VERSION "dbc-export 1 2026.26.6.5"

NS_ :

BS_:

BU_: APP APS BMS CC CMP CMPD CP DAS DI DIF DIR EPBL EPBR EVSE FC GTW HCML HCMR HVP ICR PCS PCS2 PLG PM PMF PMR PTC SCCM SCM SCS SDCR TAS UMC V2G VC VCBATT VCBATT0 VCBATT1 VCBATT2 VCFRONT VCFRONT1 VCFRONT2 VCLEFT VCRIGHT VCSEC

BO_ 537 VCSEC_TPMSData: 7 VCSEC
 SG_ VCSEC_TPMSDataIndex M : 0|3@1+ (1,0) [0|7] "" Vector__XXX
 SG_ VCSEC_TPMSCapabilityPressureInAd m0 : 3|1@1+ (1,0) [0|1] "" Vector__XXX
 SG_ VCSEC_TPMSCapabilityConfigurable m0 : 4|1@1+ (1,0) [0|1] "" Vector__XXX
 SG_ VCSEC_TPMSPressureRateOfChange0 m0 : 5|10@1- (0.02,0) [-10.24|10.22] "kPa/S" Vector__XXX
 SG_ VCSEC_TPMSPressure0 m0 : 15|9@1+ (0.025,0) [0|12.75] "bar" Vector__XXX
 SG_ VCSEC_TPMSTemperature0 m0 : 24|8@1+ (1,-40) [-40|214] "degC" Vector__XXX
 SG_ VCSEC_TPMSBatVoltage0 m0 : 32|8@1+ (0.01,1.5) [1.5|4.04] "V" Vector__XXX
 SG_ VCSEC_TPMSLocation0 m0 : 40|3@1+ (1,0) [0|7] "" Vector__XXX
 SG_ VCSEC_TPMSTemperatureCompensated m0 : 43|9@1+ (0.025,0) [0|12.75] "bar" Vector__XXX
 SG_ VCSEC_TPMSCapabilityPressur_0001 m1 : 3|1@1+ (1,0) [0|1] "" Vector__XXX
 SG_ VCSEC_TPMSCapabilityConfigu_0001 m1 : 4|1@1+ (1,0) [0|1] "" Vector__XXX
 SG_ VCSEC_TPMSPressureRateOfChange1 m1 : 5|10@1- (0.02,0) [-10.24|10.22] "kPa/S" Vector__XXX
 SG_ VCSEC_TPMSPressure1 m1 : 15|9@1+ (0.025,0) [0|12.75] "bar" Vector__XXX
 SG_ VCSEC_TPMSTemperature1 m1 : 24|8@1+ (1,-40) [-40|214] "degC" Vector__XXX
 SG_ VCSEC_TPMSBatVoltage1 m1 : 32|8@1+ (0.01,1.5) [1.5|4.04] "V" Vector__XXX
 SG_ VCSEC_TPMSLocation1 m1 : 40|3@1+ (1,0) [0|7] "" Vector__XXX
 SG_ VCSEC_TPMSTemperatureCompen_0001 m1 : 43|9@1+ (0.025,0) [0|12.75] "bar" Vector__XXX
 SG_ VCSEC_TPMSCapabilityPressur_0002 m2 : 3|1@1+ (1,0) [0|1] "" Vector__XXX
 SG_ VCSEC_TPMSCapabilityConfigu_0002 m2 : 4|1@1+ (1,0) [0|1] "" Vector__XXX
 SG_ VCSEC_TPMSPressureRateOfChange2 m2 : 5|10@1- (0.02,0) [-10.24|10.22] "kPa/S" Vector__XXX
 SG_ VCSEC_TPMSPressure2 m2 : 15|9@1+ (0.025,0) [0|12.75] "bar" Vector__XXX
 SG_ VCSEC_TPMSTemperature2 m2 : 24|8@1+ (1,-40) [-40|214] "degC" Vector__XXX
 SG_ VCSEC_TPMSBatVoltage2 m2 : 32|8@1+ (0.01,1.5) [1.5|4.04] "V" Vector__XXX
 SG_ VCSEC_TPMSLocation2 m2 : 40|3@1+ (1,0) [0|7] "" Vector__XXX
 SG_ VCSEC_TPMSTemperatureCompen_0002 m2 : 43|9@1+ (0.025,0) [0|12.75] "bar" Vector__XXX
 SG_ VCSEC_TPMSCapabilityPressur_0003 m3 : 3|1@1+ (1,0) [0|1] "" Vector__XXX
 SG_ VCSEC_TPMSCapabilityConfigu_0003 m3 : 4|1@1+ (1,0) [0|1] "" Vector__XXX
 SG_ VCSEC_TPMSPressureRateOfChange3 m3 : 5|10@1- (0.02,0) [-10.24|10.22] "kPa/S" Vector__XXX
 SG_ VCSEC_TPMSPressure3 m3 : 15|9@1+ (0.025,0) [0|12.75] "bar" Vector__XXX
 SG_ VCSEC_TPMSTemperature3 m3 : 24|8@1+ (1,-40) [-40|214] "degC" Vector__XXX
 SG_ VCSEC_TPMSBatVoltage3 m3 : 32|8@1+ (0.01,1.5) [1.5|4.04] "V" Vector__XXX
 SG_ VCSEC_TPMSLocation3 m3 : 40|3@1+ (1,0) [0|7] "" Vector__XXX
 SG_ VCSEC_TPMSTemperatureCompen_0003 m3 : 43|9@1+ (0.025,0) [0|12.75] "bar" Vector__XXX
 SG_ VCSEC_TPMSRecommendedColdPressur m4 : 8|8@1+ (0.025,0) [0|6.35] "bar" Vector__XXX
 SG_ VCSEC_TPMSRecommendedColdPr_0001 m4 : 16|8@1+ (0.025,0) [0|6.35] "bar" Vector__XXX
 SG_ VCSEC_TPMSFeature0 m4 : 24|3@1+ (1,0) [0|7] "" Vector__XXX
 SG_ VCSEC_TPMSFeature1 m4 : 27|3@1+ (1,0) [0|7] "" Vector__XXX
 SG_ VCSEC_TPMSFeature0Count m4 : 32|4@1+ (1,0) [0|15] "" Vector__XXX
 SG_ VCSEC_TPMSFeature0TimeS m4 : 36|11@1+ (1,0) [0|2047] "" Vector__XXX
 SG_ VCSEC_TPMSAutonomyStatus m5 : 3|2@1+ (1,0) [0|3] "" Vector__XXX
 SG_ VCSEC_TPMSAutonomyStatusMIATimeS m5 : 5|9@1+ (1,0) [0|511] "" Vector__XXX
 SG_ VCSEC_TPMSLastKnownPressureFL m5 : 16|8@1+ (0.025,0) [0|6.35] "bar" Vector__XXX
 SG_ VCSEC_TPMSLastKnownPressureFR m5 : 24|8@1+ (0.025,0) [0|6.35] "bar" Vector__XXX
 SG_ VCSEC_TPMSLastKnownPressureRL m5 : 32|8@1+ (0.025,0) [0|6.35] "bar" Vector__XXX
 SG_ VCSEC_TPMSLastKnownPressureRR m5 : 40|8@1+ (0.025,0) [0|6.35] "bar" Vector__XXX

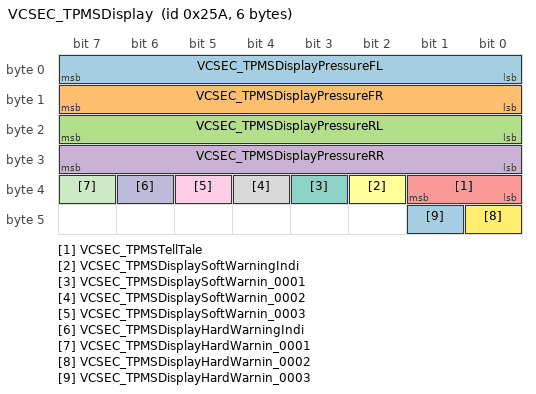
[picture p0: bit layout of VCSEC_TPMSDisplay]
BO_ 602 VCSEC_TPMSDisplay: 6 VCSEC
 SG_ VCSEC_TPMSDisplayPressureFL : 0|8@1+ (0.025,0) [0|6.35] "bar" Vector__XXX
 SG_ VCSEC_TPMSDisplayPressureFR : 8|8@1+ (0.025,0) [0|6.35] "bar" Vector__XXX
 SG_ VCSEC_TPMSDisplayPressureRL : 16|8@1+ (0.025,0) [0|6.35] "bar" Vector__XXX
 SG_ VCSEC_TPMSDisplayPressureRR : 24|8@1+ (0.025,0) [0|6.35] "bar" Vector__XXX
 SG_ VCSEC_TPMSTellTale : 32|2@1+ (1,0) [0|3] "" Vector__XXX
 SG_ VCSEC_TPMSDisplaySoftWarningIndi : 34|1@1+ (1,0) [0|1] "" Vector__XXX
 SG_ VCSEC_TPMSDisplaySoftWarnin_0001 : 35|1@1+ (1,0) [0|1] "" Vector__XXX
 SG_ VCSEC_TPMSDisplaySoftWarnin_0002 : 36|1@1+ (1,0) [0|1] "" Vector__XXX
 SG_ VCSEC_TPMSDisplaySoftWarnin_0003 : 37|1@1+ (1,0) [0|1] "" Vector__XXX
 SG_ VCSEC_TPMSDisplayHardWarningIndi : 38|1@1+ (1,0) [0|1] "" Vector__XXX
 SG_ VCSEC_TPMSDisplayHardWarnin_0001 : 39|1@1+ (1,0) [0|1] "" Vector__XXX
 SG_ VCSEC_TPMSDisplayHardWarnin_0002 : 40|1@1+ (1,0) [0|1] "" Vector__XXX
 SG_ VCSEC_TPMSDisplayHardWarnin_0003 : 41|1@1+ (1,0) [0|1] "" Vector__XXX

BO_ 570 VCSEC_TPMSStatus: 8 VCSEC
 SG_ VCSEC_TPMSStatusIndex M : 0|6@1+ (1,0) [0|63] "" Vector__XXX
 SG_ VCSEC_TPMSSystemState : 6|1@1+ (1,0) [0|1] "" Vector__XXX
 SG_ VCSEC_TPMSSensorMACAddress0 m0 : 8|48@1+ (1,0) [0|281474976710655] "" Vector__XXX
 SG_ VCSEC_TPMSSensorMACAddress1 m1 : 8|48@1+ (1,0) [0|281474976710655] "" Vector__XXX
 SG_ VCSEC_TPMSSensorMACAddress2 m2 : 8|48@1+ (1,0) [0|281474976710655] "" Vector__XXX
 SG_ VCSEC_TPMSSensorMACAddress3 m3 : 8|48@1+ (1,0) [0|281474976710655] "" Vector__XXX
 SG_ VCSEC_BLEUnsuccessfulConnEventRa m5 : 8|10@1+ (0.08,0) [0|81.76] "%" Vector__XXX
 SG_ VCSEC_BLEUnsuccessfulConnEv_0001 m7 : 8|10@1+ (0.08,0) [0|81.76] "%" Vector__XXX
 SG_ VCSEC_BLEUnsuccessfulConnEv_0002 m9 : 8|10@1+ (0.08,0) [0|81.76] "%" Vector__XXX
 SG_ VCSEC_BLEUnsuccessfulConnEv_0003 m11 : 8|10@1+ (0.08,0) [0|81.76] "%" Vector__XXX
 SG_ VCSEC_TPMSSensorTIAppCRC0 m12 : 8|32@1+ (1,0) [1|4294967295] "" Vector__XXX
 SG_ VCSEC_TPMSSensorMLXAppCRC0 m12 : 40|24@1+ (1,0) [1|16777215] "" Vector__XXX
 SG_ VCSEC_TPMSSensorTIAppCRC1 m13 : 8|32@1+ (1,0) [1|4294967295] "" Vector__XXX
 SG_ VCSEC_TPMSSensorMLXAppCRC1 m13 : 40|24@1+ (1,0) [1|16777215] "" Vector__XXX
 SG_ VCSEC_TPMSSensorTIAppCRC2 m14 : 8|32@1+ (1,0) [1|4294967295] "" Vector__XXX
 SG_ VCSEC_TPMSSensorMLXAppCRC2 m14 : 40|24@1+ (1,0) [1|16777215] "" Vector__XXX
 SG_ VCSEC_TPMSSensorTIAppCRC3 m15 : 8|32@1+ (1,0) [1|4294967295] "" Vector__XXX
 SG_ VCSEC_TPMSSensorMLXAppCRC3 m15 : 40|24@1+ (1,0) [1|16777215] "" Vector__XXX
 SG_ VCSEC_TPMStotalAwakeTime0 m20 : 8|32@1+ (1,0) [0|4294967295] "" Vector__XXX
 SG_ VCSEC_TPMSTrimAdjusted0 m20 : 40|1@1+ (1,0) [0|1] "" Vector__XXX
 SG_ VCSEC_TPMSGenealogySensorState0 m20 : 41|3@1+ (1,0) [0|7] "" Vector__XXX
 SG_ VCSEC_TPMSSensorType0 m20 : 44|3@1+ (1,0) [0|7] "" Vector__XXX
 SG_ VCSEC_TPMStotalAwakeTime1 m21 : 8|32@1+ (1,0) [0|4294967295] "" Vector__XXX
 SG_ VCSEC_TPMSTrimAdjusted1 m21 : 40|1@1+ (1,0) [0|1] "" Vector__XXX
 SG_ VCSEC_TPMSGenealogySensorState1 m21 : 41|3@1+ (1,0) [0|7] "" Vector__XXX
 SG_ VCSEC_TPMSSensorType1 m21 : 44|3@1+ (1,0) [0|7] "" Vector__XXX
 SG_ VCSEC_TPMStotalAwakeTime2 m22 : 8|32@1+ (1,0) [0|4294967295] "" Vector__XXX
 SG_ VCSEC_TPMSTrimAdjusted2 m22 : 40|1@1+ (1,0) [0|1] "" Vector__XXX
 SG_ VCSEC_TPMSGenealogySensorState2 m22 : 41|3@1+ (1,0) [0|7] "" Vector__XXX
 SG_ VCSEC_TPMSSensorType2 m22 : 44|3@1+ (1,0) [0|7] "" Vector__XXX
 SG_ VCSEC_TPMStotalAwakeTime3 m23 : 8|32@1+ (1,0) [0|4294967295] "" Vector__XXX
 SG_ VCSEC_TPMSTrimAdjusted3 m23 : 40|1@1+ (1,0) [0|1] "" Vector__XXX
 SG_ VCSEC_TPMSGenealogySensorState3 m23 : 41|3@1+ (1,0) [0|7] "" Vector__XXX
 SG_ VCSEC_TPMSSensorType3 m23 : 44|3@1+ (1,0) [0|7] "" Vector__XXX
 SG_ VCSEC_TPMSSensor0Hash m33 : 8|28@1+ (1,0) [0|268435455] "" Vector__XXX
 SG_ VCSEC_TPMSSensor1Hash m33 : 36|28@1+ (1,0) [0|268435455] "" Vector__XXX
 SG_ VCSEC_TPMSSensor2Hash m34 : 8|28@1+ (1,0) [0|268435455] "" Vector__XXX
 SG_ VCSEC_TPMSSensor3Hash m34 : 36|28@1+ (1,0) [0|268435455] "" Vector__XXX
 SG_ VCSEC_TPMSLastLocationSensor0 m35 : 8|3@1+ (1,0) [0|7] "" Vector__XXX
 SG_ VCSEC_TPMSLastLocationSensor1 m35 : 11|3@1+ (1,0) [0|7] "" Vector__XXX
 SG_ VCSEC_TPMSLastLocationSensor2 m35 : 16|3@1+ (1,0) [0|7] "" Vector__XXX
 SG_ VCSEC_TPMSLastLocationSensor3 m35 : 19|3@1+ (1,0) [0|7] "" Vector__XXX
 SG_ VCSEC_TPMSTemperatureCompensated m36 : 8|8@1+ (0.01,1.5) [1.5|4.04] "V" Vector__XXX
 SG_ VCSEC_TPMSTemperatureCompen_0001 m36 : 16|8@1+ (0.01,1.5) [1.5|4.04] "V" Vector__XXX
 SG_ VCSEC_TPMSTemperatureCompen_0002 m36 : 24|8@1+ (0.01,1.5) [1.5|4.04] "V" Vector__XXX
 SG_ VCSEC_TPMSTemperatureCompen_0003 m36 : 32|8@1+ (0.01,1.5) [1.5|4.04] "V" Vector__XXX
 SG_ VCSEC_TPMSFilteredBatVoltage0 m37 : 8|8@1+ (0.01,1.5) [1.5|4.04] "V" Vector__XXX
 SG_ VCSEC_TPMSFilteredBatVoltage2 m37 : 16|8@1+ (0.01,1.5) [1.5|4.04] "V" Vector__XXX
 SG_ VCSEC_TPMSFilteredBatVoltage1 m37 : 24|8@1+ (0.01,1.5) [1.5|4.04] "V" Vector__XXX
 SG_ VCSEC_TPMSFilteredBatVoltage3 m37 : 32|8@1+ (0.01,1.5) [1.5|4.04] "V" Vector__XXX

BO_ 1067 VCSEC_UWBData: 8 VCSEC
 SG_ VCSEC_UWBEndpointIndex M : 0|3@1+ (1,0) [0|7] "" Vector__XXX
 SG_ VCSEC_UWBExpectedEndpointsActive m0 : 3|4@1+ (1,0) [0|15] "" Vector__XXX
 SG_ VCSEC_UWBExpectedEndpointsA_0001 m0 : 8|4@1+ (1,0) [0|15] "" Vector__XXX
 SG_ VCSEC_UWBExpectedEndpointsA_0002 m0 : 12|4@1+ (1,0) [0|15] "" Vector__XXX
 SG_ VCSEC_UWBExpectedEndpointsA_0003 m0 : 16|4@1+ (1,0) [0|15] "" Vector__XXX
 SG_ VCSEC_UWBRearRightDistance0 m0 : 20|12@1+ (1,0) [0|4094] "cm" Vector__XXX
 SG_ VCSEC_UWBRearRightDistance1 m0 : 32|12@1+ (1,0) [0|4094] "cm" Vector__XXX
 SG_ VCSEC_UWBRearRightDistance2 m0 : 44|12@1+ (1,0) [0|4094] "cm" Vector__XXX
 SG_ VCSEC_UWBLeftDistance3 m1 : 3|12@1+ (1,0) [0|4094] "cm" Vector__XXX
 SG_ VCSEC_UWBRightDistance3 m1 : 16|12@1+ (1,0) [0|4094] "cm" Vector__XXX
 SG_ VCSEC_UWBRearRightDistance3 m1 : 28|12@1+ (1,0) [0|4094] "cm" Vector__XXX
 SG_ VCSEC_UWBRearLeftDistance3 m1 : 40|12@1+ (1,0) [0|4094] "cm" Vector__XXX
 SG_ VCSEC_UWBCenterDistance3 m1 : 52|12@1+ (1,0) [0|4094] "cm" Vector__XXX
 SG_ VCSEC_UWBLeftDistance2 m2 : 3|12@1+ (1,0) [0|4094] "cm" Vector__XXX
 SG_ VCSEC_UWBRightDistance2 m2 : 16|12@1+ (1,0) [0|4094] "cm" Vector__XXX
 SG_ VCSEC_UWBRearDistance2 m2 : 28|12@1+ (1,0) [0|4094] "cm" Vector__XXX
 SG_ VCSEC_UWBRearLeftDistance2 m2 : 40|12@1+ (1,0) [0|4094] "cm" Vector__XXX
 SG_ VCSEC_UWBCenterDistance2 m2 : 52|12@1+ (1,0) [0|4094] "cm" Vector__XXX
 SG_ VCSEC_UWBLeftDistance1 m3 : 3|12@1+ (1,0) [0|4094] "cm" Vector__XXX
 SG_ VCSEC_UWBRightDistance1 m3 : 16|12@1+ (1,0) [0|4094] "cm" Vector__XXX
 SG_ VCSEC_UWBRearDistance1 m3 : 28|12@1+ (1,0) [0|4094] "cm" Vector__XXX
 SG_ VCSEC_UWBRearLeftDistance1 m3 : 40|12@1+ (1,0) [0|4094] "cm" Vector__XXX
 SG_ VCSEC_UWBCenterDistance1 m3 : 52|12@1+ (1,0) [0|4094] "cm" Vector__XXX
 SG_ VCSEC_UWBLeftDistance0 m4 : 3|12@1+ (1,0) [0|4094] "cm" Vector__XXX
 SG_ VCSEC_UWBRightDistance0 m4 : 16|12@1+ (1,0) [0|4094] "cm" Vector__XXX
 SG_ VCSEC_UWBRearDistance0 m4 : 28|12@1+ (1,0) [0|4094] "cm" Vector__XXX
 SG_ VCSEC_UWBRearLeftDistance0 m4 : 40|12@1+ (1,0) [0|4094] "cm" Vector__XXX
 SG_ VCSEC_UWBCenterDistance0 m4 : 52|12@1+ (1,0) [0|4094] "cm" Vector__XXX

BO_ 761 VCSEC_additionalAuthInfo: 8 VCSEC
 SG_ VCSEC_activeKeyDebug : 2|5@1+ (1,0) [0|31] "" Vector__XXX
 SG_ VCSEC_bleChannelDisconnected : 7|4@1+ (1,0) [0|15] "" Vector__XXX
 SG_ VCSEC_bleDisconnectionReason : 11|8@1+ (1,0) [0|255] "" Vector__XXX
 SG_ VCSEC_bleConnetionAttemptWLEntry : 19|5@1+ (1,0) [0|31] "" Vector__XXX
 SG_ VCSEC_AdditionalAuthInfoIndex M : 27|3@1+ (1,0) [0|7] "" Vector__XXX
 SG_ VCSEC_activeKeyReason m0 : 24|3@1+ (1,0) [0|7] "" Vector__XXX
 SG_ VCSEC_activeKeySHA1 m0 : 32|32@1+ (1,0) [0|4294967295] "" Vector__XXX
 SG_ VCSEC_algoUsedForSummonRange0 m1 : 0|1@1+ (1,0) [0|1] "" Vector__XXX
 SG_ VCSEC_keyWithinSummonRange0 m1 : 32|32@1+ (1,0) [0|4294967295] "" Vector__XXX
 SG_ VCSEC_algoUsedForSummonRange1 m2 : 0|1@1+ (1,0) [0|1] "" Vector__XXX
 SG_ VCSEC_keyWithinSummonRange1 m2 : 32|32@1+ (1,0) [0|4294967295] "" Vector__XXX
 SG_ VCSEC_algoUsedForSummonRange2 m3 : 0|1@1+ (1,0) [0|1] "" Vector__XXX
 SG_ VCSEC_keyWithinSummonRange2 m3 : 32|32@1+ (1,0) [0|4294967295] "" Vector__XXX
 SG_ VCSEC_BLEDeviceWithinSummonRange m4 : 32|32@1+ (1,0) [0|4294967295] "" Vector__XXX
 SG_ VCSEC_algoUWBInteriorPresence m5 : 0|1@1+ (1,0) [0|1] "" Vector__XXX
 SG_ VCSEC_frunkOpenSuggestionRespons m5 : 24|3@1+ (1,0) [0|7] "" Vector__XXX
 SG_ VCSEC_NFCAuthFromBPillarFormFact m5 : 32|3@1+ (1,0) [0|7] "" Vector__XXX
 SG_ VCSEC_NFCAuthFromCenterConsoleFo m5 : 35|3@1+ (1,0) [0|7] "" Vector__XXX
 SG_ VCSEC_trunkOpenSuggestionRespons m5 : 40|3@1+ (1,0) [0|7] "" Vector__XXX
 SG_ VCSEC_algoTrunkSuggestionRaw m5 : 43|1@1+ (1,0) [0|1] "" Vector__XXX
 SG_ VCSEC_algoTrunkSuggestionProc m5 : 44|1@1+ (1,0) [0|1] "" Vector__XXX
 SG_ VCSEC_algoTrunkSuggestionRearmAl m5 : 45|1@1+ (1,0) [0|1] "" Vector__XXX
 SG_ VCSEC_algoFrunkSuggestionRaw m5 : 46|1@1+ (1,0) [0|1] "" Vector__XXX
 SG_ VCSEC_algoFrunkSuggestionProc m5 : 47|1@1+ (1,0) [0|1] "" Vector__XXX
 SG_ VCSEC_algoFrunkSuggestionRearmAl m5 : 48|1@1+ (1,0) [0|1] "" Vector__XXX

BO_ 1328 VCSEC_alertLog: 8 VCSEC
 SG_ VCSEC_alertID M : 0|10@1+ (1,0) [0|1023] "" Vector__XXX
 SG_ VCSEC_alertState : 15|1@1+ (1,0) [0|1] "" Vector__XXX
 SG_ VCSEC_a001_InternalWatchdog m1 : 16|1@1+ (1,0) [0|1] "" Vector__XXX
 SG_ VCSEC_a010_UnderVoltageDetected m10 : 16|1@1+ (1,0) [0|1] "" Vector__XXX
 SG_ VCSEC_a010_UnderVoltageTimeout m10 : 17|1@1+ (1,0) [0|1] "" Vector__XXX
 SG_ VCSEC_a015_NVMMMemOverflow m15 : 16|1@1+ (1,0) [0|1] "" Vector__XXX
 SG_ VCSEC_a015_NVMMFilesystemError m15 : 17|1@1+ (1,0) [0|1] "" Vector__XXX
 SG_ VCSEC_a015_NVMMRecordIDError m15 : 18|1@1+ (1,0) [0|1] "" Vector__XXX
 SG_ VCSEC_a057_VEH_cpControl m57 : 16|1@1+ (1,0) [0|1] "" Vector__XXX
 SG_ VCSEC_a059_voltageDrop m59 : 16|12@1+ (0.005443676,0) [0|22.29185322] "V" Vector__XXX
 SG_ VCSEC_a059_resistanceEstimate m59 : 28|12@1+ (0.00244,0) [0|9.9918] "Ohms" Vector__XXX
 SG_ VCSEC_a059_current m59 : 40|12@1+ (0.05,0) [0|204.75] "A" Vector__XXX
 SG_ VCSEC_a063_switchChannel m63 : 16|8@1+ (1,0) [0|255] "" Vector__XXX
 SG_ VCSEC_a063_switchType m63 : 24|8@1+ (1,0) [0|255] "" Vector__XXX
 SG_ VCSEC_a063_ADCVoltage m63 : 32|8@1+ (0.025,0) [0|6.375] "V" Vector__XXX
 SG_ VCSEC_a063_disconnected m63 : 40|1@1+ (1,0) [0|1] "" Vector__XXX
 SG_ VCSEC_a063_indeterminate m63 : 41|1@1+ (1,0) [0|1] "" Vector__XXX
 SG_ VCSEC_a063_stuckActive m63 : 42|1@1+ (1,0) [0|1] "" Vector__XXX
 SG_ VCSEC_a063_faulted m63 : 43|1@1+ (1,0) [0|1] "" Vector__XXX
 SG_ VCSEC_a082_RIPC_epbPrivateState m82 : 16|1@1+ (1,0) [0|1] "" Vector__XXX
 SG_ VCSEC_a082_RIPC_remoteHSD m82 : 17|1@1+ (1,0) [0|1] "" Vector__XXX
 SG_ VCSEC_a082_RIPC_railStatus m82 : 18|1@1+ (1,0) [0|1] "" Vector__XXX
 SG_ VCSEC_a082_RIPC_remoteMux m82 : 19|1@1+ (1,0) [0|1] "" Vector__XXX
 SG_ VCSEC_a083_LIPC_epbPrivateState m83 : 16|1@1+ (1,0) [0|1] "" Vector__XXX
 SG_ VCSEC_a083_LIPC_remoteHSD m83 : 17|1@1+ (1,0) [0|1] "" Vector__XXX
 SG_ VCSEC_a083_LIPC_railStatus m83 : 18|1@1+ (1,0) [0|1] "" Vector__XXX
 SG_ VCSEC_a083_LIPC_HSDFaults m83 : 19|1@1+ (1,0) [0|1] "" Vector__XXX
 SG_ VCSEC_a084_CH_StatusC m84 : 16|1@1+ (1,0) [0|1] "" Vector__XXX
 SG_ VCSEC_a085_PARTY_buttonStatus m85 : 16|1@1+ (1,0) [0|1] "" Vector__XXX
 SG_ VCSEC_a086_VEH_LVBMS_statusHigh m86 : 16|1@1+ (1,0) [0|1] "" Vector__XXX
 SG_ VCSEC_a086_VEH_LVBMS_statusLow m86 : 17|1@1+ (1,0) [0|1] "" Vector__XXX
 SG_ VCSEC_a086_VEH_status m86 : 18|1@1+ (1,0) [0|1] "" Vector__XXX
 SG_ VCSEC_a086_VEH_12VBatteryStatus m86 : 19|1@1+ (1,0) [0|1] "" Vector__XXX
 SG_ VCSEC_a086_VEH_LVPowerState m86 : 20|1@1+ (1,0) [0|1] "" Vector__XXX
 SG_ VCSEC_a086_VEH_lightStatus m86 : 21|1@1+ (1,0) [0|1] "" Vector__XXX
 SG_ VCSEC_a086_VEH_systemStatus m86 : 22|1@1+ (1,0) [0|1] "" Vector__XXX
 SG_ VCSEC_a086_VEH_thermalStatus m86 : 23|1@1+ (1,0) [0|1] "" Vector__XXX
 SG_ VCSEC_a086_VEH_vehNm m86 : 24|1@1+ (1,0) [0|1] "" Vector__XXX
 SG_ VCSEC_a087_VEH_temperature m87 : 16|1@1+ (1,0) [0|1] "" Vector__XXX
 SG_ VCSEC_a087_VEH_thermalControl m87 : 17|1@1+ (1,0) [0|1] "" Vector__XXX
 SG_ VCSEC_a087_VEH_torque m87 : 18|1@1+ (1,0) [0|1] "" Vector__XXX
 SG_ VCSEC_a087_VEH_status m87 : 19|1@1+ (1,0) [0|1] "" Vector__XXX
 SG_ VCSEC_a087_PARTY_torque m87 : 20|1@1+ (1,0) [0|1] "" Vector__XXX
 SG_ VCSEC_a087_PARTY_status m87 : 21|1@1+ (1,0) [0|1] "" Vector__XXX
 SG_ VCSEC_a087_PARTY_temperature m87 : 22|1@1+ (1,0) [0|1] "" Vector__XXX
 SG_ VCSEC_a087_PARTY_thermalControl m87 : 23|1@1+ (1,0) [0|1] "" Vector__XXX
 SG_ VCSEC_a087_VEH_motorStatus m87 : 24|1@1+ (1,0) [0|1] "" Vector__XXX
 SG_ VCSEC_a088_VEH_temperature m88 : 16|1@1+ (1,0) [0|1] "" Vector__XXX
 SG_ VCSEC_a088_VEH_thermalControl m88 : 17|1@1+ (1,0) [0|1] "" Vector__XXX
 SG_ VCSEC_a088_VEH_torque m88 : 18|1@1+ (1,0) [0|1] "" Vector__XXX
 SG_ VCSEC_a088_VEH_status m88 : 19|1@1+ (1,0) [0|1] "" Vector__XXX
 SG_ VCSEC_a088_PARTY_torque m88 : 20|1@1+ (1,0) [0|1] "" Vector__XXX
 SG_ VCSEC_a088_PARTY_status m88 : 21|1@1+ (1,0) [0|1] "" Vector__XXX
 SG_ VCSEC_a088_PARTY_temperature m88 : 22|1@1+ (1,0) [0|1] "" Vector__XXX
 SG_ VCSEC_a088_PARTY_thermalControl m88 : 23|1@1+ (1,0) [0|1] "" Vector__XXX
 SG_ VCSEC_a088_VEH_motorStatus m88 : 24|1@1+ (1,0) [0|1] "" Vector__XXX
 SG_ VCSEC_a089_PARTY_party1 m89 : 16|1@1+ (1,0) [0|1] "" Vector__XXX
 SG_ VCSEC_a089_PARTY_status m89 : 17|1@1+ (1,0) [0|1] "" Vector__XXX
 SG_ VCSEC_a089_VEH_status m89 : 18|1@1+ (1,0) [0|1] "" Vector__XXX
 SG_ VCSEC_a089_BDY_party1 m89 : 19|1@1+ (1,0) [0|1] "" Vector__XXX
 SG_ VCSEC_a089_BDY_status m89 : 20|1@1+ (1,0) [0|1] "" Vector__XXX
 SG_ VCSEC_a089_CH_status m89 : 21|1@1+ (1,0) [0|1] "" Vector__XXX
 SG_ VCSEC_a089_CH_party1 m89 : 22|1@1+ (1,0) [0|1] "" Vector__XXX
 SG_ VCSEC_a089_CH_party3 m89 : 23|1@1+ (1,0) [0|1] "" Vector__XXX
 SG_ VCSEC_a089_VEH_party1 m89 : 24|1@1+ (1,0) [0|1] "" Vector__XXX
 SG_ VCSEC_a089_VEH_party3 m89 : 25|1@1+ (1,0) [0|1] "" Vector__XXX
 SG_ VCSEC_a091_VEH_faultsAndExtras m91 : 16|1@1+ (1,0) [0|1] "" Vector__XXX
 SG_ VCSEC_a091_VEH_info m91 : 17|1@1+ (1,0) [0|1] "" Vector__XXX
 SG_ VCSEC_a091_VEH_state m91 : 18|1@1+ (1,0) [0|1] "" Vector__XXX
 SG_ VCSEC_a092_VEH_restraintStatus m92 : 16|1@1+ (1,0) [0|1] "" Vector__XXX
 SG_ VCSEC_a092_VEH_switchStatus m92 : 17|1@1+ (1,0) [0|1] "" Vector__XXX
 SG_ VCSEC_a092_VEH_seatStatus2 m92 : 18|1@1+ (1,0) [0|1] "" Vector__XXX
 SG_ VCSEC_a092_VEH_vehNm m92 : 19|1@1+ (1,0) [0|1] "" Vector__XXX
 SG_ VCSEC_a093_VEH_restraintStatus m93 : 16|1@1+ (1,0) [0|1] "" Vector__XXX
 SG_ VCSEC_a093_VEH_switchStatus m93 : 17|1@1+ (1,0) [0|1] "" Vector__XXX
 SG_ VCSEC_a093_VEH_seatStatus2 m93 : 18|1@1+ (1,0) [0|1] "" Vector__XXX
 SG_ VCSEC_a093_VEH_vehNm m93 : 19|1@1+ (1,0) [0|1] "" Vector__XXX
 SG_ VCSEC_a094_VEH_sysStatus m94 : 16|1@1+ (1,0) [0|1] "" Vector__XXX
 SG_ VCSEC_a094_PARTY_sysStatus m94 : 17|1@1+ (1,0) [0|1] "" Vector__XXX
 SG_ VCSEC_a094_CH_sysStatus m94 : 18|1@1+ (1,0) [0|1] "" Vector__XXX
 SG_ VCSEC_a095_PT_ptNm m95 : 16|1@1+ (1,0) [0|1] "" Vector__XXX
 SG_ VCSEC_a095_PT_status m95 : 17|1@1+ (1,0) [0|1] "" Vector__XXX
 SG_ VCSEC_a096_VEH_status m96 : 16|1@1+ (1,0) [0|1] "" Vector__XXX
 SG_ VCSEC_a096_CH_status m96 : 17|1@1+ (1,0) [0|1] "" Vector__XXX
 SG_ VCSEC_a097_VEH_HVStatus m97 : 16|1@1+ (1,0) [0|1] "" Vector__XXX
 SG_ VCSEC_a097_VEH_state m97 : 17|1@1+ (1,0) [0|1] "" Vector__XXX
 SG_ VCSEC_a098_CH_torque m98 : 16|1@1+ (1,0) [0|1] "" Vector__XXX
 SG_ VCSEC_a098_VEH_hvStatus m98 : 17|1@1+ (1,0) [0|1] "" Vector__XXX
 SG_ VCSEC_a098_VEH_status m98 : 18|1@1+ (1,0) [0|1] "" Vector__XXX
 SG_ VCSEC_a098_VEH_thermalControl m98 : 19|1@1+ (1,0) [0|1] "" Vector__XXX
 SG_ VCSEC_a098_VEH_temperature m98 : 20|1@1+ (1,0) [0|1] "" Vector__XXX
 SG_ VCSEC_a098_VEH_torque m98 : 21|1@1+ (1,0) [0|1] "" Vector__XXX
 SG_ VCSEC_a098_PARTY_status m98 : 22|1@1+ (1,0) [0|1] "" Vector__XXX
 SG_ VCSEC_a098_PARTY_temperature m98 : 23|1@1+ (1,0) [0|1] "" Vector__XXX
 SG_ VCSEC_a098_PARTY_thermalControl m98 : 24|1@1+ (1,0) [0|1] "" Vector__XXX
 SG_ VCSEC_a098_PARTY_torque m98 : 25|1@1+ (1,0) [0|1] "" Vector__XXX
 SG_ VCSEC_a098_PT_thermalControl m98 : 26|1@1+ (1,0) [0|1] "" Vector__XXX
 SG_ VCSEC_a098_PT_temperature m98 : 27|1@1+ (1,0) [0|1] "" Vector__XXX
 SG_ VCSEC_a098_PARTY_motorStatus m98 : 28|1@1+ (1,0) [0|1] "" Vector__XXX
 SG_ VCSEC_a098_VEH_motorStatus m98 : 29|1@1+ (1,0) [0|1] "" Vector__XXX
 SG_ VCSEC_a099_VEH_oocStatus m99 : 16|1@1+ (1,0) [0|1] "" Vector__XXX
 SG_ VCSEC_a100_VEH m100 : 16|1@1+ (1,0) [0|1] "" Vector__XXX
 SG_ VCSEC_a100_PARTY m100 : 17|1@1+ (1,0) [0|1] "" Vector__XXX
 SG_ VCSEC_a100_PT m100 : 18|1@1+ (1,0) [0|1] "" Vector__XXX
 SG_ VCSEC_a100_CH m100 : 19|1@1+ (1,0) [0|1] "" Vector__XXX
 SG_ VCSEC_a100_OBD m100 : 20|1@1+ (1,0) [0|1] "" Vector__XXX
 SG_ VCSEC_a101_VEH_state m101 : 16|1@1+ (1,0) [0|1] "" Vector__XXX
 SG_ VCSEC_a101_PARTY_locState m101 : 17|1@1+ (1,0) [0|1] "" Vector__XXX
 SG_ VCSEC_a101_LIPC_externalWatchdog m101 : 18|1@1+ (1,0) [0|1] "" Vector__XXX
 SG_ VCSEC_a101_VEH_locState m101 : 19|1@1+ (1,0) [0|1] "" Vector__XXX
 SG_ VCSEC_a101_BDY_locState m101 : 20|1@1+ (1,0) [0|1] "" Vector__XXX
 SG_ VCSEC_a102_VEH_faultsAndExtras m102 : 16|1@1+ (1,0) [0|1] "" Vector__XXX
 SG_ VCSEC_a102_VEH_feedbackStatus m102 : 17|1@1+ (1,0) [0|1] "" Vector__XXX
 SG_ VCSEC_a102_VEH_sensorStatus m102 : 18|1@1+ (1,0) [0|1] "" Vector__XXX
 SG_ VCSEC_a102_VEH_rods m102 : 19|1@1+ (1,0) [0|1] "" Vector__XXX
 SG_ VCSEC_a103_VEH_hvsNm m103 : 16|1@1+ (1,0) [0|1] "" Vector__XXX
 SG_ VCSEC_a103_VEH_vehNm m103 : 17|1@1+ (1,0) [0|1] "" Vector__XXX
 SG_ VCSEC_a103_VEH_status m103 : 18|1@1+ (1,0) [0|1] "" Vector__XXX
 SG_ VCSEC_a103_PT_ptNm m103 : 19|1@1+ (1,0) [0|1] "" Vector__XXX
 SG_ VCSEC_a103_PT_status m103 : 20|1@1+ (1,0) [0|1] "" Vector__XXX
 SG_ VCSEC_a103_VEH_evseStatus m103 : 21|1@1+ (1,0) [0|1] "" Vector__XXX
 SG_ VCSEC_a105_VEH_states m105 : 16|1@1+ (1,0) [0|1] "" Vector__XXX
 SG_ VCSEC_a105_VEH_chNm m105 : 17|1@1+ (1,0) [0|1] "" Vector__XXX
 SG_ VCSEC_a105_VEH_dampingStates m105 : 18|1@1+ (1,0) [0|1] "" Vector__XXX
 SG_ VCSEC_a106_VEH_dcdcStatus m106 : 16|1@1+ (1,0) [0|1] "" Vector__XXX
 SG_ VCSEC_a106_VEH_thermalControl m106 : 17|1@1+ (1,0) [0|1] "" Vector__XXX
 SG_ VCSEC_a106_VEH_dcdcRailStatus m106 : 18|1@1+ (1,0) [0|1] "" Vector__XXX
 SG_ VCSEC_a106_CH_dcdcRailStatus m106 : 19|1@1+ (1,0) [0|1] "" Vector__XXX
 SG_ VCSEC_a106_CH_alertMatrix m106 : 20|1@1+ (1,0) [0|1] "" Vector__XXX
 SG_ VCSEC_a107_VEH_hvsNm m107 : 16|1@1+ (1,0) [0|1] "" Vector__XXX
 SG_ VCSEC_a107_VEH_vehNm m107 : 17|1@1+ (1,0) [0|1] "" Vector__XXX
 SG_ VCSEC_a107_VEH_status m107 : 18|1@1+ (1,0) [0|1] "" Vector__XXX
 SG_ VCSEC_a107_VEH_thermalStatus m107 : 19|1@1+ (1,0) [0|1] "" Vector__XXX
 SG_ VCSEC_a107_VEH_bmbMinMax m107 : 20|1@1+ (1,0) [0|1] "" Vector__XXX
 SG_ VCSEC_a107_VEH_powerAvailable m107 : 21|1@1+ (1,0) [0|1] "" Vector__XXX
 SG_ VCSEC_a107_PT_ptNm m107 : 22|1@1+ (1,0) [0|1] "" Vector__XXX
 SG_ VCSEC_a107_PT_status m107 : 23|1@1+ (1,0) [0|1] "" Vector__XXX
 SG_ VCSEC_a107_PT_thermalStatus m107 : 24|1@1+ (1,0) [0|1] "" Vector__XXX
 SG_ VCSEC_a107_PT_socStatus m107 : 25|1@1+ (1,0) [0|1] "" Vector__XXX
 SG_ VCSEC_a107_VEH_socStatus m107 : 26|1@1+ (1,0) [0|1] "" Vector__XXX
 SG_ VCSEC_a107_VEH_packConfig m107 : 27|1@1+ (1,0) [0|1] "" Vector__XXX
 SG_ VCSEC_a107_VEH_energyStatus m107 : 28|1@1+ (1,0) [0|1] "" Vector__XXX
 SG_ VCSEC_a107_VEH_chargeInfo m107 : 29|1@1+ (1,0) [0|1] "" Vector__XXX
 SG_ VCSEC_a108_VEH_hvStatus m108 : 16|1@1+ (1,0) [0|1] "" Vector__XXX
 SG_ VCSEC_a108_VEH_temperature m108 : 17|1@1+ (1,0) [0|1] "" Vector__XXX
 SG_ VCSEC_a108_VEH_thermalControl m108 : 18|1@1+ (1,0) [0|1] "" Vector__XXX
 SG_ VCSEC_a108_VEH_torque m108 : 19|1@1+ (1,0) [0|1] "" Vector__XXX
 SG_ VCSEC_a108_VEH_status m108 : 20|1@1+ (1,0) [0|1] "" Vector__XXX
 SG_ VCSEC_a108_PARTY_torque m108 : 21|1@1+ (1,0) [0|1] "" Vector__XXX
 SG_ VCSEC_a108_PARTY_status m108 : 22|1@1+ (1,0) [0|1] "" Vector__XXX
 SG_ VCSEC_a108_PARTY_temperature m108 : 23|1@1+ (1,0) [0|1] "" Vector__XXX
 SG_ VCSEC_a108_PARTY_thermalControl m108 : 24|1@1+ (1,0) [0|1] "" Vector__XXX
 SG_ VCSEC_a108_PT_temperature m108 : 25|1@1+ (1,0) [0|1] "" Vector__XXX
 SG_ VCSEC_a108_PT_thermalControl m108 : 26|1@1+ (1,0) [0|1] "" Vector__XXX
 SG_ VCSEC_a108_PARTY_motorStatus m108 : 27|1@1+ (1,0) [0|1] "" Vector__XXX
 SG_ VCSEC_a108_VEH_motorStatus m108 : 28|1@1+ (1,0) [0|1] "" Vector__XXX
 SG_ VCSEC_a108_CH_torque m108 : 29|1@1+ (1,0) [0|1] "" Vector__XXX
 SG_ VCSEC_a110_VEH_carState m110 : 16|1@1+ (1,0) [0|1] "" Vector__XXX
 SG_ VCSEC_a110_VEH_carConfig m110 : 17|1@1+ (1,0) [0|1] "" Vector__XXX
 SG_ VCSEC_a110_VEH_time m110 : 18|1@1+ (1,0) [0|1] "" Vector__XXX
 SG_ VCSEC_a110_VEH_updateStatus m110 : 19|1@1+ (1,0) [0|1] "" Vector__XXX
 SG_ VCSEC_a110_VEH_vehNm m110 : 20|1@1+ (1,0) [0|1] "" Vector__XXX
 SG_ VCSEC_a110_VEH_mismatchFault m110 : 21|1@1+ (1,0) [0|1] "" Vector__XXX
 SG_ VCSEC_a110_VEH_vin m110 : 22|1@1+ (1,0) [0|1] "" Vector__XXX
 SG_ VCSEC_a110_VEH_bmpDebug m110 : 23|1@1+ (1,0) [0|1] "" Vector__XXX
 SG_ VCSEC_a110_VEH_gearControl m110 : 24|1@1+ (1,0) [0|1] "" Vector__XXX
 SG_ VCSEC_a110_VEH_canLogAvailabilit m110 : 25|1@1+ (1,0) [0|1] "" Vector__XXX
 SG_ VCSEC_a110_CH_airbagCutoffStatus m110 : 26|1@1+ (1,0) [0|1] "" Vector__XXX
 SG_ VCSEC_a110_CH_carConfig m110 : 27|1@1+ (1,0) [0|1] "" Vector__XXX
 SG_ VCSEC_a110_CH_carState m110 : 28|1@1+ (1,0) [0|1] "" Vector__XXX
 SG_ VCSEC_a110_CH_vin m110 : 29|1@1+ (1,0) [0|1] "" Vector__XXX
 SG_ VCSEC_a110_CH_chNm m110 : 30|1@1+ (1,0) [0|1] "" Vector__XXX
 SG_ VCSEC_a110_CH_epochTimeGtw m110 : 31|1@1+ (1,0) [0|1] "" Vector__XXX
 SG_ VCSEC_a110_PARTY_carConfig m110 : 32|1@1+ (1,0) [0|1] "" Vector__XXX
 SG_ VCSEC_a111_VEH_internalStatus m111 : 16|1@1+ (1,0) [0|1] "" Vector__XXX
 SG_ VCSEC_a111_VEH_status m111 : 17|1@1+ (1,0) [0|1] "" Vector__XXX
 SG_ VCSEC_a111_VEH_vehNm m111 : 18|1@1+ (1,0) [0|1] "" Vector__XXX
 SG_ VCSEC_a111_RIPC_LVPowerState m111 : 19|1@1+ (1,0) [0|1] "" Vector__XXX
 SG_ VCSEC_a111_RIPC_epbPrivateState m111 : 20|1@1+ (1,0) [0|1] "" Vector__XXX
 SG_ VCSEC_a111_RIPC_railStatus m111 : 21|1@1+ (1,0) [0|1] "" Vector__XXX
 SG_ VCSEC_a111_RIPC_remoteADC m111 : 22|1@1+ (1,0) [0|1] "" Vector__XXX
 SG_ VCSEC_a111_RIPC_switchStatus m111 : 23|1@1+ (1,0) [0|1] "" Vector__XXX
 SG_ VCSEC_a111_VEH_LVPowerState m111 : 24|1@1+ (1,0) [0|1] "" Vector__XXX
 SG_ VCSEC_a111_VEH_seatStatus m111 : 25|1@1+ (1,0) [0|1] "" Vector__XXX
 SG_ VCSEC_a111_PARTY_status m111 : 26|1@1+ (1,0) [0|1] "" Vector__XXX
 SG_ VCSEC_a111_CH_status m111 : 27|1@1+ (1,0) [0|1] "" Vector__XXX
 SG_ VCSEC_a112_VEH_internalStatus m112 : 16|1@1+ (1,0) [0|1] "" Vector__XXX
 SG_ VCSEC_a112_VEH_status m112 : 17|1@1+ (1,0) [0|1] "" Vector__XXX
 SG_ VCSEC_a112_VEH_vehNm m112 : 18|1@1+ (1,0) [0|1] "" Vector__XXX
 SG_ VCSEC_a112_LIPC_LVPowerState m112 : 19|1@1+ (1,0) [0|1] "" Vector__XXX
 SG_ VCSEC_a112_LIPC_epbPrivateState m112 : 20|1@1+ (1,0) [0|1] "" Vector__XXX
 SG_ VCSEC_a112_LIPC_railStatus m112 : 21|1@1+ (1,0) [0|1] "" Vector__XXX
 SG_ VCSEC_a112_LIPC_remoteADC m112 : 22|1@1+ (1,0) [0|1] "" Vector__XXX
 SG_ VCSEC_a112_LIPC_switchStatus m112 : 23|1@1+ (1,0) [0|1] "" Vector__XXX
 SG_ VCSEC_a112_VEH_LVPowerState m112 : 24|1@1+ (1,0) [0|1] "" Vector__XXX
 SG_ VCSEC_a112_PARTY_status m112 : 25|1@1+ (1,0) [0|1] "" Vector__XXX
 SG_ VCSEC_a112_CH_status m112 : 26|1@1+ (1,0) [0|1] "" Vector__XXX
 SG_ VCSEC_a114_PARTY_status m114 : 16|1@1+ (1,0) [0|1] "" Vector__XXX
 SG_ VCSEC_a114_PARTY_wheelSpeeds m114 : 17|1@1+ (1,0) [0|1] "" Vector__XXX
 SG_ VCSEC_a114_VEH_wheelSpeeds m114 : 18|1@1+ (1,0) [0|1] "" Vector__XXX
 SG_ VCSEC_a114_CH_wheelSpeeds m114 : 19|1@1+ (1,0) [0|1] "" Vector__XXX
 SG_ VCSEC_a114_PARTY_party3 m114 : 20|1@1+ (1,0) [0|1] "" Vector__XXX
 SG_ VCSEC_a114_VEH_party3 m114 : 21|1@1+ (1,0) [0|1] "" Vector__XXX
 SG_ VCSEC_a114_VEH_status m114 : 22|1@1+ (1,0) [0|1] "" Vector__XXX
 SG_ VCSEC_a114_PARTY_wheelRotation m114 : 23|1@1+ (1,0) [0|1] "" Vector__XXX
 SG_ VCSEC_a114_CH_wheelRotation m114 : 24|1@1+ (1,0) [0|1] "" Vector__XXX
 SG_ VCSEC_a114_VEH_wheelRotation m114 : 25|1@1+ (1,0) [0|1] "" Vector__XXX
 SG_ VCSEC_a114_PARTY_brakeTorque m114 : 26|1@1+ (1,0) [0|1] "" Vector__XXX
 SG_ VCSEC_a114_PARTY_offsets m114 : 27|1@1+ (1,0) [0|1] "" Vector__XXX
 SG_ VCSEC_a114_BDY_offsets m114 : 28|1@1+ (1,0) [0|1] "" Vector__XXX
 SG_ VCSEC_a114_BDY_party3 m114 : 29|1@1+ (1,0) [0|1] "" Vector__XXX
 SG_ VCSEC_a114_BDY_status m114 : 30|1@1+ (1,0) [0|1] "" Vector__XXX
 SG_ VCSEC_a114_BDY_wheelRotation m114 : 31|1@1+ (1,0) [0|1] "" Vector__XXX
 SG_ VCSEC_a114_BDY_wheelSpeeds m114 : 32|1@1+ (1,0) [0|1] "" Vector__XXX
 SG_ VCSEC_a114_CH_party1 m114 : 33|1@1+ (1,0) [0|1] "" Vector__XXX
 SG_ VCSEC_a114_CH_party3 m114 : 34|1@1+ (1,0) [0|1] "" Vector__XXX
 SG_ VCSEC_a114_CH_status m114 : 35|1@1+ (1,0) [0|1] "" Vector__XXX
 SG_ VCSEC_a115_VEH_vehNm m115 : 16|1@1+ (1,0) [0|1] "" Vector__XXX
 SG_ VCSEC_a115_VEH_authentication m115 : 17|1@1+ (1,0) [0|1] "" Vector__XXX
 SG_ VCSEC_a115_VEH_BLEResetRequest m115 : 18|1@1+ (1,0) [0|1] "" Vector__XXX
 SG_ VCSEC_a115_VEH_requests m115 : 19|1@1+ (1,0) [0|1] "" Vector__XXX
 SG_ VCSEC_a115_VEH_requests2 m115 : 20|1@1+ (1,0) [0|1] "" Vector__XXX
 SG_ VCSEC_a115_REM_authentication m115 : 21|1@1+ (1,0) [0|1] "" Vector__XXX
 SG_ VCSEC_a115_UI_corianderVehicleCo m115 : 22|1@1+ (1,0) [0|1] "" Vector__XXX
 SG_ VCSEC_a115_CH_TPMSDisplay m115 : 23|1@1+ (1,0) [0|1] "" Vector__XXX
 SG_ VCSEC_a116_PARTY_epbmStatus m116 : 16|1@1+ (1,0) [0|1] "" Vector__XXX
 SG_ VCSEC_a116_VEH_vehNm m116 : 17|1@1+ (1,0) [0|1] "" Vector__XXX
 SG_ VCSEC_a116_VEH_hvacRequest m116 : 18|1@1+ (1,0) [0|1] "" Vector__XXX
 SG_ VCSEC_a116_VEH_hvacStatus m116 : 19|1@1+ (1,0) [0|1] "" Vector__XXX
 SG_ VCSEC_a116_VEH_LVPowerState m116 : 20|1@1+ (1,0) [0|1] "" Vector__XXX
 SG_ VCSEC_a116_VEH_lightStatus m116 : 21|1@1+ (1,0) [0|1] "" Vector__XXX
 SG_ VCSEC_a116_VEH_seatStatus m116 : 22|1@1+ (1,0) [0|1] "" Vector__XXX
 SG_ VCSEC_a116_VEH_thsStatus m116 : 23|1@1+ (1,0) [0|1] "" Vector__XXX
 SG_ VCSEC_a116_VEH_doorStatus m116 : 24|1@1+ (1,0) [0|1] "" Vector__XXX
 SG_ VCSEC_a116_VEH_seatHeatStatus m116 : 25|1@1+ (1,0) [0|1] "" Vector__XXX
 SG_ VCSEC_a116_VEH_restraintStatus m116 : 26|1@1+ (1,0) [0|1] "" Vector__XXX
 SG_ VCSEC_a116_VEH_switchStatus m116 : 27|1@1+ (1,0) [0|1] "" Vector__XXX
 SG_ VCSEC_a116_VEH_logging1Hz m116 : 28|1@1+ (1,0) [0|1] "" Vector__XXX
 SG_ VCSEC_a116_VEH_seatStatus2 m116 : 29|1@1+ (1,0) [0|1] "" Vector__XXX
 SG_ VCSEC_a116_VEH_status m116 : 30|1@1+ (1,0) [0|1] "" Vector__XXX
 SG_ VCSEC_a116_VEH_thermalCommand m116 : 31|1@1+ (1,0) [0|1] "" Vector__XXX
 SG_ VCSEC_a116_VEH_windowStatus m116 : 32|1@1+ (1,0) [0|1] "" Vector__XXX
 SG_ VCSEC_a116_PARTY_restraintStatus m116 : 33|1@1+ (1,0) [0|1] "" Vector__XXX
 SG_ VCSEC_a116_PARTY_doorStatus m116 : 34|1@1+ (1,0) [0|1] "" Vector__XXX
 SG_ VCSEC_a116_BDY_epbmStatus m116 : 35|1@1+ (1,0) [0|1] "" Vector__XXX
 SG_ VCSEC_a116_BDY_restraintStatus m116 : 36|1@1+ (1,0) [0|1] "" Vector__XXX
 SG_ VCSEC_a116_BDY_switchStatus m116 : 37|1@1+ (1,0) [0|1] "" Vector__XXX
 SG_ VCSEC_a117_BDY_epbmStatus m117 : 16|1@1+ (1,0) [0|1] "" Vector__XXX
 SG_ VCSEC_a117_BDY_restraintStatus m117 : 17|1@1+ (1,0) [0|1] "" Vector__XXX
 SG_ VCSEC_a117_VEH_prndStatus m117 : 18|1@1+ (1,0) [0|1] "" Vector__XXX
 SG_ VCSEC_a117_PARTY_epbmStatus m117 : 19|1@1+ (1,0) [0|1] "" Vector__XXX
 SG_ VCSEC_a117_VEH_vehNm m117 : 20|1@1+ (1,0) [0|1] "" Vector__XXX
 SG_ VCSEC_a117_VEH_hvacBlowerFdb m117 : 21|1@1+ (1,0) [0|1] "" Vector__XXX
 SG_ VCSEC_a117_VEH_LVPowerState m117 : 22|1@1+ (1,0) [0|1] "" Vector__XXX
 SG_ VCSEC_a117_VEH_restraintStatus m117 : 23|1@1+ (1,0) [0|1] "" Vector__XXX
 SG_ VCSEC_a117_VEH_lightStatus m117 : 24|1@1+ (1,0) [0|1] "" Vector__XXX
 SG_ VCSEC_a117_VEH_seatStatus m117 : 25|1@1+ (1,0) [0|1] "" Vector__XXX
 SG_ VCSEC_a117_BDY_falconSwitchStatu m117 : 26|1@1+ (1,0) [0|1] "" Vector__XXX
 SG_ VCSEC_a117_VEH_doorStatus m117 : 27|1@1+ (1,0) [0|1] "" Vector__XXX
 SG_ VCSEC_a117_VEH_doorStatus2 m117 : 28|1@1+ (1,0) [0|1] "" Vector__XXX
 SG_ VCSEC_a117_VEH_windowStatus m117 : 29|1@1+ (1,0) [0|1] "" Vector__XXX
 SG_ VCSEC_a117_VEH_switchStatus m117 : 30|1@1+ (1,0) [0|1] "" Vector__XXX
 SG_ VCSEC_a117_VEH_intrusionSensorSt m117 : 31|1@1+ (1,0) [0|1] "" Vector__XXX
 SG_ VCSEC_a117_VEH_liftgateStatus m117 : 32|1@1+ (1,0) [0|1] "" Vector__XXX
 SG_ VCSEC_a117_VEH_seatStatus2 m117 : 33|1@1+ (1,0) [0|1] "" Vector__XXX
 SG_ VCSEC_a117_PARTY_restraintStatus m117 : 34|1@1+ (1,0) [0|1] "" Vector__XXX
 SG_ VCSEC_a117_VEH_thermalStatus m117 : 35|1@1+ (1,0) [0|1] "" Vector__XXX
 SG_ VCSEC_a117_PARTY_doorStatus m117 : 36|1@1+ (1,0) [0|1] "" Vector__XXX
 SG_ VCSEC_a117_VEH_status m117 : 37|1@1+ (1,0) [0|1] "" Vector__XXX
 SG_ VCSEC_a117_PARTY_prndStatus m117 : 38|1@1+ (1,0) [0|1] "" Vector__XXX
 SG_ VCSEC_a117_PARTY_lightingSeconda m117 : 39|1@1+ (1,0) [0|1] "" Vector__XXX
 SG_ VCSEC_a118_VEH_vehNm m118 : 16|1@1+ (1,0) [0|1] "" Vector__XXX
 SG_ VCSEC_a118_VEH_lighting m118 : 17|1@1+ (1,0) [0|1] "" Vector__XXX
 SG_ VCSEC_a118_VEH_sensors m118 : 18|1@1+ (1,0) [0|1] "" Vector__XXX
 SG_ VCSEC_a118_VEH_status m118 : 19|1@1+ (1,0) [0|1] "" Vector__XXX
 SG_ VCSEC_a118_VEH_okToUseHighPwr m118 : 20|1@1+ (1,0) [0|1] "" Vector__XXX
 SG_ VCSEC_a118_VEH_LVPowerState m118 : 21|1@1+ (1,0) [0|1] "" Vector__XXX
 SG_ VCSEC_a118_VEH_coolant m118 : 22|1@1+ (1,0) [0|1] "" Vector__XXX
 SG_ VCSEC_a118_VEH_vehicleStatus m118 : 23|1@1+ (1,0) [0|1] "" Vector__XXX
 SG_ VCSEC_a118_VEH_12VBatteryStatus m118 : 24|1@1+ (1,0) [0|1] "" Vector__XXX
 SG_ VCSEC_a118_VEH_systemStatus m118 : 25|1@1+ (1,0) [0|1] "" Vector__XXX
 SG_ VCSEC_a118_PARTY_LVPowerState m118 : 26|1@1+ (1,0) [0|1] "" Vector__XXX
 SG_ VCSEC_a118_PARTY_outputPowerStat m118 : 27|1@1+ (1,0) [0|1] "" Vector__XXX
 SG_ VCSEC_a118_PARTY_vehicleTime m118 : 28|1@1+ (1,0) [0|1] "" Vector__XXX
 SG_ VCSEC_a118_VEH_thermalCommand m118 : 29|1@1+ (1,0) [0|1] "" Vector__XXX
 SG_ VCSEC_a118_CH_LVPowerState m118 : 30|1@1+ (1,0) [0|1] "" Vector__XXX
 SG_ VCSEC_a118_PARTY_sensors m118 : 31|1@1+ (1,0) [0|1] "" Vector__XXX
 SG_ VCSEC_a118_CH_sensors m118 : 32|1@1+ (1,0) [0|1] "" Vector__XXX
 SG_ VCSEC_a118_VEH_interNodeResistan m118 : 33|1@1+ (1,0) [0|1] "" Vector__XXX
 SG_ VCSEC_a118_CH_lighting m118 : 34|1@1+ (1,0) [0|1] "" Vector__XXX
 SG_ VCSEC_a118_VEH_lightStatus m118 : 35|1@1+ (1,0) [0|1] "" Vector__XXX
 SG_ VCSEC_a118_PARTY_vehNm m118 : 36|1@1+ (1,0) [0|1] "" Vector__XXX
 SG_ VCSEC_a118_CH_12VBatteryStatus m118 : 37|1@1+ (1,0) [0|1] "" Vector__XXX
 SG_ VCSEC_a118_CH_LVBMS_statusHigh m118 : 38|1@1+ (1,0) [0|1] "" Vector__XXX
 SG_ VCSEC_a118_CH_alertMatrix m118 : 39|1@1+ (1,0) [0|1] "" Vector__XXX
 SG_ VCSEC_a118_BDY_outputPowerStatus m118 : 40|1@1+ (1,0) [0|1] "" Vector__XXX
 SG_ VCSEC_a118_BDY_vehicleTime m118 : 41|1@1+ (1,0) [0|1] "" Vector__XXX
 SG_ VCSEC_a118_PARTY_AP_vehicleState m118 : 42|1@1+ (1,0) [0|1] "" Vector__XXX
 SG_ VCSEC_a118_BDY_AP_vehicleState1H m118 : 43|1@1+ (1,0) [0|1] "" Vector__XXX
 SG_ VCSEC_a118_PARTY_VCFRONT_cameraC m118 : 44|1@1+ (1,0) [0|1] "" Vector__XXX
 SG_ VCSEC_a119_VEH_steerAngle m119 : 16|1@1+ (1,0) [0|1] "" Vector__XXX
 SG_ VCSEC_a119_VEH_leftStalk m119 : 17|1@1+ (1,0) [0|1] "" Vector__XXX
 SG_ VCSEC_a119_VEH_rightStalk m119 : 18|1@1+ (1,0) [0|1] "" Vector__XXX
 SG_ VCSEC_a119_PARTY_rightStalk m119 : 19|1@1+ (1,0) [0|1] "" Vector__XXX
 SG_ VCSEC_a119_CH_steerAngle m119 : 20|1@1+ (1,0) [0|1] "" Vector__XXX
 SG_ VCSEC_a119_PARTY_steerAngle m119 : 21|1@1+ (1,0) [0|1] "" Vector__XXX
 SG_ VCSEC_a120_PARTY_chassisCntl m120 : 16|1@1+ (1,0) [0|1] "" Vector__XXX
 SG_ VCSEC_a120_VEH_systemStatus m120 : 17|1@1+ (1,0) [0|1] "" Vector__XXX
 SG_ VCSEC_a120_CH_chassisCntl m120 : 18|1@1+ (1,0) [0|1] "" Vector__XXX
 SG_ VCSEC_a120_PARTY_systemStatus m120 : 19|1@1+ (1,0) [0|1] "" Vector__XXX
 SG_ VCSEC_a120_PARTY_torque m120 : 20|1@1+ (1,0) [0|1] "" Vector__XXX
 SG_ VCSEC_a120_VEH_torque m120 : 21|1@1+ (1,0) [0|1] "" Vector__XXX
 SG_ VCSEC_a120_PARTY_locStatus m120 : 22|1@1+ (1,0) [0|1] "" Vector__XXX
 SG_ VCSEC_a120_PARTY_speed m120 : 23|1@1+ (1,0) [0|1] "" Vector__XXX
 SG_ VCSEC_a120_VEH_speed m120 : 24|1@1+ (1,0) [0|1] "" Vector__XXX
 SG_ VCSEC_a120_PARTY_status m120 : 25|1@1+ (1,0) [0|1] "" Vector__XXX
 SG_ VCSEC_a120_PT_speed m120 : 26|1@1+ (1,0) [0|1] "" Vector__XXX
 SG_ VCSEC_a120_PT_systemStatus m120 : 27|1@1+ (1,0) [0|1] "" Vector__XXX
 SG_ VCSEC_a120_PARTY_vehicleEstimate m120 : 28|1@1+ (1,0) [0|1] "" Vector__XXX
 SG_ VCSEC_a120_VEH_aggregatedAxleSpe m120 : 29|1@1+ (1,0) [0|1] "" Vector__XXX
 SG_ VCSEC_a120_PARTY_aggregatedAxleS m120 : 30|1@1+ (1,0) [0|1] "" Vector__XXX
 SG_ VCSEC_a120_VEH_systemPower m120 : 31|1@1+ (1,0) [0|1] "" Vector__XXX
 SG_ VCSEC_a120_PARTY_autonomyHealth m120 : 32|1@1+ (1,0) [0|1] "" Vector__XXX
 SG_ VCSEC_a120_VEH_autonomyHealth m120 : 33|1@1+ (1,0) [0|1] "" Vector__XXX
 SG_ VCSEC_a120_PT_systemPower m120 : 34|1@1+ (1,0) [0|1] "" Vector__XXX
 SG_ VCSEC_a120_PARTY_stalklessInterf m120 : 35|1@1+ (1,0) [0|1] "" Vector__XXX
 SG_ VCSEC_a120_CH_speed m120 : 36|1@1+ (1,0) [0|1] "" Vector__XXX
 SG_ VCSEC_a120_VEH_estimatedBrakeTem m120 : 37|1@1+ (1,0) [0|1] "" Vector__XXX
 SG_ VCSEC_a120_PARTY_prndControl m120 : 38|1@1+ (1,0) [0|1] "" Vector__XXX
 SG_ VCSEC_a120_PARTY_locStatus2 m120 : 39|1@1+ (1,0) [0|1] "" Vector__XXX
 SG_ VCSEC_a120_VEH_chassisCntl m120 : 40|1@1+ (1,0) [0|1] "" Vector__XXX
 SG_ VCSEC_a120_CH_locStatus2 m120 : 41|1@1+ (1,0) [0|1] "" Vector__XXX
 SG_ VCSEC_a120_VEH_locStatus m120 : 42|1@1+ (1,0) [0|1] "" Vector__XXX
 SG_ VCSEC_a120_VEH_locStatus2 m120 : 43|1@1+ (1,0) [0|1] "" Vector__XXX
 SG_ VCSEC_a120_VEH_prndControl m120 : 44|1@1+ (1,0) [0|1] "" Vector__XXX
 SG_ VCSEC_a120_VEH_vehicleEstimates m120 : 45|1@1+ (1,0) [0|1] "" Vector__XXX
 SG_ VCSEC_a120_PARTY_motorStatus m120 : 46|1@1+ (1,0) [0|1] "" Vector__XXX
 SG_ VCSEC_a120_VEH_motorStatus m120 : 47|1@1+ (1,0) [0|1] "" Vector__XXX
 SG_ VCSEC_a120_BDY_speed m120 : 48|1@1+ (1,0) [0|1] "" Vector__XXX
 SG_ VCSEC_a121_VEH_status m121 : 16|1@1+ (1,0) [0|1] "" Vector__XXX
 SG_ VCSEC_a121_VEH_occupancy m121 : 17|1@1+ (1,0) [0|1] "" Vector__XXX
 SG_ VCSEC_a133_alarmTriggerReason m133 : 16|4@1+ (1,0) [0|15] "" Vector__XXX
 SG_ VCSEC_a140_keyDidNotIdentify m140 : 16|1@1+ (1,0) [0|1] "" Vector__XXX
 SG_ VCSEC_a140_keyNotPairedToTheCar m140 : 17|1@1+ (1,0) [0|1] "" Vector__XXX
 SG_ VCSEC_a140_authenticationFailed m140 : 18|1@1+ (1,0) [0|1] "" Vector__XXX
 SG_ VCSEC_a140_authenticationTimeout m140 : 19|1@1+ (1,0) [0|1] "" Vector__XXX
 SG_ VCSEC_a140_cardRmvdB4AuthComplet m140 : 20|1@1+ (1,0) [0|1] "" Vector__XXX
 SG_ VCSEC_a140_cardRmvdB4SndingChaln m140 : 21|1@1+ (1,0) [0|1] "" Vector__XXX
 SG_ VCSEC_a140_cardRmvdB4SndingReqID m140 : 22|1@1+ (1,0) [0|1] "" Vector__XXX
 SG_ VCSEC_a140_cardRmvdB4RecvingID m140 : 23|1@1+ (1,0) [0|1] "" Vector__XXX
 SG_ VCSEC_a140_multipleTriesToAuth m140 : 24|1@1+ (1,0) [0|1] "" Vector__XXX
 SG_ VCSEC_a177_newWhitelistSlot m177 : 16|5@1+ (1,0) [0|31] "" Vector__XXX
 SG_ VCSEC_a177_signingKeySlot m177 : 21|5@1+ (1,0) [0|31] "" Vector__XXX
 SG_ VCSEC_a177_newKeyPublicKey m177 : 26|20@1+ (1,0) [0|1048575] "" Vector__XXX
 SG_ VCSEC_a177_keyActiveTime m177 : 46|12@1+ (1,0) [0|4095] "" Vector__XXX
 SG_ VCSEC_a177_keyRole m177 : 58|4@1+ (1,0) [0|15] "" Vector__XXX
 SG_ VCSEC_a178_publicKey m178 : 16|32@1+ (1,0) [0|4294967295] "" Vector__XXX
 SG_ VCSEC_a178_signingKeySlot m178 : 48|5@1+ (1,0) [0|31] "" Vector__XXX
 SG_ VCSEC_a178_removedKeySlot m178 : 53|5@1+ (1,0) [0|31] "" Vector__XXX
 SG_ VCSEC_a178_removedKeyRole m178 : 58|4@1+ (1,0) [0|15] "" Vector__XXX
 SG_ VCSEC_a191_clearWlist m191 : 16|1@1+ (1,0) [0|1] "" Vector__XXX
 SG_ VCSEC_a191_WlistingDevice m191 : 17|1@1+ (1,0) [0|1] "" Vector__XXX
 SG_ VCSEC_a191_failedToSendWlist m191 : 18|1@1+ (1,0) [0|1] "" Vector__XXX
 SG_ VCSEC_a192_clearWlist m192 : 16|1@1+ (1,0) [0|1] "" Vector__XXX
 SG_ VCSEC_a192_WlistingDevice m192 : 17|1@1+ (1,0) [0|1] "" Vector__XXX
 SG_ VCSEC_a192_failedToSendWlist m192 : 18|1@1+ (1,0) [0|1] "" Vector__XXX
 SG_ VCSEC_a193_clearWlist m193 : 16|1@1+ (1,0) [0|1] "" Vector__XXX
 SG_ VCSEC_a193_WlistingDevice m193 : 17|1@1+ (1,0) [0|1] "" Vector__XXX
 SG_ VCSEC_a193_failedToSendWlist m193 : 18|1@1+ (1,0) [0|1] "" Vector__XXX
 SG_ VCSEC_a194_clearWlist m194 : 16|1@1+ (1,0) [0|1] "" Vector__XXX
 SG_ VCSEC_a194_WlistingDevice m194 : 17|1@1+ (1,0) [0|1] "" Vector__XXX
 SG_ VCSEC_a194_failedToSendWlist m194 : 18|1@1+ (1,0) [0|1] "" Vector__XXX
 SG_ VCSEC_a197_connectionChannel m197 : 16|4@1+ (1,0) [0|15] "" Vector__XXX
 SG_ VCSEC_a197_connHandleMismatch m197 : 20|1@1+ (1,0) [0|1] "" Vector__XXX
 SG_ VCSEC_a197_confrmtnTimeout m197 : 21|1@1+ (1,0) [0|1] "" Vector__XXX
 SG_ VCSEC_a197_errorInconfrmtn m197 : 24|8@1+ (1,0) [0|255] "" Vector__XXX
 SG_ VCSEC_a210_whiteListChannel m210 : 16|5@1+ (1,0) [0|31] "" Vector__XXX
 SG_ VCSEC_a211_handlePulled m211 : 16|4@1+ (1,0) [0|15] "" Vector__XXX
 SG_ VCSEC_a211_connectionCount m211 : 20|2@1+ (1,0) [0|3] "" Vector__XXX
 SG_ VCSEC_a211_RSSIValidMatrix m211 : 22|24@1+ (1,0) [0|16777215] "" Vector__XXX
 SG_ VCSEC_a211_DevicePresentCount m211 : 46|2@1+ (1,0) [0|3] "" Vector__XXX
 SG_ VCSEC_a211_UnknownDevicePresent m211 : 48|1@1+ (1,0) [0|1] "" Vector__XXX
 SG_ VCSEC_a211_AuthRequested m211 : 49|1@1+ (1,0) [0|1] "" Vector__XXX
 SG_ VCSEC_a211_MaximumRSSI m211 : 50|8@1- (1,0) [-128|127] "" Vector__XXX
 SG_ VCSEC_a211_MaximumRSSIAntenna m211 : 58|4@1+ (1,0) [0|15] "" Vector__XXX
 SG_ VCSEC_a211_riderKeyConnected m211 : 62|1@1+ (1,0) [0|1] "" Vector__XXX
 SG_ VCSEC_a211_FleetModeActive m211 : 63|1@1+ (1,0) [0|1] "" Vector__XXX
 SG_ VCSEC_a219_pairingRemovedSensor0 m219 : 16|1@1+ (1,0) [0|1] "" Vector__XXX
 SG_ VCSEC_a219_pairingRemovedSensor1 m219 : 17|1@1+ (1,0) [0|1] "" Vector__XXX
 SG_ VCSEC_a219_pairingRemovedSensor2 m219 : 18|1@1+ (1,0) [0|1] "" Vector__XXX
 SG_ VCSEC_a219_pairingRemovedSensor3 m219 : 19|1@1+ (1,0) [0|1] "" Vector__XXX
 SG_ VCSEC_a221_countryCode m221 : 16|16@1+ (1,0) [0|65535] "" Vector__XXX
 SG_ VCSEC_a221_homologationRegion m221 : 32|2@1+ (1,0) [0|3] "" Vector__XXX
 SG_ VCSEC_a256_whitelistOperation m256 : 16|4@1+ (1,0) [0|15] "" Vector__XXX
 SG_ VCSEC_a256_failureReason m256 : 24|6@1+ (1,0) [0|63] "" Vector__XXX
 SG_ VCSEC_a256_whitelistSlot m256 : 32|5@1+ (1,0) [0|31] "" Vector__XXX
 SG_ VCSEC_a256_signingKeySlot m256 : 40|5@1+ (1,0) [0|31] "" Vector__XXX
 SG_ VCSEC_a256_keyActiveTime m256 : 45|18@1+ (1,0) [0|262143] "" Vector__XXX
 SG_ VCSEC_a257_whitelistSlot m257 : 16|5@1+ (1,0) [0|31] "" Vector__XXX
 SG_ VCSEC_a257_keyID m257 : 24|24@1+ (1,0) [0|16777215] "" Vector__XXX
 SG_ VCSEC_a257_keyActiveTime m257 : 48|8@1+ (1,0) [0|255] "" Vector__XXX
 SG_ VCSEC_a257_permissionActiveTime m257 : 56|8@1+ (1,0) [0|255] "" Vector__XXX
 SG_ VCSEC_a266_pressure m266 : 16|8@1+ (0.025,0) [0|6.375] "bar" Vector__XXX
 SG_ VCSEC_a267_pressure m267 : 16|8@1+ (0.025,0) [0|6.375] "bar" Vector__XXX
 SG_ VCSEC_a268_pressure m268 : 16|8@1+ (0.025,0) [0|6.375] "bar" Vector__XXX
 SG_ VCSEC_a269_pressure m269 : 16|8@1+ (0.025,0) [0|6.375] "bar" Vector__XXX
 SG_ VCSEC_a270_pressure m270 : 16|8@1+ (0.025,0) [0|6.375] "bar" Vector__XXX
 SG_ VCSEC_a271_pressure m271 : 16|8@1+ (0.025,0) [0|6.375] "bar" Vector__XXX
 SG_ VCSEC_a272_pressure m272 : 16|8@1+ (0.025,0) [0|6.375] "bar" Vector__XXX
 SG_ VCSEC_a273_pressure m273 : 16|8@1+ (0.025,0) [0|6.375] "bar" Vector__XXX
 SG_ VCSEC_a311_whitelistChannel m311 : 16|5@1+ (1,0) [0|31] "" Vector__XXX
 SG_ VCSEC_a436_currentUHFHardware m436 : 16|8@1+ (1,0) [0|255] "" Vector__XXX
 SG_ VCSEC_a436_expectedUHFHardware m436 : 24|8@1+ (1,0) [0|255] "" Vector__XXX
 SG_ VCSEC_a436_countryCode m436 : 32|16@1+ (1,0) [0|65535] "" Vector__XXX
 SG_ VCSEC_a455_pressure m455 : 16|8@1+ (0.025,0) [0|6.375] "bar" Vector__XXX
 SG_ VCSEC_a456_pressure m456 : 16|8@1+ (0.025,0) [0|6.375] "bar" Vector__XXX
 SG_ VCSEC_a457_pressure m457 : 16|8@1+ (0.025,0) [0|6.375] "bar" Vector__XXX
 SG_ VCSEC_a458_pressure m458 : 16|8@1+ (0.025,0) [0|6.375] "bar" Vector__XXX
 SG_ VCSEC_a497_centerEndpointMismatc m497 : 16|1@1+ (1,0) [0|1] "" Vector__XXX
 SG_ VCSEC_a497_cradleEndpointMismatc m497 : 17|1@1+ (1,0) [0|1] "" Vector__XXX
 SG_ VCSEC_a497_leftEndpointMismatch m497 : 18|1@1+ (1,0) [0|1] "" Vector__XXX
 SG_ VCSEC_a497_rightEndpointMismatch m497 : 19|1@1+ (1,0) [0|1] "" Vector__XXX
 SG_ VCSEC_a497_rearLeftEndpointMisma m497 : 20|1@1+ (1,0) [0|1] "" Vector__XXX
 SG_ VCSEC_a497_rearRightEndpointMism m497 : 21|1@1+ (1,0) [0|1] "" Vector__XXX
 SG_ VCSEC_a497_endpointLocationToFix m497 : 24|4@1+ (1,0) [0|15] "" Vector__XXX
 SG_ VCSEC_a497_endpointExpectedPcbaI m497 : 32|8@1+ (1,0) [0|255] "" Vector__XXX
 SG_ VCSEC_a497_endpointExpectedAssem m497 : 40|4@1+ (1,0) [0|15] "" Vector__XXX
 SG_ VCSEC_a497_endpointExpectedUsage m497 : 44|4@1+ (1,0) [0|15] "" Vector__XXX
 SG_ VCSEC_a497_endpointActualPcbaId m497 : 48|8@1+ (1,0) [0|255] "" Vector__XXX
 SG_ VCSEC_a497_endpointActualAssembl m497 : 56|4@1+ (1,0) [0|15] "" Vector__XXX
 SG_ VCSEC_a497_endpointActualUsageId m497 : 60|4@1+ (1,0) [0|15] "" Vector__XXX
 SG_ VCSEC_a504_ecuUnprovisioned m504 : 16|1@1+ (1,0) [0|1] "" Vector__XXX
 SG_ VCSEC_a505_excessiveMacFailures m505 : 16|1@1+ (1,0) [0|1] "" Vector__XXX
 SG_ VCSEC_a517_pressure m517 : 16|9@1+ (0.025,0) [0|12.775] "bar" Vector__XXX
 SG_ VCSEC_a518_pressure m518 : 16|9@1+ (0.025,0) [0|12.775] "bar" Vector__XXX
 SG_ VCSEC_a519_pressure m519 : 16|9@1+ (0.025,0) [0|12.775] "bar" Vector__XXX
 SG_ VCSEC_a520_pressure m520 : 16|9@1+ (0.025,0) [0|12.775] "bar" Vector__XXX

BO_TX_BU_ 537 : VCSEC;
BO_TX_BU_ 602 : VCSEC;
BO_TX_BU_ 570 : VCSEC;
BO_TX_BU_ 1067 : VCSEC;
BO_TX_BU_ 761 : VCSEC;
BO_TX_BU_ 1328 : VCSEC;
CM_ BO_ 537 "Vehicle security controller message: TPMS data; frame length from the layout, not yet observed on a vehicle bus";
CM_ SG_ 537 VCSEC_TPMSDataIndex "Vehicle security controller: TPMS data index";
CM_ SG_ 537 VCSEC_TPMSCapabilityPressureInAd "Vehicle security controller: TPMS capability pressure in adv0";
CM_ SG_ 537 VCSEC_TPMSCapabilityConfigurable "Vehicle security controller: TPMS capability configurable pressure0";
CM_ SG_ 537 VCSEC_TPMSPressureRateOfChange0 "Reports the raw pressure value of TPMS sensor 0.";
CM_ SG_ 537 VCSEC_TPMSPressure0 "Indicates Absolute pressure measured by wheel unit; raw 511 = signal not available (SNA)";
CM_ SG_ 537 VCSEC_TPMSTemperature0 "Indicates temperature in tire; raw 255 = signal not available (SNA)";
CM_ SG_ 537 VCSEC_TPMSBatVoltage0 "Sensor battery voltage; raw 255 = signal not available (SNA)";
CM_ SG_ 537 VCSEC_TPMSLocation0 "Indicates the localization result";
CM_ SG_ 537 VCSEC_TPMSTemperatureCompensated "Indicates Absolute pressure measured by wheel unit; raw 511 = signal not available (SNA)";
CM_ SG_ 537 VCSEC_TPMSCapabilityPressur_0001 "Vehicle security controller: TPMS capability pressure in adv1";
CM_ SG_ 537 VCSEC_TPMSCapabilityConfigu_0001 "Vehicle security controller: TPMS capability configurable pressure1";
CM_ SG_ 537 VCSEC_TPMSPressureRateOfChange1 "Reports the raw pressure value of TPMS sensor 1.";
CM_ SG_ 537 VCSEC_TPMSPressure1 "Indicates Absolute pressure measured by wheel unit; raw 511 = signal not available (SNA)";
CM_ SG_ 537 VCSEC_TPMSTemperature1 "Indicates temperature in tire; raw 255 = signal not available (SNA)";
CM_ SG_ 537 VCSEC_TPMSBatVoltage1 "Sensor battery voltage; raw 255 = signal not available (SNA)";
CM_ SG_ 537 VCSEC_TPMSLocation1 "Indicates the localization result";
CM_ SG_ 537 VCSEC_TPMSTemperatureCompen_0001 "Indicates Absolute pressure measured by wheel unit; raw 511 = signal not available (SNA)";
CM_ SG_ 537 VCSEC_TPMSCapabilityPressur_0002 "Vehicle security controller: TPMS capability pressure in adv2";
CM_ SG_ 537 VCSEC_TPMSCapabilityConfigu_0002 "Vehicle security controller: TPMS capability configurable pressure2";
CM_ SG_ 537 VCSEC_TPMSPressureRateOfChange2 "Reports the raw pressure value of TPMS sensor 2.";
CM_ SG_ 537 VCSEC_TPMSPressure2 "Indicates Absolute pressure measured by wheel unit; raw 511 = signal not available (SNA)";
CM_ SG_ 537 VCSEC_TPMSTemperature2 "Indicates temperature in tire; raw 255 = signal not available (SNA)";
CM_ SG_ 537 VCSEC_TPMSBatVoltage2 "Sensor battery voltage; raw 255 = signal not available (SNA)";
CM_ SG_ 537 VCSEC_TPMSLocation2 "Indicates the localization result";
CM_ SG_ 537 VCSEC_TPMSTemperatureCompen_0002 "Indicates Absolute pressure measured by wheel unit; raw 511 = signal not available (SNA)";
CM_ SG_ 537 VCSEC_TPMSCapabilityPressur_0003 "Vehicle security controller: TPMS capability pressure in adv3";
CM_ SG_ 537 VCSEC_TPMSCapabilityConfigu_0003 "Vehicle security controller: TPMS capability configurable pressure3";
CM_ SG_ 537 VCSEC_TPMSPressureRateOfChange3 "Reports the raw pressure value of TPMS sensor 3.";
CM_ SG_ 537 VCSEC_TPMSPressure3 "Indicates Absolute pressure measured by wheel unit; raw 511 = signal not available (SNA)";
CM_ SG_ 537 VCSEC_TPMSTemperature3 "Indicates temperature in tire; raw 255 = signal not available (SNA)";
CM_ SG_ 537 VCSEC_TPMSBatVoltage3 "Sensor battery voltage; raw 255 = signal not available (SNA)";
CM_ SG_ 537 VCSEC_TPMSLocation3 "Indicates the localization result";
CM_ SG_ 537 VCSEC_TPMSTemperatureCompen_0003 "Indicates Absolute pressure measured by wheel unit; raw 511 = signal not available (SNA)";
CM_ SG_ 537 VCSEC_TPMSRecommendedColdPressur "Indicates Absolute pressure measured by wheel unit; raw 255 = signal not available (SNA)";
CM_ SG_ 537 VCSEC_TPMSRecommendedColdPr_0001 "Indicates Absolute pressure measured by wheel unit; raw 255 = signal not available (SNA)";
CM_ SG_ 537 VCSEC_TPMSFeature0 "Vehicle security controller: TPMS feature0";
CM_ SG_ 537 VCSEC_TPMSFeature1 "Vehicle security controller: TPMS feature1";
CM_ SG_ 537 VCSEC_TPMSFeature0Count "Vehicle security controller: TPMS feature0 count";
CM_ SG_ 537 VCSEC_TPMSFeature0TimeS "Vehicle security controller: TPMS feature0 time s";
CM_ SG_ 537 VCSEC_TPMSAutonomyStatus "Vehicle security controller: TPMS autonomy status";
CM_ SG_ 537 VCSEC_TPMSAutonomyStatusMIATimeS "Vehicle security controller: TPMS autonomy status MIA time s";
CM_ SG_ 537 VCSEC_TPMSLastKnownPressureFL "Vehicle security controller: TPMS last known pressure FL; raw 255 = signal not available (SNA)";
CM_ SG_ 537 VCSEC_TPMSLastKnownPressureFR "Vehicle security controller: TPMS last known pressure FR; raw 255 = signal not available (SNA)";
CM_ SG_ 537 VCSEC_TPMSLastKnownPressureRL "Vehicle security controller: TPMS last known pressure RL; raw 255 = signal not available (SNA)";
CM_ SG_ 537 VCSEC_TPMSLastKnownPressureRR "Vehicle security controller: TPMS last known pressure RR; raw 255 = signal not available (SNA)";
CM_ BO_ 602 "Vehicle security controller message: TPMS display; frame length from the layout, not yet observed on a vehicle bus";
CM_ SG_ 602 VCSEC_TPMSDisplayPressureFL "Indicates Absolute pressure measured by wheel unit; raw 255 = signal not available (SNA)";
CM_ SG_ 602 VCSEC_TPMSDisplayPressureFR "Indicates Absolute pressure measured by wheel unit; raw 255 = signal not available (SNA)";
CM_ SG_ 602 VCSEC_TPMSDisplayPressureRL "Indicates Absolute pressure measured by wheel unit; raw 255 = signal not available (SNA)";
CM_ SG_ 602 VCSEC_TPMSDisplayPressureRR "Indicates Absolute pressure measured by wheel unit; raw 255 = signal not available (SNA)";
CM_ SG_ 602 VCSEC_TPMSTellTale "TPMS UI telltale status to indicate";
CM_ SG_ 602 VCSEC_TPMSDisplaySoftWarningIndi "UI should indicate soft warning";
CM_ SG_ 602 VCSEC_TPMSDisplaySoftWarnin_0001 "UI should indicate soft warning";
CM_ SG_ 602 VCSEC_TPMSDisplaySoftWarnin_0002 "UI should indicate soft warning";
CM_ SG_ 602 VCSEC_TPMSDisplaySoftWarnin_0003 "UI should indicate soft warning";
CM_ SG_ 602 VCSEC_TPMSDisplayHardWarningIndi "UI should indicate soft warning";
CM_ SG_ 602 VCSEC_TPMSDisplayHardWarnin_0001 "UI should indicate soft warning";
CM_ SG_ 602 VCSEC_TPMSDisplayHardWarnin_0002 "UI should indicate soft warning";
CM_ SG_ 602 VCSEC_TPMSDisplayHardWarnin_0003 "UI should indicate soft warning";
CM_ BO_ 570 "Vehicle security controller message: TPMS status; frame length from the layout, not yet observed on a vehicle bus";
CM_ SG_ 570 VCSEC_TPMSStatusIndex "Vehicle security controller: TPMS status index";
CM_ SG_ 570 VCSEC_TPMSSystemState "High level state the TPMS system is in currently";
CM_ SG_ 570 VCSEC_TPMSSensorMACAddress0 "Vehicle security controller: TPMS sensor MAC address0";
CM_ SG_ 570 VCSEC_TPMSSensorMACAddress1 "Vehicle security controller: TPMS sensor MAC address1";
CM_ SG_ 570 VCSEC_TPMSSensorMACAddress2 "Vehicle security controller: TPMS sensor MAC address2";
CM_ SG_ 570 VCSEC_TPMSSensorMACAddress3 "Vehicle security controller: TPMS sensor MAC address3";
CM_ SG_ 570 VCSEC_BLEUnsuccessfulConnEventRa "Vehicle security controller: BLE unsuccessful conn event rate0; raw 1023 = signal not available (SNA)";
CM_ SG_ 570 VCSEC_BLEUnsuccessfulConnEv_0001 "Vehicle security controller: BLE unsuccessful conn event rate1; raw 1023 = signal not available (SNA)";
CM_ SG_ 570 VCSEC_BLEUnsuccessfulConnEv_0002 "Vehicle security controller: BLE unsuccessful conn event rate2; raw 1023 = signal not available (SNA)";
CM_ SG_ 570 VCSEC_BLEUnsuccessfulConnEv_0003 "Vehicle security controller: BLE unsuccessful conn event rate3; raw 1023 = signal not available (SNA)";
CM_ SG_ 570 VCSEC_TPMSSensorTIAppCRC0 "Vehicle security controller: TPMS sensor TI app CRC0; raw 0 = signal not available (SNA)";
CM_ SG_ 570 VCSEC_TPMSSensorMLXAppCRC0 "Vehicle security controller: TPMS sensor MLX app CRC0; raw 0 = signal not available (SNA)";
CM_ SG_ 570 VCSEC_TPMSSensorTIAppCRC1 "Vehicle security controller: TPMS sensor TI app CRC1; raw 0 = signal not available (SNA)";
CM_ SG_ 570 VCSEC_TPMSSensorMLXAppCRC1 "Vehicle security controller: TPMS sensor MLX app CRC1; raw 0 = signal not available (SNA)";
CM_ SG_ 570 VCSEC_TPMSSensorTIAppCRC2 "Vehicle security controller: TPMS sensor TI app CRC2; raw 0 = signal not available (SNA)";
CM_ SG_ 570 VCSEC_TPMSSensorMLXAppCRC2 "Vehicle security controller: TPMS sensor MLX app CRC2; raw 0 = signal not available (SNA)";
CM_ SG_ 570 VCSEC_TPMSSensorTIAppCRC3 "Vehicle security controller: TPMS sensor TI app CRC3; raw 0 = signal not available (SNA)";
CM_ SG_ 570 VCSEC_TPMSSensorMLXAppCRC3 "Vehicle security controller: TPMS sensor MLX app CRC3; raw 0 = signal not available (SNA)";
CM_ SG_ 570 VCSEC_TPMStotalAwakeTime0 "Sleep and CPU time count";
CM_ SG_ 570 VCSEC_TPMSTrimAdjusted0 "Vehicle security controller: TPMS trim adjusted0";
CM_ SG_ 570 VCSEC_TPMSGenealogySensorState0 "TPMS genealogy state";
CM_ SG_ 570 VCSEC_TPMSSensorType0 "Tesla TPMS type";
CM_ SG_ 570 VCSEC_TPMStotalAwakeTime1 "Sleep and CPU time count";
CM_ SG_ 570 VCSEC_TPMSTrimAdjusted1 "Vehicle security controller: TPMS trim adjusted1";
CM_ SG_ 570 VCSEC_TPMSGenealogySensorState1 "TPMS genealogy state";
CM_ SG_ 570 VCSEC_TPMSSensorType1 "Tesla TPMS type";
CM_ SG_ 570 VCSEC_TPMStotalAwakeTime2 "Sleep and CPU time count";
CM_ SG_ 570 VCSEC_TPMSTrimAdjusted2 "Vehicle security controller: TPMS trim adjusted2";
CM_ SG_ 570 VCSEC_TPMSGenealogySensorState2 "TPMS genealogy state";
CM_ SG_ 570 VCSEC_TPMSSensorType2 "Tesla TPMS type";
CM_ SG_ 570 VCSEC_TPMStotalAwakeTime3 "Sleep and CPU time count";
CM_ SG_ 570 VCSEC_TPMSTrimAdjusted3 "Vehicle security controller: TPMS trim adjusted3";
CM_ SG_ 570 VCSEC_TPMSGenealogySensorState3 "TPMS genealogy state";
CM_ SG_ 570 VCSEC_TPMSSensorType3 "Tesla TPMS type";
CM_ SG_ 570 VCSEC_TPMSSensor0Hash "Vehicle security controller: TPMS sensor0 hash";
CM_ SG_ 570 VCSEC_TPMSSensor1Hash "Vehicle security controller: TPMS sensor1 hash";
CM_ SG_ 570 VCSEC_TPMSSensor2Hash "Vehicle security controller: TPMS sensor2 hash";
CM_ SG_ 570 VCSEC_TPMSSensor3Hash "Vehicle security controller: TPMS sensor3 hash";
CM_ SG_ 570 VCSEC_TPMSLastLocationSensor0 "Indicates the localization result";
CM_ SG_ 570 VCSEC_TPMSLastLocationSensor1 "Indicates the localization result";
CM_ SG_ 570 VCSEC_TPMSLastLocationSensor2 "Indicates the localization result";
CM_ SG_ 570 VCSEC_TPMSLastLocationSensor3 "Indicates the localization result";
CM_ SG_ 570 VCSEC_TPMSTemperatureCompensated "Sensor battery voltage; raw 255 = signal not available (SNA)";
CM_ SG_ 570 VCSEC_TPMSTemperatureCompen_0001 "Sensor battery voltage; raw 255 = signal not available (SNA)";
CM_ SG_ 570 VCSEC_TPMSTemperatureCompen_0002 "Sensor battery voltage; raw 255 = signal not available (SNA)";
CM_ SG_ 570 VCSEC_TPMSTemperatureCompen_0003 "Sensor battery voltage; raw 255 = signal not available (SNA)";
CM_ SG_ 570 VCSEC_TPMSFilteredBatVoltage0 "Sensor battery voltage; raw 255 = signal not available (SNA)";
CM_ SG_ 570 VCSEC_TPMSFilteredBatVoltage2 "Sensor battery voltage; raw 255 = signal not available (SNA)";
CM_ SG_ 570 VCSEC_TPMSFilteredBatVoltage1 "Sensor battery voltage; raw 255 = signal not available (SNA)";
CM_ SG_ 570 VCSEC_TPMSFilteredBatVoltage3 "Sensor battery voltage; raw 255 = signal not available (SNA)";
CM_ BO_ 1067 "Vehicle security controller message: UWB data; frame length from the layout, not yet observed on a vehicle bus";
CM_ SG_ 1067 VCSEC_UWBEndpointIndex "Vehicle security controller: UWB endpoint index";
CM_ SG_ 1067 VCSEC_UWBExpectedEndpointsActive "Expected number of UWB endpoints active for a connection channel.";
CM_ SG_ 1067 VCSEC_UWBExpectedEndpointsA_0001 "Expected number of UWB endpoints active for a connection channel.";
CM_ SG_ 1067 VCSEC_UWBExpectedEndpointsA_0002 "Expected number of UWB endpoints active for a connection channel.";
CM_ SG_ 1067 VCSEC_UWBExpectedEndpointsA_0003 "Expected number of UWB endpoints active for a connection channel.";
CM_ SG_ 1067 VCSEC_UWBRearRightDistance0 "Reports distance between the customer's phone and the endpoint; raw 4095 = signal not available (SNA)";
CM_ SG_ 1067 VCSEC_UWBRearRightDistance1 "Reports distance between the customer's phone and the endpoint; raw 4095 = signal not available (SNA)";
CM_ SG_ 1067 VCSEC_UWBRearRightDistance2 "Reports distance between the customer's phone and the endpoint; raw 4095 = signal not available (SNA)";
CM_ SG_ 1067 VCSEC_UWBLeftDistance3 "Reports distance between the customer's phone and the endpoint; raw 4095 = signal not available (SNA)";
CM_ SG_ 1067 VCSEC_UWBRightDistance3 "Reports distance between the customer's phone and the endpoint; raw 4095 = signal not available (SNA)";
CM_ SG_ 1067 VCSEC_UWBRearRightDistance3 "Reports distance between the customer's phone and the endpoint; raw 4095 = signal not available (SNA)";
CM_ SG_ 1067 VCSEC_UWBRearLeftDistance3 "Reports distance between the customer's phone and the endpoint; raw 4095 = signal not available (SNA)";
CM_ SG_ 1067 VCSEC_UWBCenterDistance3 "Reports distance between the customer's phone and the endpoint; raw 4095 = signal not available (SNA)";
CM_ SG_ 1067 VCSEC_UWBLeftDistance2 "Reports distance between the customer's phone and the endpoint; raw 4095 = signal not available (SNA)";
CM_ SG_ 1067 VCSEC_UWBRightDistance2 "Reports distance between the customer's phone and the endpoint; raw 4095 = signal not available (SNA)";
CM_ SG_ 1067 VCSEC_UWBRearDistance2 "Reports distance between the customer's phone and the endpoint; raw 4095 = signal not available (SNA)";
CM_ SG_ 1067 VCSEC_UWBRearLeftDistance2 "Reports distance between the customer's phone and the endpoint; raw 4095 = signal not available (SNA)";
CM_ SG_ 1067 VCSEC_UWBCenterDistance2 "Reports distance between the customer's phone and the endpoint; raw 4095 = signal not available (SNA)";
CM_ SG_ 1067 VCSEC_UWBLeftDistance1 "Reports distance between the customer's phone and the endpoint; raw 4095 = signal not available (SNA)";
CM_ SG_ 1067 VCSEC_UWBRightDistance1 "Reports distance between the customer's phone and the endpoint; raw 4095 = signal not available (SNA)";
CM_ SG_ 1067 VCSEC_UWBRearDistance1 "Reports distance between the customer's phone and the endpoint; raw 4095 = signal not available (SNA)";
CM_ SG_ 1067 VCSEC_UWBRearLeftDistance1 "Reports distance between the customer's phone and the endpoint; raw 4095 = signal not available (SNA)";
CM_ SG_ 1067 VCSEC_UWBCenterDistance1 "Reports distance between the customer's phone and the endpoint; raw 4095 = signal not available (SNA)";
CM_ SG_ 1067 VCSEC_UWBLeftDistance0 "Reports distance between the customer's phone and the endpoint; raw 4095 = signal not available (SNA)";
CM_ SG_ 1067 VCSEC_UWBRightDistance0 "Reports distance between the customer's phone and the endpoint; raw 4095 = signal not available (SNA)";
CM_ SG_ 1067 VCSEC_UWBRearDistance0 "Reports distance between the customer's phone and the endpoint; raw 4095 = signal not available (SNA)";
CM_ SG_ 1067 VCSEC_UWBRearLeftDistance0 "Reports distance between the customer's phone and the endpoint; raw 4095 = signal not available (SNA)";
CM_ SG_ 1067 VCSEC_UWBCenterDistance0 "Reports distance between the customer's phone and the endpoint; raw 4095 = signal not available (SNA)";
CM_ BO_ 761 "Vehicle security controller message: additional auth info; frame length from the layout, not yet observed on a vehicle bus";
CM_ SG_ 761 VCSEC_activeKeyDebug "Vehicle security controller: active key debug";
CM_ SG_ 761 VCSEC_bleChannelDisconnected "Connection between vehicle and the BLE authentication device is interrupted.";
CM_ SG_ 761 VCSEC_bleDisconnectionReason "Reasons of the disconnection between vehicle and BLE authentication device.";
CM_ SG_ 761 VCSEC_bleConnetionAttemptWLEntry "Vehicle security controller: ble connetion attempt WL entry";
CM_ SG_ 761 VCSEC_AdditionalAuthInfoIndex "Vehicle security controller: additional auth info index";
CM_ SG_ 761 VCSEC_activeKeyReason "Reason for picking the currently active key";
CM_ SG_ 761 VCSEC_activeKeySHA1 "Vehicle security controller: active key SHA1";
CM_ SG_ 761 VCSEC_algoUsedForSummonRange0 "Vehicle security controller: algo used for summon range0";
CM_ SG_ 761 VCSEC_keyWithinSummonRange0 "Vehicle security controller: key within summon range0";
CM_ SG_ 761 VCSEC_algoUsedForSummonRange1 "Vehicle security controller: algo used for summon range1";
CM_ SG_ 761 VCSEC_keyWithinSummonRange1 "Vehicle security controller: key within summon range1";
CM_ SG_ 761 VCSEC_algoUsedForSummonRange2 "Vehicle security controller: algo used for summon range2";
CM_ SG_ 761 VCSEC_keyWithinSummonRange2 "Vehicle security controller: key within summon range2";
CM_ SG_ 761 VCSEC_BLEDeviceWithinSummonRange "Vehicle security controller: BLE device within summon range";
CM_ SG_ 761 VCSEC_algoUWBInteriorPresence "Vehicle security controller: algo UWB interior presence";
CM_ SG_ 761 VCSEC_frunkOpenSuggestionRespons "Vehicle security controller: frunk open suggestion response";
CM_ SG_ 761 VCSEC_NFCAuthFromBPillarFormFact "Reports the form factor authentication at B-pillar Near Field Communication (NFC) reader.";
CM_ SG_ 761 VCSEC_NFCAuthFromCenterConsoleFo "Reports the form factor authenticating at center console Near Field Communication (NFC) reader.";
CM_ SG_ 761 VCSEC_trunkOpenSuggestionRespons "Vehicle security controller: trunk open suggestion response";
CM_ SG_ 761 VCSEC_algoTrunkSuggestionRaw "Vehicle security controller: algo trunk suggestion raw";
CM_ SG_ 761 VCSEC_algoTrunkSuggestionProc "Vehicle security controller: algo trunk suggestion proc";
CM_ SG_ 761 VCSEC_algoTrunkSuggestionRearmAl "Vehicle security controller: algo trunk suggestion rearm allowed";
CM_ SG_ 761 VCSEC_algoFrunkSuggestionRaw "Vehicle security controller: algo frunk suggestion raw";
CM_ SG_ 761 VCSEC_algoFrunkSuggestionProc "Vehicle security controller: algo frunk suggestion proc";
CM_ SG_ 761 VCSEC_algoFrunkSuggestionRearmAl "Vehicle security controller: algo frunk suggestion rearm allowed";
CM_ BO_ 1328 "Vehicle security controller message: alert log; frame length from the layout, not yet observed on a vehicle bus";
CM_ SG_ 1328 VCSEC_alertID "Vehicle security controller: alert ID";
CM_ SG_ 1328 VCSEC_alertState "Vehicle security controller: alert state";
CM_ SG_ 1328 VCSEC_a001_InternalWatchdog "Vehicle security controller: a001 internal watchdog";
CM_ SG_ 1328 VCSEC_a010_UnderVoltageDetected "Vehicle security controller: a010 under voltage detected";
CM_ SG_ 1328 VCSEC_a010_UnderVoltageTimeout "Vehicle security controller: a010 under voltage timeout";
CM_ SG_ 1328 VCSEC_a015_NVMMMemOverflow "Vehicle security controller: a015 NVMM mem overflow";
CM_ SG_ 1328 VCSEC_a015_NVMMFilesystemError "Vehicle security controller: a015 NVMM filesystem error";
CM_ SG_ 1328 VCSEC_a015_NVMMRecordIDError "Vehicle security controller: a015 NVMM record ID error";
CM_ SG_ 1328 VCSEC_a057_VEH_cpControl "Vehicle security controller: a057 VEH cp control";
CM_ SG_ 1328 VCSEC_a059_voltageDrop "Vehicle security controller: a059 voltage drop";
CM_ SG_ 1328 VCSEC_a059_resistanceEstimate "Vehicle security controller: a059 resistance estimate";
CM_ SG_ 1328 VCSEC_a059_current "Vehicle security controller: a059 current";
CM_ SG_ 1328 VCSEC_a063_switchChannel "Vehicle security controller: a063 switch channel";
CM_ SG_ 1328 VCSEC_a063_switchType "Vehicle security controller: a063 switch type";
CM_ SG_ 1328 VCSEC_a063_ADCVoltage "Vehicle security controller: a063 ADC voltage";
CM_ SG_ 1328 VCSEC_a063_disconnected "Vehicle security controller: a063 disconnected";
CM_ SG_ 1328 VCSEC_a063_indeterminate "Vehicle security controller: a063 indeterminate";
CM_ SG_ 1328 VCSEC_a063_stuckActive "Vehicle security controller: a063 stuck active";
CM_ SG_ 1328 VCSEC_a063_faulted "Vehicle security controller: a063 faulted";
CM_ SG_ 1328 VCSEC_a082_RIPC_epbPrivateState "Vehicle security controller: a082 RIPC epb private state";
CM_ SG_ 1328 VCSEC_a082_RIPC_remoteHSD "Vehicle security controller: a082 RIPC remote HSD";
CM_ SG_ 1328 VCSEC_a082_RIPC_railStatus "Vehicle security controller: a082 RIPC rail status";
CM_ SG_ 1328 VCSEC_a082_RIPC_remoteMux "Vehicle security controller: a082 RIPC remote mux";
CM_ SG_ 1328 VCSEC_a083_LIPC_epbPrivateState "Vehicle security controller: a083 LIPC epb private state";
CM_ SG_ 1328 VCSEC_a083_LIPC_remoteHSD "Vehicle security controller: a083 LIPC remote HSD";
CM_ SG_ 1328 VCSEC_a083_LIPC_railStatus "Vehicle security controller: a083 LIPC rail status";
CM_ SG_ 1328 VCSEC_a083_LIPC_HSDFaults "Vehicle security controller: a083 LIPC HSD faults";
CM_ SG_ 1328 VCSEC_a084_CH_StatusC "Vehicle security controller: a084 CH status c";
CM_ SG_ 1328 VCSEC_a085_PARTY_buttonStatus "Vehicle security controller: a085 PARTY button status";
CM_ SG_ 1328 VCSEC_a086_VEH_LVBMS_statusHigh "Vehicle security controller: a086 VEH LVBMS status high";
CM_ SG_ 1328 VCSEC_a086_VEH_LVBMS_statusLow "Vehicle security controller: a086 VEH LVBMS status low";
CM_ SG_ 1328 VCSEC_a086_VEH_status "Vehicle security controller: a086 VEH status";
CM_ SG_ 1328 VCSEC_a086_VEH_12VBatteryStatus "Vehicle security controller: a086 VEH 12 v battery status";
CM_ SG_ 1328 VCSEC_a086_VEH_LVPowerState "Vehicle security controller: a086 VEH LV power state";
CM_ SG_ 1328 VCSEC_a086_VEH_lightStatus "Vehicle security controller: a086 VEH light status";
CM_ SG_ 1328 VCSEC_a086_VEH_systemStatus "Vehicle security controller: a086 VEH system status";
CM_ SG_ 1328 VCSEC_a086_VEH_thermalStatus "Vehicle security controller: a086 VEH thermal status";
CM_ SG_ 1328 VCSEC_a086_VEH_vehNm "Vehicle security controller: a086 VEH veh nm";
CM_ SG_ 1328 VCSEC_a087_VEH_temperature "Vehicle security controller: a087 VEH temperature";
CM_ SG_ 1328 VCSEC_a087_VEH_thermalControl "Vehicle security controller: a087 VEH thermal control";
CM_ SG_ 1328 VCSEC_a087_VEH_torque "Vehicle security controller: a087 VEH torque";
CM_ SG_ 1328 VCSEC_a087_VEH_status "Vehicle security controller: a087 VEH status";
CM_ SG_ 1328 VCSEC_a087_PARTY_torque "Vehicle security controller: a087 PARTY torque";
CM_ SG_ 1328 VCSEC_a087_PARTY_status "Vehicle security controller: a087 PARTY status";
CM_ SG_ 1328 VCSEC_a087_PARTY_temperature "Vehicle security controller: a087 PARTY temperature";
CM_ SG_ 1328 VCSEC_a087_PARTY_thermalControl "Vehicle security controller: a087 PARTY thermal control";
CM_ SG_ 1328 VCSEC_a087_VEH_motorStatus "Vehicle security controller: a087 VEH motor status";
CM_ SG_ 1328 VCSEC_a088_VEH_temperature "Vehicle security controller: a088 VEH temperature";
CM_ SG_ 1328 VCSEC_a088_VEH_thermalControl "Vehicle security controller: a088 VEH thermal control";
CM_ SG_ 1328 VCSEC_a088_VEH_torque "Vehicle security controller: a088 VEH torque";
CM_ SG_ 1328 VCSEC_a088_VEH_status "Vehicle security controller: a088 VEH status";
CM_ SG_ 1328 VCSEC_a088_PARTY_torque "Vehicle security controller: a088 PARTY torque";
CM_ SG_ 1328 VCSEC_a088_PARTY_status "Vehicle security controller: a088 PARTY status";
CM_ SG_ 1328 VCSEC_a088_PARTY_temperature "Vehicle security controller: a088 PARTY temperature";
CM_ SG_ 1328 VCSEC_a088_PARTY_thermalControl "Vehicle security controller: a088 PARTY thermal control";
CM_ SG_ 1328 VCSEC_a088_VEH_motorStatus "Vehicle security controller: a088 VEH motor status";
CM_ SG_ 1328 VCSEC_a089_PARTY_party1 "Vehicle security controller: a089 PARTY party1";
CM_ SG_ 1328 VCSEC_a089_PARTY_status "Vehicle security controller: a089 PARTY status";
CM_ SG_ 1328 VCSEC_a089_VEH_status "Vehicle security controller: a089 VEH status";
CM_ SG_ 1328 VCSEC_a089_BDY_party1 "Vehicle security controller: a089 BDY party1";
CM_ SG_ 1328 VCSEC_a089_BDY_status "Vehicle security controller: a089 BDY status";
CM_ SG_ 1328 VCSEC_a089_CH_status "Vehicle security controller: a089 CH status";
CM_ SG_ 1328 VCSEC_a089_CH_party1 "Vehicle security controller: a089 CH party1";
CM_ SG_ 1328 VCSEC_a089_CH_party3 "Vehicle security controller: a089 CH party3";
CM_ SG_ 1328 VCSEC_a089_VEH_party1 "Vehicle security controller: a089 VEH party1";
CM_ SG_ 1328 VCSEC_a089_VEH_party3 "Vehicle security controller: a089 VEH party3";
CM_ SG_ 1328 VCSEC_a091_VEH_faultsAndExtras "Vehicle security controller: a091 VEH faults and extras";
CM_ SG_ 1328 VCSEC_a091_VEH_info "Vehicle security controller: a091 VEH info";
CM_ SG_ 1328 VCSEC_a091_VEH_state "Vehicle security controller: a091 VEH state";
CM_ SG_ 1328 VCSEC_a092_VEH_restraintStatus "Vehicle security controller: a092 VEH restraint status";
CM_ SG_ 1328 VCSEC_a092_VEH_switchStatus "Vehicle security controller: a092 VEH switch status";
CM_ SG_ 1328 VCSEC_a092_VEH_seatStatus2 "Vehicle security controller: a092 VEH seat status2";
CM_ SG_ 1328 VCSEC_a092_VEH_vehNm "Vehicle security controller: a092 VEH veh nm";
CM_ SG_ 1328 VCSEC_a093_VEH_restraintStatus "Vehicle security controller: a093 VEH restraint status";
CM_ SG_ 1328 VCSEC_a093_VEH_switchStatus "Vehicle security controller: a093 VEH switch status";
CM_ SG_ 1328 VCSEC_a093_VEH_seatStatus2 "Vehicle security controller: a093 VEH seat status2";
CM_ SG_ 1328 VCSEC_a093_VEH_vehNm "Vehicle security controller: a093 VEH veh nm";
CM_ SG_ 1328 VCSEC_a094_VEH_sysStatus "Vehicle security controller: a094 VEH sys status";
CM_ SG_ 1328 VCSEC_a094_PARTY_sysStatus "Vehicle security controller: a094 PARTY sys status";
CM_ SG_ 1328 VCSEC_a094_CH_sysStatus "Vehicle security controller: a094 CH sys status";
CM_ SG_ 1328 VCSEC_a095_PT_ptNm "Vehicle security controller: a095 PT pt nm";
CM_ SG_ 1328 VCSEC_a095_PT_status "Vehicle security controller: a095 PT status";
CM_ SG_ 1328 VCSEC_a096_VEH_status "Vehicle security controller: a096 VEH status";
CM_ SG_ 1328 VCSEC_a096_CH_status "Vehicle security controller: a096 CH status";
CM_ SG_ 1328 VCSEC_a097_VEH_HVStatus "Vehicle security controller: a097 VEH HV status";
CM_ SG_ 1328 VCSEC_a097_VEH_state "Vehicle security controller: a097 VEH state";
CM_ SG_ 1328 VCSEC_a098_CH_torque "Vehicle security controller: a098 CH torque";
CM_ SG_ 1328 VCSEC_a098_VEH_hvStatus "Vehicle security controller: a098 VEH hv status";
CM_ SG_ 1328 VCSEC_a098_VEH_status "Vehicle security controller: a098 VEH status";
CM_ SG_ 1328 VCSEC_a098_VEH_thermalControl "Vehicle security controller: a098 VEH thermal control";
CM_ SG_ 1328 VCSEC_a098_VEH_temperature "Vehicle security controller: a098 VEH temperature";
CM_ SG_ 1328 VCSEC_a098_VEH_torque "Vehicle security controller: a098 VEH torque";
CM_ SG_ 1328 VCSEC_a098_PARTY_status "Vehicle security controller: a098 PARTY status";
CM_ SG_ 1328 VCSEC_a098_PARTY_temperature "Vehicle security controller: a098 PARTY temperature";
CM_ SG_ 1328 VCSEC_a098_PARTY_thermalControl "Vehicle security controller: a098 PARTY thermal control";
CM_ SG_ 1328 VCSEC_a098_PARTY_torque "Vehicle security controller: a098 PARTY torque";
CM_ SG_ 1328 VCSEC_a098_PT_thermalControl "Vehicle security controller: a098 PT thermal control";
CM_ SG_ 1328 VCSEC_a098_PT_temperature "Vehicle security controller: a098 PT temperature";
CM_ SG_ 1328 VCSEC_a098_PARTY_motorStatus "Vehicle security controller: a098 PARTY motor status";
CM_ SG_ 1328 VCSEC_a098_VEH_motorStatus "Vehicle security controller: a098 VEH motor status";
CM_ SG_ 1328 VCSEC_a099_VEH_oocStatus "Vehicle security controller: a099 VEH ooc status";
CM_ SG_ 1328 VCSEC_a100_VEH "Vehicle security controller: a100 VEH";
CM_ SG_ 1328 VCSEC_a100_PARTY "Vehicle security controller: a100 PARTY";
CM_ SG_ 1328 VCSEC_a100_PT "Vehicle security controller: a100 PT";
CM_ SG_ 1328 VCSEC_a100_CH "Vehicle security controller: a100 CH";
CM_ SG_ 1328 VCSEC_a100_OBD "Vehicle security controller: a100 OBD";
CM_ SG_ 1328 VCSEC_a101_VEH_state "Vehicle security controller: a101 VEH state";
CM_ SG_ 1328 VCSEC_a101_PARTY_locState "Vehicle security controller: a101 PARTY loc state";
CM_ SG_ 1328 VCSEC_a101_LIPC_externalWatchdog "Vehicle security controller: a101 LIPC external watchdog heart beat";
CM_ SG_ 1328 VCSEC_a101_VEH_locState "Vehicle security controller: a101 VEH loc state";
CM_ SG_ 1328 VCSEC_a101_BDY_locState "Vehicle security controller: a101 BDY loc state";
CM_ SG_ 1328 VCSEC_a102_VEH_faultsAndExtras "Vehicle security controller: a102 VEH faults and extras";
CM_ SG_ 1328 VCSEC_a102_VEH_feedbackStatus "Vehicle security controller: a102 VEH feedback status";
CM_ SG_ 1328 VCSEC_a102_VEH_sensorStatus "Vehicle security controller: a102 VEH sensor status";
CM_ SG_ 1328 VCSEC_a102_VEH_rods "Vehicle security controller: a102 VEH rods";
CM_ SG_ 1328 VCSEC_a103_VEH_hvsNm "Vehicle security controller: a103 VEH hvs nm";
CM_ SG_ 1328 VCSEC_a103_VEH_vehNm "Vehicle security controller: a103 VEH veh nm";
CM_ SG_ 1328 VCSEC_a103_VEH_status "Vehicle security controller: a103 VEH status";
CM_ SG_ 1328 VCSEC_a103_PT_ptNm "Vehicle security controller: a103 PT pt nm";
CM_ SG_ 1328 VCSEC_a103_PT_status "Vehicle security controller: a103 PT status";
CM_ SG_ 1328 VCSEC_a103_VEH_evseStatus "Vehicle security controller: a103 VEH evse status";
CM_ SG_ 1328 VCSEC_a105_VEH_states "Vehicle security controller: a105 VEH states";
CM_ SG_ 1328 VCSEC_a105_VEH_chNm "Vehicle security controller: a105 VEH ch nm";
CM_ SG_ 1328 VCSEC_a105_VEH_dampingStates "Vehicle security controller: a105 VEH damping states";
CM_ SG_ 1328 VCSEC_a106_VEH_dcdcStatus "Vehicle security controller: a106 VEH dcdc status";
CM_ SG_ 1328 VCSEC_a106_VEH_thermalControl "Vehicle security controller: a106 VEH thermal control";
CM_ SG_ 1328 VCSEC_a106_VEH_dcdcRailStatus "Vehicle security controller: a106 VEH dcdc rail status";
CM_ SG_ 1328 VCSEC_a106_CH_dcdcRailStatus "Vehicle security controller: a106 CH dcdc rail status";
CM_ SG_ 1328 VCSEC_a106_CH_alertMatrix "Vehicle security controller: a106 CH alert matrix";
CM_ SG_ 1328 VCSEC_a107_VEH_hvsNm "Vehicle security controller: a107 VEH hvs nm";
CM_ SG_ 1328 VCSEC_a107_VEH_vehNm "Vehicle security controller: a107 VEH veh nm";
CM_ SG_ 1328 VCSEC_a107_VEH_status "Vehicle security controller: a107 VEH status";
CM_ SG_ 1328 VCSEC_a107_VEH_thermalStatus "Vehicle security controller: a107 VEH thermal status";
CM_ SG_ 1328 VCSEC_a107_VEH_bmbMinMax "Vehicle security controller: a107 VEH bmb min max";
CM_ SG_ 1328 VCSEC_a107_VEH_powerAvailable "Vehicle security controller: a107 VEH power available";
CM_ SG_ 1328 VCSEC_a107_PT_ptNm "Vehicle security controller: a107 PT pt nm";
CM_ SG_ 1328 VCSEC_a107_PT_status "Vehicle security controller: a107 PT status";
CM_ SG_ 1328 VCSEC_a107_PT_thermalStatus "Vehicle security controller: a107 PT thermal status";
CM_ SG_ 1328 VCSEC_a107_PT_socStatus "Vehicle security controller: a107 PT soc status";
CM_ SG_ 1328 VCSEC_a107_VEH_socStatus "Vehicle security controller: a107 VEH soc status";
CM_ SG_ 1328 VCSEC_a107_VEH_packConfig "Vehicle security controller: a107 VEH pack config";
CM_ SG_ 1328 VCSEC_a107_VEH_energyStatus "Vehicle security controller: a107 VEH energy status";
CM_ SG_ 1328 VCSEC_a107_VEH_chargeInfo "Vehicle security controller: a107 VEH charge info";
CM_ SG_ 1328 VCSEC_a108_VEH_hvStatus "Vehicle security controller: a108 VEH hv status";
CM_ SG_ 1328 VCSEC_a108_VEH_temperature "Vehicle security controller: a108 VEH temperature";
CM_ SG_ 1328 VCSEC_a108_VEH_thermalControl "Vehicle security controller: a108 VEH thermal control";
CM_ SG_ 1328 VCSEC_a108_VEH_torque "Vehicle security controller: a108 VEH torque";
CM_ SG_ 1328 VCSEC_a108_VEH_status "Vehicle security controller: a108 VEH status";
CM_ SG_ 1328 VCSEC_a108_PARTY_torque "Vehicle security controller: a108 PARTY torque";
CM_ SG_ 1328 VCSEC_a108_PARTY_status "Vehicle security controller: a108 PARTY status";
CM_ SG_ 1328 VCSEC_a108_PARTY_temperature "Vehicle security controller: a108 PARTY temperature";
CM_ SG_ 1328 VCSEC_a108_PARTY_thermalControl "Vehicle security controller: a108 PARTY thermal control";
CM_ SG_ 1328 VCSEC_a108_PT_temperature "Vehicle security controller: a108 PT temperature";
CM_ SG_ 1328 VCSEC_a108_PT_thermalControl "Vehicle security controller: a108 PT thermal control";
CM_ SG_ 1328 VCSEC_a108_PARTY_motorStatus "Vehicle security controller: a108 PARTY motor status";
CM_ SG_ 1328 VCSEC_a108_VEH_motorStatus "Vehicle security controller: a108 VEH motor status";
CM_ SG_ 1328 VCSEC_a108_CH_torque "Vehicle security controller: a108 CH torque";
CM_ SG_ 1328 VCSEC_a110_VEH_carState "Vehicle security controller: a110 VEH car state";
CM_ SG_ 1328 VCSEC_a110_VEH_carConfig "Vehicle security controller: a110 VEH car config";
CM_ SG_ 1328 VCSEC_a110_VEH_time "Vehicle security controller: a110 VEH time";
CM_ SG_ 1328 VCSEC_a110_VEH_updateStatus "Vehicle security controller: a110 VEH update status";
CM_ SG_ 1328 VCSEC_a110_VEH_vehNm "Vehicle security controller: a110 VEH veh nm";
CM_ SG_ 1328 VCSEC_a110_VEH_mismatchFault "Vehicle security controller: a110 VEH mismatch fault";
CM_ SG_ 1328 VCSEC_a110_VEH_vin "Vehicle security controller: a110 VEH vin";
CM_ SG_ 1328 VCSEC_a110_VEH_bmpDebug "Vehicle security controller: a110 VEH bmp debug";
CM_ SG_ 1328 VCSEC_a110_VEH_gearControl "Vehicle security controller: a110 VEH gear control";
CM_ SG_ 1328 VCSEC_a110_VEH_canLogAvailabilit "Vehicle security controller: a110 VEH can log availability";
CM_ SG_ 1328 VCSEC_a110_CH_airbagCutoffStatus "Vehicle security controller: a110 CH airbag cutoff status";
CM_ SG_ 1328 VCSEC_a110_CH_carConfig "Vehicle security controller: a110 CH car config";
CM_ SG_ 1328 VCSEC_a110_CH_carState "Vehicle security controller: a110 CH car state";
CM_ SG_ 1328 VCSEC_a110_CH_vin "Vehicle security controller: a110 CH vin";
CM_ SG_ 1328 VCSEC_a110_CH_chNm "Vehicle security controller: a110 CH ch nm";
CM_ SG_ 1328 VCSEC_a110_CH_epochTimeGtw "Vehicle security controller: a110 CH epoch time gtw";
CM_ SG_ 1328 VCSEC_a110_PARTY_carConfig "Vehicle security controller: a110 PARTY car config";
CM_ SG_ 1328 VCSEC_a111_VEH_internalStatus "Vehicle security controller: a111 VEH internal status";
CM_ SG_ 1328 VCSEC_a111_VEH_status "Vehicle security controller: a111 VEH status";
CM_ SG_ 1328 VCSEC_a111_VEH_vehNm "Vehicle security controller: a111 VEH veh nm";
CM_ SG_ 1328 VCSEC_a111_RIPC_LVPowerState "Vehicle security controller: a111 RIPC LV power state";
CM_ SG_ 1328 VCSEC_a111_RIPC_epbPrivateState "Vehicle security controller: a111 RIPC epb private state";
CM_ SG_ 1328 VCSEC_a111_RIPC_railStatus "Vehicle security controller: a111 RIPC rail status";
CM_ SG_ 1328 VCSEC_a111_RIPC_remoteADC "Vehicle security controller: a111 RIPC remote ADC";
CM_ SG_ 1328 VCSEC_a111_RIPC_switchStatus "Vehicle security controller: a111 RIPC switch status";
CM_ SG_ 1328 VCSEC_a111_VEH_LVPowerState "Vehicle security controller: a111 VEH LV power state";
CM_ SG_ 1328 VCSEC_a111_VEH_seatStatus "Vehicle security controller: a111 VEH seat status";
CM_ SG_ 1328 VCSEC_a111_PARTY_status "Vehicle security controller: a111 PARTY status";
CM_ SG_ 1328 VCSEC_a111_CH_status "Vehicle security controller: a111 CH status";
CM_ SG_ 1328 VCSEC_a112_VEH_internalStatus "Vehicle security controller: a112 VEH internal status";
CM_ SG_ 1328 VCSEC_a112_VEH_status "Vehicle security controller: a112 VEH status";
CM_ SG_ 1328 VCSEC_a112_VEH_vehNm "Vehicle security controller: a112 VEH veh nm";
CM_ SG_ 1328 VCSEC_a112_LIPC_LVPowerState "Vehicle security controller: a112 LIPC LV power state";
CM_ SG_ 1328 VCSEC_a112_LIPC_epbPrivateState "Vehicle security controller: a112 LIPC epb private state";
CM_ SG_ 1328 VCSEC_a112_LIPC_railStatus "Vehicle security controller: a112 LIPC rail status";
CM_ SG_ 1328 VCSEC_a112_LIPC_remoteADC "Vehicle security controller: a112 LIPC remote ADC";
CM_ SG_ 1328 VCSEC_a112_LIPC_switchStatus "Vehicle security controller: a112 LIPC switch status";
CM_ SG_ 1328 VCSEC_a112_VEH_LVPowerState "Vehicle security controller: a112 VEH LV power state";
CM_ SG_ 1328 VCSEC_a112_PARTY_status "Vehicle security controller: a112 PARTY status";
CM_ SG_ 1328 VCSEC_a112_CH_status "Vehicle security controller: a112 CH status";
CM_ SG_ 1328 VCSEC_a114_PARTY_status "Vehicle security controller: a114 PARTY status";
CM_ SG_ 1328 VCSEC_a114_PARTY_wheelSpeeds "Vehicle security controller: a114 PARTY wheel speeds";
CM_ SG_ 1328 VCSEC_a114_VEH_wheelSpeeds "Vehicle security controller: a114 VEH wheel speeds";
CM_ SG_ 1328 VCSEC_a114_CH_wheelSpeeds "Vehicle security controller: a114 CH wheel speeds";
CM_ SG_ 1328 VCSEC_a114_PARTY_party3 "Vehicle security controller: a114 PARTY party3";
CM_ SG_ 1328 VCSEC_a114_VEH_party3 "Vehicle security controller: a114 VEH party3";
CM_ SG_ 1328 VCSEC_a114_VEH_status "Vehicle security controller: a114 VEH status";
CM_ SG_ 1328 VCSEC_a114_PARTY_wheelRotation "Vehicle security controller: a114 PARTY wheel rotation";
CM_ SG_ 1328 VCSEC_a114_CH_wheelRotation "Vehicle security controller: a114 CH wheel rotation";
CM_ SG_ 1328 VCSEC_a114_VEH_wheelRotation "Vehicle security controller: a114 VEH wheel rotation";
CM_ SG_ 1328 VCSEC_a114_PARTY_brakeTorque "Vehicle security controller: a114 PARTY brake torque";
CM_ SG_ 1328 VCSEC_a114_PARTY_offsets "Vehicle security controller: a114 PARTY offsets";
CM_ SG_ 1328 VCSEC_a114_BDY_offsets "Vehicle security controller: a114 BDY offsets";
CM_ SG_ 1328 VCSEC_a114_BDY_party3 "Vehicle security controller: a114 BDY party3";
CM_ SG_ 1328 VCSEC_a114_BDY_status "Vehicle security controller: a114 BDY status";
CM_ SG_ 1328 VCSEC_a114_BDY_wheelRotation "Vehicle security controller: a114 BDY wheel rotation";
CM_ SG_ 1328 VCSEC_a114_BDY_wheelSpeeds "Vehicle security controller: a114 BDY wheel speeds";
CM_ SG_ 1328 VCSEC_a114_CH_party1 "Vehicle security controller: a114 CH party1";
CM_ SG_ 1328 VCSEC_a114_CH_party3 "Vehicle security controller: a114 CH party3";
CM_ SG_ 1328 VCSEC_a114_CH_status "Vehicle security controller: a114 CH status";
CM_ SG_ 1328 VCSEC_a115_VEH_vehNm "Vehicle security controller: a115 VEH veh nm";
CM_ SG_ 1328 VCSEC_a115_VEH_authentication "Vehicle security controller: a115 VEH authentication";
CM_ SG_ 1328 VCSEC_a115_VEH_BLEResetRequest "Vehicle security controller: a115 VEH BLE reset request";
CM_ SG_ 1328 VCSEC_a115_VEH_requests "Vehicle security controller: a115 VEH requests";
CM_ SG_ 1328 VCSEC_a115_VEH_requests2 "Vehicle security controller: a115 VEH requests2";
CM_ SG_ 1328 VCSEC_a115_REM_authentication "Vehicle security controller: a115 REM authentication";
CM_ SG_ 1328 VCSEC_a115_UI_corianderVehicleCo "Vehicle security controller: a115 UI coriander vehicle control";
CM_ SG_ 1328 VCSEC_a115_CH_TPMSDisplay "Vehicle security controller: a115 CH TPMS display";
CM_ SG_ 1328 VCSEC_a116_PARTY_epbmStatus "Vehicle security controller: a116 PARTY epbm status";
CM_ SG_ 1328 VCSEC_a116_VEH_vehNm "Vehicle security controller: a116 VEH veh nm";
CM_ SG_ 1328 VCSEC_a116_VEH_hvacRequest "Vehicle security controller: a116 VEH hvac request";
CM_ SG_ 1328 VCSEC_a116_VEH_hvacStatus "Vehicle security controller: a116 VEH hvac status";
CM_ SG_ 1328 VCSEC_a116_VEH_LVPowerState "Vehicle security controller: a116 VEH LV power state";
CM_ SG_ 1328 VCSEC_a116_VEH_lightStatus "Vehicle security controller: a116 VEH light status";
CM_ SG_ 1328 VCSEC_a116_VEH_seatStatus "Vehicle security controller: a116 VEH seat status";
CM_ SG_ 1328 VCSEC_a116_VEH_thsStatus "Vehicle security controller: a116 VEH ths status";
CM_ SG_ 1328 VCSEC_a116_VEH_doorStatus "Vehicle security controller: a116 VEH door status";
CM_ SG_ 1328 VCSEC_a116_VEH_seatHeatStatus "Vehicle security controller: a116 VEH seat heat status";
CM_ SG_ 1328 VCSEC_a116_VEH_restraintStatus "Vehicle security controller: a116 VEH restraint status";
CM_ SG_ 1328 VCSEC_a116_VEH_switchStatus "Vehicle security controller: a116 VEH switch status";
CM_ SG_ 1328 VCSEC_a116_VEH_logging1Hz "Vehicle security controller: a116 VEH logging1 hz";
CM_ SG_ 1328 VCSEC_a116_VEH_seatStatus2 "Vehicle security controller: a116 VEH seat status2";
CM_ SG_ 1328 VCSEC_a116_VEH_status "Vehicle security controller: a116 VEH status";
CM_ SG_ 1328 VCSEC_a116_VEH_thermalCommand "Vehicle security controller: a116 VEH thermal command";
CM_ SG_ 1328 VCSEC_a116_VEH_windowStatus "Vehicle security controller: a116 VEH window status";
CM_ SG_ 1328 VCSEC_a116_PARTY_restraintStatus "Vehicle security controller: a116 PARTY restraint status";
CM_ SG_ 1328 VCSEC_a116_PARTY_doorStatus "Vehicle security controller: a116 PARTY door status";
CM_ SG_ 1328 VCSEC_a116_BDY_epbmStatus "Vehicle security controller: a116 BDY epbm status";
CM_ SG_ 1328 VCSEC_a116_BDY_restraintStatus "Vehicle security controller: a116 BDY restraint status";
CM_ SG_ 1328 VCSEC_a116_BDY_switchStatus "Vehicle security controller: a116 BDY switch status";
CM_ SG_ 1328 VCSEC_a117_BDY_epbmStatus "Vehicle security controller: a117 BDY epbm status";
CM_ SG_ 1328 VCSEC_a117_BDY_restraintStatus "Vehicle security controller: a117 BDY restraint status";
CM_ SG_ 1328 VCSEC_a117_VEH_prndStatus "Vehicle security controller: a117 VEH prnd status";
CM_ SG_ 1328 VCSEC_a117_PARTY_epbmStatus "Vehicle security controller: a117 PARTY epbm status";
CM_ SG_ 1328 VCSEC_a117_VEH_vehNm "Vehicle security controller: a117 VEH veh nm";
CM_ SG_ 1328 VCSEC_a117_VEH_hvacBlowerFdb "Vehicle security controller: a117 VEH hvac blower fdb";
CM_ SG_ 1328 VCSEC_a117_VEH_LVPowerState "Vehicle security controller: a117 VEH LV power state";
CM_ SG_ 1328 VCSEC_a117_VEH_restraintStatus "Vehicle security controller: a117 VEH restraint status";
CM_ SG_ 1328 VCSEC_a117_VEH_lightStatus "Vehicle security controller: a117 VEH light status";
CM_ SG_ 1328 VCSEC_a117_VEH_seatStatus "Vehicle security controller: a117 VEH seat status";
CM_ SG_ 1328 VCSEC_a117_BDY_falconSwitchStatu "Vehicle security controller: a117 BDY falcon switch status";
CM_ SG_ 1328 VCSEC_a117_VEH_doorStatus "Vehicle security controller: a117 VEH door status";
CM_ SG_ 1328 VCSEC_a117_VEH_doorStatus2 "Vehicle security controller: a117 VEH door status2";
CM_ SG_ 1328 VCSEC_a117_VEH_windowStatus "Vehicle security controller: a117 VEH window status";
CM_ SG_ 1328 VCSEC_a117_VEH_switchStatus "Vehicle security controller: a117 VEH switch status";
CM_ SG_ 1328 VCSEC_a117_VEH_intrusionSensorSt "Vehicle security controller: a117 VEH intrusion sensor status";
CM_ SG_ 1328 VCSEC_a117_VEH_liftgateStatus "Vehicle security controller: a117 VEH liftgate status";
CM_ SG_ 1328 VCSEC_a117_VEH_seatStatus2 "Vehicle security controller: a117 VEH seat status2";
CM_ SG_ 1328 VCSEC_a117_PARTY_restraintStatus "Vehicle security controller: a117 PARTY restraint status";
CM_ SG_ 1328 VCSEC_a117_VEH_thermalStatus "Vehicle security controller: a117 VEH thermal status";
CM_ SG_ 1328 VCSEC_a117_PARTY_doorStatus "Vehicle security controller: a117 PARTY door status";
CM_ SG_ 1328 VCSEC_a117_VEH_status "Vehicle security controller: a117 VEH status";
CM_ SG_ 1328 VCSEC_a117_PARTY_prndStatus "Vehicle security controller: a117 PARTY prnd status";
CM_ SG_ 1328 VCSEC_a117_PARTY_lightingSeconda "Vehicle security controller: a117 PARTY lighting secondary";
CM_ SG_ 1328 VCSEC_a118_VEH_vehNm "Vehicle security controller: a118 VEH veh nm";
CM_ SG_ 1328 VCSEC_a118_VEH_lighting "Vehicle security controller: a118 VEH lighting";
CM_ SG_ 1328 VCSEC_a118_VEH_sensors "Vehicle security controller: a118 VEH sensors";
CM_ SG_ 1328 VCSEC_a118_VEH_status "Vehicle security controller: a118 VEH status";
CM_ SG_ 1328 VCSEC_a118_VEH_okToUseHighPwr "Vehicle security controller: a118 VEH ok to use high pwr";
CM_ SG_ 1328 VCSEC_a118_VEH_LVPowerState "Vehicle security controller: a118 VEH LV power state";
CM_ SG_ 1328 VCSEC_a118_VEH_coolant "Vehicle security controller: a118 VEH coolant";
CM_ SG_ 1328 VCSEC_a118_VEH_vehicleStatus "Vehicle security controller: a118 VEH vehicle status";
CM_ SG_ 1328 VCSEC_a118_VEH_12VBatteryStatus "Vehicle security controller: a118 VEH 12 v battery status";
CM_ SG_ 1328 VCSEC_a118_VEH_systemStatus "Vehicle security controller: a118 VEH system status";
CM_ SG_ 1328 VCSEC_a118_PARTY_LVPowerState "Vehicle security controller: a118 PARTY LV power state";
CM_ SG_ 1328 VCSEC_a118_PARTY_outputPowerStat "Vehicle security controller: a118 PARTY output power status";
CM_ SG_ 1328 VCSEC_a118_PARTY_vehicleTime "Vehicle security controller: a118 PARTY vehicle time";
CM_ SG_ 1328 VCSEC_a118_VEH_thermalCommand "Vehicle security controller: a118 VEH thermal command";
CM_ SG_ 1328 VCSEC_a118_CH_LVPowerState "Vehicle security controller: a118 CH LV power state";
CM_ SG_ 1328 VCSEC_a118_PARTY_sensors "Vehicle security controller: a118 PARTY sensors";
CM_ SG_ 1328 VCSEC_a118_CH_sensors "Vehicle security controller: a118 CH sensors";
CM_ SG_ 1328 VCSEC_a118_VEH_interNodeResistan "Vehicle security controller: a118 VEH inter node resistance";
CM_ SG_ 1328 VCSEC_a118_CH_lighting "Vehicle security controller: a118 CH lighting";
CM_ SG_ 1328 VCSEC_a118_VEH_lightStatus "Vehicle security controller: a118 VEH light status";
CM_ SG_ 1328 VCSEC_a118_PARTY_vehNm "Vehicle security controller: a118 PARTY veh nm";
CM_ SG_ 1328 VCSEC_a118_CH_12VBatteryStatus "Vehicle security controller: a118 CH 12 v battery status";
CM_ SG_ 1328 VCSEC_a118_CH_LVBMS_statusHigh "Vehicle security controller: a118 CH LVBMS status high";
CM_ SG_ 1328 VCSEC_a118_CH_alertMatrix "Vehicle security controller: a118 CH alert matrix";
CM_ SG_ 1328 VCSEC_a118_BDY_outputPowerStatus "Vehicle security controller: a118 BDY output power status";
CM_ SG_ 1328 VCSEC_a118_BDY_vehicleTime "Vehicle security controller: a118 BDY vehicle time";
CM_ SG_ 1328 VCSEC_a118_PARTY_AP_vehicleState "Vehicle security controller: a118 PARTY AP vehicle state1 hz muxed";
CM_ SG_ 1328 VCSEC_a118_BDY_AP_vehicleState1H "Vehicle security controller: a118 BDY AP vehicle state1 hz muxed";
CM_ SG_ 1328 VCSEC_a118_PARTY_VCFRONT_cameraC "Vehicle security controller: a118 PARTY VCFRONT camera cleaning status";
CM_ SG_ 1328 VCSEC_a119_VEH_steerAngle "Vehicle security controller: a119 VEH steer angle";
CM_ SG_ 1328 VCSEC_a119_VEH_leftStalk "Vehicle security controller: a119 VEH left stalk";
CM_ SG_ 1328 VCSEC_a119_VEH_rightStalk "Vehicle security controller: a119 VEH right stalk";
CM_ SG_ 1328 VCSEC_a119_PARTY_rightStalk "Vehicle security controller: a119 PARTY right stalk";
CM_ SG_ 1328 VCSEC_a119_CH_steerAngle "Vehicle security controller: a119 CH steer angle";
CM_ SG_ 1328 VCSEC_a119_PARTY_steerAngle "Vehicle security controller: a119 PARTY steer angle";
CM_ SG_ 1328 VCSEC_a120_PARTY_chassisCntl "Vehicle security controller: a120 PARTY chassis cntl";
CM_ SG_ 1328 VCSEC_a120_VEH_systemStatus "Vehicle security controller: a120 VEH system status";
CM_ SG_ 1328 VCSEC_a120_CH_chassisCntl "Vehicle security controller: a120 CH chassis cntl";
CM_ SG_ 1328 VCSEC_a120_PARTY_systemStatus "Vehicle security controller: a120 PARTY system status";
CM_ SG_ 1328 VCSEC_a120_PARTY_torque "Vehicle security controller: a120 PARTY torque";
CM_ SG_ 1328 VCSEC_a120_VEH_torque "Vehicle security controller: a120 VEH torque";
CM_ SG_ 1328 VCSEC_a120_PARTY_locStatus "Vehicle security controller: a120 PARTY loc status";
CM_ SG_ 1328 VCSEC_a120_PARTY_speed "Vehicle security controller: a120 PARTY speed";
CM_ SG_ 1328 VCSEC_a120_VEH_speed "Vehicle security controller: a120 VEH speed";
CM_ SG_ 1328 VCSEC_a120_PARTY_status "Vehicle security controller: a120 PARTY status";
CM_ SG_ 1328 VCSEC_a120_PT_speed "Vehicle security controller: a120 PT speed";
CM_ SG_ 1328 VCSEC_a120_PT_systemStatus "Vehicle security controller: a120 PT system status";
CM_ SG_ 1328 VCSEC_a120_PARTY_vehicleEstimate "Vehicle security controller: a120 PARTY vehicle estimates";
CM_ SG_ 1328 VCSEC_a120_VEH_aggregatedAxleSpe "Vehicle security controller: a120 VEH aggregated axle speed";
CM_ SG_ 1328 VCSEC_a120_PARTY_aggregatedAxleS "Vehicle security controller: a120 PARTY aggregated axle speed";
CM_ SG_ 1328 VCSEC_a120_VEH_systemPower "Vehicle security controller: a120 VEH system power";
CM_ SG_ 1328 VCSEC_a120_PARTY_autonomyHealth "Vehicle security controller: a120 PARTY autonomy health";
CM_ SG_ 1328 VCSEC_a120_VEH_autonomyHealth "Vehicle security controller: a120 VEH autonomy health";
CM_ SG_ 1328 VCSEC_a120_PT_systemPower "Vehicle security controller: a120 PT system power";
CM_ SG_ 1328 VCSEC_a120_PARTY_stalklessInterf "Vehicle security controller: a120 PARTY stalkless interfaces";
CM_ SG_ 1328 VCSEC_a120_CH_speed "Vehicle security controller: a120 CH speed";
CM_ SG_ 1328 VCSEC_a120_VEH_estimatedBrakeTem "Vehicle security controller: a120 VEH estimated brake temp";
CM_ SG_ 1328 VCSEC_a120_PARTY_prndControl "Vehicle security controller: a120 PARTY prnd control";
CM_ SG_ 1328 VCSEC_a120_PARTY_locStatus2 "Vehicle security controller: a120 PARTY loc status2";
CM_ SG_ 1328 VCSEC_a120_VEH_chassisCntl "Vehicle security controller: a120 VEH chassis cntl";
CM_ SG_ 1328 VCSEC_a120_CH_locStatus2 "Vehicle security controller: a120 CH loc status2";
CM_ SG_ 1328 VCSEC_a120_VEH_locStatus "Vehicle security controller: a120 VEH loc status";
CM_ SG_ 1328 VCSEC_a120_VEH_locStatus2 "Vehicle security controller: a120 VEH loc status2";
CM_ SG_ 1328 VCSEC_a120_VEH_prndControl "Vehicle security controller: a120 VEH prnd control";
CM_ SG_ 1328 VCSEC_a120_VEH_vehicleEstimates "Vehicle security controller: a120 VEH vehicle estimates";
CM_ SG_ 1328 VCSEC_a120_PARTY_motorStatus "Vehicle security controller: a120 PARTY motor status";
CM_ SG_ 1328 VCSEC_a120_VEH_motorStatus "Vehicle security controller: a120 VEH motor status";
CM_ SG_ 1328 VCSEC_a120_BDY_speed "Vehicle security controller: a120 BDY speed";
CM_ SG_ 1328 VCSEC_a121_VEH_status "Vehicle security controller: a121 VEH status";
CM_ SG_ 1328 VCSEC_a121_VEH_occupancy "Vehicle security controller: a121 VEH occupancy";
CM_ SG_ 1328 VCSEC_a133_alarmTriggerReason "Vehicle security controller: a133 alarm trigger reason";
CM_ SG_ 1328 VCSEC_a140_keyDidNotIdentify "Vehicle security controller: a140 key did not identify";
CM_ SG_ 1328 VCSEC_a140_keyNotPairedToTheCar "Vehicle security controller: a140 key not paired to the car";
CM_ SG_ 1328 VCSEC_a140_authenticationFailed "Vehicle security controller: a140 authentication failed";
CM_ SG_ 1328 VCSEC_a140_authenticationTimeout "Vehicle security controller: a140 authentication timeout";
CM_ SG_ 1328 VCSEC_a140_cardRmvdB4AuthComplet "Vehicle security controller: a140 card rmvd B4 auth complete";
CM_ SG_ 1328 VCSEC_a140_cardRmvdB4SndingChaln "Vehicle security controller: a140 card rmvd B4 snding chalng";
CM_ SG_ 1328 VCSEC_a140_cardRmvdB4SndingReqID "Vehicle security controller: a140 card rmvd B4 snding req ID";
CM_ SG_ 1328 VCSEC_a140_cardRmvdB4RecvingID "Vehicle security controller: a140 card rmvd B4 recving ID";
CM_ SG_ 1328 VCSEC_a140_multipleTriesToAuth "Vehicle security controller: a140 multiple tries to auth";
CM_ SG_ 1328 VCSEC_a177_newWhitelistSlot "Vehicle security controller: a177 new whitelist slot";
CM_ SG_ 1328 VCSEC_a177_signingKeySlot "Vehicle security controller: a177 signing key slot";
CM_ SG_ 1328 VCSEC_a177_newKeyPublicKey "Vehicle security controller: a177 new key public key";
CM_ SG_ 1328 VCSEC_a177_keyActiveTime "Vehicle security controller: a177 key active time";
CM_ SG_ 1328 VCSEC_a177_keyRole "Vehicle security controller: a177 key role";
CM_ SG_ 1328 VCSEC_a178_publicKey "Vehicle security controller: a178 public key";
CM_ SG_ 1328 VCSEC_a178_signingKeySlot "Vehicle security controller: a178 signing key slot";
CM_ SG_ 1328 VCSEC_a178_removedKeySlot "Vehicle security controller: a178 removed key slot";
CM_ SG_ 1328 VCSEC_a178_removedKeyRole "Vehicle security controller: a178 removed key role";
CM_ SG_ 1328 VCSEC_a191_clearWlist "Vehicle security controller: a191 clear wlist";
CM_ SG_ 1328 VCSEC_a191_WlistingDevice "Vehicle security controller: a191 wlisting device";
CM_ SG_ 1328 VCSEC_a191_failedToSendWlist "Vehicle security controller: a191 failed to send wlist";
CM_ SG_ 1328 VCSEC_a192_clearWlist "Vehicle security controller: a192 clear wlist";
CM_ SG_ 1328 VCSEC_a192_WlistingDevice "Vehicle security controller: a192 wlisting device";
CM_ SG_ 1328 VCSEC_a192_failedToSendWlist "Vehicle security controller: a192 failed to send wlist";
CM_ SG_ 1328 VCSEC_a193_clearWlist "Vehicle security controller: a193 clear wlist";
CM_ SG_ 1328 VCSEC_a193_WlistingDevice "Vehicle security controller: a193 wlisting device";
CM_ SG_ 1328 VCSEC_a193_failedToSendWlist "Vehicle security controller: a193 failed to send wlist";
CM_ SG_ 1328 VCSEC_a194_clearWlist "Vehicle security controller: a194 clear wlist";
CM_ SG_ 1328 VCSEC_a194_WlistingDevice "Vehicle security controller: a194 wlisting device";
CM_ SG_ 1328 VCSEC_a194_failedToSendWlist "Vehicle security controller: a194 failed to send wlist";
CM_ SG_ 1328 VCSEC_a197_connectionChannel "Vehicle security controller: a197 connection channel";
CM_ SG_ 1328 VCSEC_a197_connHandleMismatch "Vehicle security controller: a197 conn handle mismatch";
CM_ SG_ 1328 VCSEC_a197_confrmtnTimeout "Vehicle security controller: a197 confrmtn timeout";
CM_ SG_ 1328 VCSEC_a197_errorInconfrmtn "Vehicle security controller: a197 error inconfrmtn";
CM_ SG_ 1328 VCSEC_a210_whiteListChannel "Vehicle security controller: a210 white list channel";
CM_ SG_ 1328 VCSEC_a211_handlePulled "Vehicle security controller: a211 handle pulled";
CM_ SG_ 1328 VCSEC_a211_connectionCount "Vehicle security controller: a211 connection count";
CM_ SG_ 1328 VCSEC_a211_RSSIValidMatrix "Vehicle security controller: a211 RSSI valid matrix";
CM_ SG_ 1328 VCSEC_a211_DevicePresentCount "Vehicle security controller: a211 device present count";
CM_ SG_ 1328 VCSEC_a211_UnknownDevicePresent "Vehicle security controller: a211 unknown device present";
CM_ SG_ 1328 VCSEC_a211_AuthRequested "Vehicle security controller: a211 auth requested";
CM_ SG_ 1328 VCSEC_a211_MaximumRSSI "Vehicle security controller: a211 maximum RSSI";
CM_ SG_ 1328 VCSEC_a211_MaximumRSSIAntenna "Vehicle security controller: a211 maximum RSSI antenna";
CM_ SG_ 1328 VCSEC_a211_riderKeyConnected "Vehicle security controller: a211 rider key connected";
CM_ SG_ 1328 VCSEC_a211_FleetModeActive "Vehicle security controller: a211 fleet mode active";
CM_ SG_ 1328 VCSEC_a219_pairingRemovedSensor0 "Vehicle security controller: a219 pairing removed sensor0";
CM_ SG_ 1328 VCSEC_a219_pairingRemovedSensor1 "Vehicle security controller: a219 pairing removed sensor1";
CM_ SG_ 1328 VCSEC_a219_pairingRemovedSensor2 "Vehicle security controller: a219 pairing removed sensor2";
CM_ SG_ 1328 VCSEC_a219_pairingRemovedSensor3 "Vehicle security controller: a219 pairing removed sensor3";
CM_ SG_ 1328 VCSEC_a221_countryCode "Vehicle security controller: a221 country code";
CM_ SG_ 1328 VCSEC_a221_homologationRegion "Vehicle security controller: a221 homologation region";
CM_ SG_ 1328 VCSEC_a256_whitelistOperation "Vehicle security controller: a256 whitelist operation";
CM_ SG_ 1328 VCSEC_a256_failureReason "Vehicle security controller: a256 failure reason";
CM_ SG_ 1328 VCSEC_a256_whitelistSlot "Vehicle security controller: a256 whitelist slot";
CM_ SG_ 1328 VCSEC_a256_signingKeySlot "Vehicle security controller: a256 signing key slot";
CM_ SG_ 1328 VCSEC_a256_keyActiveTime "Vehicle security controller: a256 key active time";
CM_ SG_ 1328 VCSEC_a257_whitelistSlot "Vehicle security controller: a257 whitelist slot";
CM_ SG_ 1328 VCSEC_a257_keyID "Vehicle security controller: a257 key ID";
CM_ SG_ 1328 VCSEC_a257_keyActiveTime "Vehicle security controller: a257 key active time";
CM_ SG_ 1328 VCSEC_a257_permissionActiveTime "Vehicle security controller: a257 permission active time";
CM_ SG_ 1328 VCSEC_a266_pressure "Vehicle security controller: a266 pressure";
CM_ SG_ 1328 VCSEC_a267_pressure "Vehicle security controller: a267 pressure";
CM_ SG_ 1328 VCSEC_a268_pressure "Vehicle security controller: a268 pressure";
CM_ SG_ 1328 VCSEC_a269_pressure "Vehicle security controller: a269 pressure";
CM_ SG_ 1328 VCSEC_a270_pressure "Vehicle security controller: a270 pressure";
CM_ SG_ 1328 VCSEC_a271_pressure "Vehicle security controller: a271 pressure";
CM_ SG_ 1328 VCSEC_a272_pressure "Vehicle security controller: a272 pressure";
CM_ SG_ 1328 VCSEC_a273_pressure "Vehicle security controller: a273 pressure";
CM_ SG_ 1328 VCSEC_a311_whitelistChannel "Vehicle security controller: a311 whitelist channel";
CM_ SG_ 1328 VCSEC_a436_currentUHFHardware "Vehicle security controller: a436 current UHF hardware";
CM_ SG_ 1328 VCSEC_a436_expectedUHFHardware "Vehicle security controller: a436 expected UHF hardware";
CM_ SG_ 1328 VCSEC_a436_countryCode "Vehicle security controller: a436 country code";
CM_ SG_ 1328 VCSEC_a455_pressure "Vehicle security controller: a455 pressure";
CM_ SG_ 1328 VCSEC_a456_pressure "Vehicle security controller: a456 pressure";
CM_ SG_ 1328 VCSEC_a457_pressure "Vehicle security controller: a457 pressure";
CM_ SG_ 1328 VCSEC_a458_pressure "Vehicle security controller: a458 pressure";
CM_ SG_ 1328 VCSEC_a497_centerEndpointMismatc "Vehicle security controller: a497 center endpoint mismatch";
CM_ SG_ 1328 VCSEC_a497_cradleEndpointMismatc "Vehicle security controller: a497 cradle endpoint mismatch";
CM_ SG_ 1328 VCSEC_a497_leftEndpointMismatch "Vehicle security controller: a497 left endpoint mismatch";
CM_ SG_ 1328 VCSEC_a497_rightEndpointMismatch "Vehicle security controller: a497 right endpoint mismatch";
CM_ SG_ 1328 VCSEC_a497_rearLeftEndpointMisma "Vehicle security controller: a497 rear left endpoint mismatch";
CM_ SG_ 1328 VCSEC_a497_rearRightEndpointMism "Vehicle security controller: a497 rear right endpoint mismatch";
CM_ SG_ 1328 VCSEC_a497_endpointLocationToFix "Vehicle security controller: a497 endpoint location to fix";
CM_ SG_ 1328 VCSEC_a497_endpointExpectedPcbaI "Vehicle security controller: a497 endpoint expected pcba id";
CM_ SG_ 1328 VCSEC_a497_endpointExpectedAssem "Vehicle security controller: a497 endpoint expected assembly id";
CM_ SG_ 1328 VCSEC_a497_endpointExpectedUsage "Vehicle security controller: a497 endpoint expected usage id";
CM_ SG_ 1328 VCSEC_a497_endpointActualPcbaId "Vehicle security controller: a497 endpoint actual pcba id";
CM_ SG_ 1328 VCSEC_a497_endpointActualAssembl "Vehicle security controller: a497 endpoint actual assembly id";
CM_ SG_ 1328 VCSEC_a497_endpointActualUsageId "Vehicle security controller: a497 endpoint actual usage id";
CM_ SG_ 1328 VCSEC_a504_ecuUnprovisioned "Vehicle security controller: a504 ecu unprovisioned";
CM_ SG_ 1328 VCSEC_a505_excessiveMacFailures "Vehicle security controller: a505 excessive mac failures";
CM_ SG_ 1328 VCSEC_a517_pressure "Vehicle security controller: a517 pressure";
CM_ SG_ 1328 VCSEC_a518_pressure "Vehicle security controller: a518 pressure";
CM_ SG_ 1328 VCSEC_a519_pressure "Vehicle security controller: a519 pressure";
CM_ SG_ 1328 VCSEC_a520_pressure "Vehicle security controller: a520 pressure";
BA_DEF_ BO_ "GenMsgCycleTime" INT 0 3600000;
BA_DEF_ BO_ "GenMsgSendType" ENUM "Cyclic","NotUsed","NotUsed","NotUsed","NotUsed","NotUsed","NotUsed","IfActive","NoMsgSendType","NotUsed";
BA_DEF_ BO_ "VFrameFormat" ENUM "StandardCAN","ExtendedCAN","reserved","J1939PG","reserved","reserved","reserved","reserved","reserved","reserved","reserved","reserved","reserved","reserved","StandardCAN_FD","ExtendedCAN_FD";
BA_DEF_ BO_ "CANFD_BRS" ENUM "0","1";
BA_DEF_ SG_ "GenSigSNA" STRING;
BA_DEF_ SG_ "SystemSignalLongSymbol" STRING;
BA_DEF_ SG_ "Confidence" ENUM "validated","plausible","layout-only","contradicted";
BA_DEF_DEF_ "GenMsgCycleTime" 0;
BA_DEF_DEF_ "GenMsgSendType" "NoMsgSendType";
BA_DEF_DEF_ "VFrameFormat" "StandardCAN";
BA_DEF_DEF_ "CANFD_BRS" "1";
BA_DEF_DEF_ "GenSigSNA" "";
BA_DEF_DEF_ "SystemSignalLongSymbol" "";
BA_DEF_DEF_ "Confidence" "layout-only";
BA_ "GenMsgCycleTime" BO_ 537 100;
BA_ "GenMsgSendType" BO_ 537 0;
BA_ "GenMsgCycleTime" BO_ 602 1000;
BA_ "GenMsgSendType" BO_ 602 0;
BA_ "GenMsgCycleTime" BO_ 570 1000;
BA_ "GenMsgSendType" BO_ 570 0;
BA_ "GenMsgCycleTime" BO_ 1067 100;
BA_ "GenMsgSendType" BO_ 1067 0;
BA_ "GenMsgCycleTime" BO_ 761 100;
BA_ "GenMsgSendType" BO_ 761 0;
BA_ "Confidence" SG_ 537 VCSEC_TPMSDataIndex 0;
BA_ "Confidence" SG_ 537 VCSEC_TPMSCapabilityPressureInAd 0;
BA_ "SystemSignalLongSymbol" SG_ 537 VCSEC_TPMSCapabilityPressureInAd "VCSEC_TPMSCapabilityPressureInAdv0";
BA_ "Confidence" SG_ 537 VCSEC_TPMSCapabilityConfigurable 0;
BA_ "SystemSignalLongSymbol" SG_ 537 VCSEC_TPMSCapabilityConfigurable "VCSEC_TPMSCapabilityConfigurablePressure0";
BA_ "Confidence" SG_ 537 VCSEC_TPMSPressureRateOfChange0 0;
BA_ "Confidence" SG_ 537 VCSEC_TPMSPressure0 0;
BA_ "GenSigSNA" SG_ 537 VCSEC_TPMSPressure0 "511";
BA_ "Confidence" SG_ 537 VCSEC_TPMSTemperature0 0;
BA_ "GenSigSNA" SG_ 537 VCSEC_TPMSTemperature0 "255";
BA_ "Confidence" SG_ 537 VCSEC_TPMSBatVoltage0 0;
BA_ "GenSigSNA" SG_ 537 VCSEC_TPMSBatVoltage0 "255";
BA_ "Confidence" SG_ 537 VCSEC_TPMSLocation0 0;
BA_ "Confidence" SG_ 537 VCSEC_TPMSTemperatureCompensated 0;
BA_ "GenSigSNA" SG_ 537 VCSEC_TPMSTemperatureCompensated "511";
BA_ "SystemSignalLongSymbol" SG_ 537 VCSEC_TPMSTemperatureCompensated "VCSEC_TPMSTemperatureCompensatedPressure0";
BA_ "Confidence" SG_ 537 VCSEC_TPMSCapabilityPressur_0001 0;
BA_ "SystemSignalLongSymbol" SG_ 537 VCSEC_TPMSCapabilityPressur_0001 "VCSEC_TPMSCapabilityPressureInAdv1";
BA_ "Confidence" SG_ 537 VCSEC_TPMSCapabilityConfigu_0001 0;
BA_ "SystemSignalLongSymbol" SG_ 537 VCSEC_TPMSCapabilityConfigu_0001 "VCSEC_TPMSCapabilityConfigurablePressure1";
BA_ "Confidence" SG_ 537 VCSEC_TPMSPressureRateOfChange1 0;
BA_ "Confidence" SG_ 537 VCSEC_TPMSPressure1 0;
BA_ "GenSigSNA" SG_ 537 VCSEC_TPMSPressure1 "511";
BA_ "Confidence" SG_ 537 VCSEC_TPMSTemperature1 0;
BA_ "GenSigSNA" SG_ 537 VCSEC_TPMSTemperature1 "255";
BA_ "Confidence" SG_ 537 VCSEC_TPMSBatVoltage1 0;
BA_ "GenSigSNA" SG_ 537 VCSEC_TPMSBatVoltage1 "255";
BA_ "Confidence" SG_ 537 VCSEC_TPMSLocation1 0;
BA_ "Confidence" SG_ 537 VCSEC_TPMSTemperatureCompen_0001 0;
BA_ "GenSigSNA" SG_ 537 VCSEC_TPMSTemperatureCompen_0001 "511";
BA_ "SystemSignalLongSymbol" SG_ 537 VCSEC_TPMSTemperatureCompen_0001 "VCSEC_TPMSTemperatureCompensatedPressure1";
BA_ "Confidence" SG_ 537 VCSEC_TPMSCapabilityPressur_0002 0;
BA_ "SystemSignalLongSymbol" SG_ 537 VCSEC_TPMSCapabilityPressur_0002 "VCSEC_TPMSCapabilityPressureInAdv2";
BA_ "Confidence" SG_ 537 VCSEC_TPMSCapabilityConfigu_0002 0;
BA_ "SystemSignalLongSymbol" SG_ 537 VCSEC_TPMSCapabilityConfigu_0002 "VCSEC_TPMSCapabilityConfigurablePressure2";
BA_ "Confidence" SG_ 537 VCSEC_TPMSPressureRateOfChange2 0;
BA_ "Confidence" SG_ 537 VCSEC_TPMSPressure2 0;
BA_ "GenSigSNA" SG_ 537 VCSEC_TPMSPressure2 "511";
BA_ "Confidence" SG_ 537 VCSEC_TPMSTemperature2 0;
BA_ "GenSigSNA" SG_ 537 VCSEC_TPMSTemperature2 "255";
BA_ "Confidence" SG_ 537 VCSEC_TPMSBatVoltage2 0;
BA_ "GenSigSNA" SG_ 537 VCSEC_TPMSBatVoltage2 "255";
BA_ "Confidence" SG_ 537 VCSEC_TPMSLocation2 0;
BA_ "Confidence" SG_ 537 VCSEC_TPMSTemperatureCompen_0002 0;
BA_ "GenSigSNA" SG_ 537 VCSEC_TPMSTemperatureCompen_0002 "511";
BA_ "SystemSignalLongSymbol" SG_ 537 VCSEC_TPMSTemperatureCompen_0002 "VCSEC_TPMSTemperatureCompensatedPressure2";
BA_ "Confidence" SG_ 537 VCSEC_TPMSCapabilityPressur_0003 0;
BA_ "SystemSignalLongSymbol" SG_ 537 VCSEC_TPMSCapabilityPressur_0003 "VCSEC_TPMSCapabilityPressureInAdv3";
BA_ "Confidence" SG_ 537 VCSEC_TPMSCapabilityConfigu_0003 0;
BA_ "SystemSignalLongSymbol" SG_ 537 VCSEC_TPMSCapabilityConfigu_0003 "VCSEC_TPMSCapabilityConfigurablePressure3";
BA_ "Confidence" SG_ 537 VCSEC_TPMSPressureRateOfChange3 0;
BA_ "Confidence" SG_ 537 VCSEC_TPMSPressure3 0;
BA_ "GenSigSNA" SG_ 537 VCSEC_TPMSPressure3 "511";
BA_ "Confidence" SG_ 537 VCSEC_TPMSTemperature3 0;
BA_ "GenSigSNA" SG_ 537 VCSEC_TPMSTemperature3 "255";
BA_ "Confidence" SG_ 537 VCSEC_TPMSBatVoltage3 0;
BA_ "GenSigSNA" SG_ 537 VCSEC_TPMSBatVoltage3 "255";
BA_ "Confidence" SG_ 537 VCSEC_TPMSLocation3 0;
BA_ "Confidence" SG_ 537 VCSEC_TPMSTemperatureCompen_0003 0;
BA_ "GenSigSNA" SG_ 537 VCSEC_TPMSTemperatureCompen_0003 "511";
BA_ "SystemSignalLongSymbol" SG_ 537 VCSEC_TPMSTemperatureCompen_0003 "VCSEC_TPMSTemperatureCompensatedPressure3";
BA_ "Confidence" SG_ 537 VCSEC_TPMSRecommendedColdPressur 0;
BA_ "GenSigSNA" SG_ 537 VCSEC_TPMSRecommendedColdPressur "255";
BA_ "SystemSignalLongSymbol" SG_ 537 VCSEC_TPMSRecommendedColdPressur "VCSEC_TPMSRecommendedColdPressureFront";
BA_ "Confidence" SG_ 537 VCSEC_TPMSRecommendedColdPr_0001 0;
BA_ "GenSigSNA" SG_ 537 VCSEC_TPMSRecommendedColdPr_0001 "255";
BA_ "SystemSignalLongSymbol" SG_ 537 VCSEC_TPMSRecommendedColdPr_0001 "VCSEC_TPMSRecommendedColdPressureRear";
BA_ "Confidence" SG_ 537 VCSEC_TPMSFeature0 0;
BA_ "Confidence" SG_ 537 VCSEC_TPMSFeature1 0;
BA_ "Confidence" SG_ 537 VCSEC_TPMSFeature0Count 0;
BA_ "Confidence" SG_ 537 VCSEC_TPMSFeature0TimeS 0;
BA_ "Confidence" SG_ 537 VCSEC_TPMSAutonomyStatus 0;
BA_ "Confidence" SG_ 537 VCSEC_TPMSAutonomyStatusMIATimeS 0;
BA_ "Confidence" SG_ 537 VCSEC_TPMSLastKnownPressureFL 0;
BA_ "GenSigSNA" SG_ 537 VCSEC_TPMSLastKnownPressureFL "255";
BA_ "Confidence" SG_ 537 VCSEC_TPMSLastKnownPressureFR 0;
BA_ "GenSigSNA" SG_ 537 VCSEC_TPMSLastKnownPressureFR "255";
BA_ "Confidence" SG_ 537 VCSEC_TPMSLastKnownPressureRL 0;
BA_ "GenSigSNA" SG_ 537 VCSEC_TPMSLastKnownPressureRL "255";
BA_ "Confidence" SG_ 537 VCSEC_TPMSLastKnownPressureRR 0;
BA_ "GenSigSNA" SG_ 537 VCSEC_TPMSLastKnownPressureRR "255";
BA_ "Confidence" SG_ 602 VCSEC_TPMSDisplayPressureFL 0;
BA_ "GenSigSNA" SG_ 602 VCSEC_TPMSDisplayPressureFL "255";
BA_ "Confidence" SG_ 602 VCSEC_TPMSDisplayPressureFR 0;
BA_ "GenSigSNA" SG_ 602 VCSEC_TPMSDisplayPressureFR "255";
BA_ "Confidence" SG_ 602 VCSEC_TPMSDisplayPressureRL 0;
BA_ "GenSigSNA" SG_ 602 VCSEC_TPMSDisplayPressureRL "255";
BA_ "Confidence" SG_ 602 VCSEC_TPMSDisplayPressureRR 0;
BA_ "GenSigSNA" SG_ 602 VCSEC_TPMSDisplayPressureRR "255";
BA_ "Confidence" SG_ 602 VCSEC_TPMSTellTale 0;
BA_ "Confidence" SG_ 602 VCSEC_TPMSDisplaySoftWarningIndi 0;
BA_ "SystemSignalLongSymbol" SG_ 602 VCSEC_TPMSDisplaySoftWarningIndi "VCSEC_TPMSDisplaySoftWarningIndicationFL";
BA_ "Confidence" SG_ 602 VCSEC_TPMSDisplaySoftWarnin_0001 0;
BA_ "SystemSignalLongSymbol" SG_ 602 VCSEC_TPMSDisplaySoftWarnin_0001 "VCSEC_TPMSDisplaySoftWarningIndicationFR";
BA_ "Confidence" SG_ 602 VCSEC_TPMSDisplaySoftWarnin_0002 0;
BA_ "SystemSignalLongSymbol" SG_ 602 VCSEC_TPMSDisplaySoftWarnin_0002 "VCSEC_TPMSDisplaySoftWarningIndicationRL";
BA_ "Confidence" SG_ 602 VCSEC_TPMSDisplaySoftWarnin_0003 0;
BA_ "SystemSignalLongSymbol" SG_ 602 VCSEC_TPMSDisplaySoftWarnin_0003 "VCSEC_TPMSDisplaySoftWarningIndicationRR";
BA_ "Confidence" SG_ 602 VCSEC_TPMSDisplayHardWarningIndi 0;
BA_ "SystemSignalLongSymbol" SG_ 602 VCSEC_TPMSDisplayHardWarningIndi "VCSEC_TPMSDisplayHardWarningIndicationFL";
BA_ "Confidence" SG_ 602 VCSEC_TPMSDisplayHardWarnin_0001 0;
BA_ "SystemSignalLongSymbol" SG_ 602 VCSEC_TPMSDisplayHardWarnin_0001 "VCSEC_TPMSDisplayHardWarningIndicationFR";
BA_ "Confidence" SG_ 602 VCSEC_TPMSDisplayHardWarnin_0002 0;
BA_ "SystemSignalLongSymbol" SG_ 602 VCSEC_TPMSDisplayHardWarnin_0002 "VCSEC_TPMSDisplayHardWarningIndicationRL";
BA_ "Confidence" SG_ 602 VCSEC_TPMSDisplayHardWarnin_0003 0;
BA_ "SystemSignalLongSymbol" SG_ 602 VCSEC_TPMSDisplayHardWarnin_0003 "VCSEC_TPMSDisplayHardWarningIndicationRR";
BA_ "Confidence" SG_ 570 VCSEC_TPMSStatusIndex 0;
BA_ "Confidence" SG_ 570 VCSEC_TPMSSystemState 0;
BA_ "Confidence" SG_ 570 VCSEC_TPMSSensorMACAddress0 0;
BA_ "Confidence" SG_ 570 VCSEC_TPMSSensorMACAddress1 0;
BA_ "Confidence" SG_ 570 VCSEC_TPMSSensorMACAddress2 0;
BA_ "Confidence" SG_ 570 VCSEC_TPMSSensorMACAddress3 0;
BA_ "Confidence" SG_ 570 VCSEC_BLEUnsuccessfulConnEventRa 0;
BA_ "GenSigSNA" SG_ 570 VCSEC_BLEUnsuccessfulConnEventRa "1023";
BA_ "SystemSignalLongSymbol" SG_ 570 VCSEC_BLEUnsuccessfulConnEventRa "VCSEC_BLEUnsuccessfulConnEventRate0";
BA_ "Confidence" SG_ 570 VCSEC_BLEUnsuccessfulConnEv_0001 0;
BA_ "GenSigSNA" SG_ 570 VCSEC_BLEUnsuccessfulConnEv_0001 "1023";
BA_ "SystemSignalLongSymbol" SG_ 570 VCSEC_BLEUnsuccessfulConnEv_0001 "VCSEC_BLEUnsuccessfulConnEventRate1";
BA_ "Confidence" SG_ 570 VCSEC_BLEUnsuccessfulConnEv_0002 0;
BA_ "GenSigSNA" SG_ 570 VCSEC_BLEUnsuccessfulConnEv_0002 "1023";
BA_ "SystemSignalLongSymbol" SG_ 570 VCSEC_BLEUnsuccessfulConnEv_0002 "VCSEC_BLEUnsuccessfulConnEventRate2";
BA_ "Confidence" SG_ 570 VCSEC_BLEUnsuccessfulConnEv_0003 0;
BA_ "GenSigSNA" SG_ 570 VCSEC_BLEUnsuccessfulConnEv_0003 "1023";
BA_ "SystemSignalLongSymbol" SG_ 570 VCSEC_BLEUnsuccessfulConnEv_0003 "VCSEC_BLEUnsuccessfulConnEventRate3";
BA_ "Confidence" SG_ 570 VCSEC_TPMSSensorTIAppCRC0 0;
BA_ "GenSigSNA" SG_ 570 VCSEC_TPMSSensorTIAppCRC0 "0";
BA_ "Confidence" SG_ 570 VCSEC_TPMSSensorMLXAppCRC0 0;
BA_ "GenSigSNA" SG_ 570 VCSEC_TPMSSensorMLXAppCRC0 "0";
BA_ "Confidence" SG_ 570 VCSEC_TPMSSensorTIAppCRC1 0;
BA_ "GenSigSNA" SG_ 570 VCSEC_TPMSSensorTIAppCRC1 "0";
BA_ "Confidence" SG_ 570 VCSEC_TPMSSensorMLXAppCRC1 0;
BA_ "GenSigSNA" SG_ 570 VCSEC_TPMSSensorMLXAppCRC1 "0";
BA_ "Confidence" SG_ 570 VCSEC_TPMSSensorTIAppCRC2 0;
BA_ "GenSigSNA" SG_ 570 VCSEC_TPMSSensorTIAppCRC2 "0";
BA_ "Confidence" SG_ 570 VCSEC_TPMSSensorMLXAppCRC2 0;
BA_ "GenSigSNA" SG_ 570 VCSEC_TPMSSensorMLXAppCRC2 "0";
BA_ "Confidence" SG_ 570 VCSEC_TPMSSensorTIAppCRC3 0;
BA_ "GenSigSNA" SG_ 570 VCSEC_TPMSSensorTIAppCRC3 "0";
BA_ "Confidence" SG_ 570 VCSEC_TPMSSensorMLXAppCRC3 0;
BA_ "GenSigSNA" SG_ 570 VCSEC_TPMSSensorMLXAppCRC3 "0";
BA_ "Confidence" SG_ 570 VCSEC_TPMStotalAwakeTime0 0;
BA_ "Confidence" SG_ 570 VCSEC_TPMSTrimAdjusted0 0;
BA_ "Confidence" SG_ 570 VCSEC_TPMSGenealogySensorState0 0;
BA_ "Confidence" SG_ 570 VCSEC_TPMSSensorType0 0;
BA_ "Confidence" SG_ 570 VCSEC_TPMStotalAwakeTime1 0;
BA_ "Confidence" SG_ 570 VCSEC_TPMSTrimAdjusted1 0;
BA_ "Confidence" SG_ 570 VCSEC_TPMSGenealogySensorState1 0;
BA_ "Confidence" SG_ 570 VCSEC_TPMSSensorType1 0;
BA_ "Confidence" SG_ 570 VCSEC_TPMStotalAwakeTime2 0;
BA_ "Confidence" SG_ 570 VCSEC_TPMSTrimAdjusted2 0;
BA_ "Confidence" SG_ 570 VCSEC_TPMSGenealogySensorState2 0;
BA_ "Confidence" SG_ 570 VCSEC_TPMSSensorType2 0;
BA_ "Confidence" SG_ 570 VCSEC_TPMStotalAwakeTime3 0;
BA_ "Confidence" SG_ 570 VCSEC_TPMSTrimAdjusted3 0;
BA_ "Confidence" SG_ 570 VCSEC_TPMSGenealogySensorState3 0;
BA_ "Confidence" SG_ 570 VCSEC_TPMSSensorType3 0;
BA_ "Confidence" SG_ 570 VCSEC_TPMSSensor0Hash 0;
BA_ "Confidence" SG_ 570 VCSEC_TPMSSensor1Hash 0;
BA_ "Confidence" SG_ 570 VCSEC_TPMSSensor2Hash 0;
BA_ "Confidence" SG_ 570 VCSEC_TPMSSensor3Hash 0;
BA_ "Confidence" SG_ 570 VCSEC_TPMSLastLocationSensor0 0;
BA_ "Confidence" SG_ 570 VCSEC_TPMSLastLocationSensor1 0;
BA_ "Confidence" SG_ 570 VCSEC_TPMSLastLocationSensor2 0;
BA_ "Confidence" SG_ 570 VCSEC_TPMSLastLocationSensor3 0;
BA_ "Confidence" SG_ 570 VCSEC_TPMSTemperatureCompensated 0;
BA_ "GenSigSNA" SG_ 570 VCSEC_TPMSTemperatureCompensated "255";
BA_ "SystemSignalLongSymbol" SG_ 570 VCSEC_TPMSTemperatureCompensated "VCSEC_TPMSTemperatureCompensatedBatVoltage0";
BA_ "Confidence" SG_ 570 VCSEC_TPMSTemperatureCompen_0001 0;
BA_ "GenSigSNA" SG_ 570 VCSEC_TPMSTemperatureCompen_0001 "255";
BA_ "SystemSignalLongSymbol" SG_ 570 VCSEC_TPMSTemperatureCompen_0001 "VCSEC_TPMSTemperatureCompensatedBatVoltage1";
BA_ "Confidence" SG_ 570 VCSEC_TPMSTemperatureCompen_0002 0;
BA_ "GenSigSNA" SG_ 570 VCSEC_TPMSTemperatureCompen_0002 "255";
BA_ "SystemSignalLongSymbol" SG_ 570 VCSEC_TPMSTemperatureCompen_0002 "VCSEC_TPMSTemperatureCompensatedBatVoltage2";
BA_ "Confidence" SG_ 570 VCSEC_TPMSTemperatureCompen_0003 0;
BA_ "GenSigSNA" SG_ 570 VCSEC_TPMSTemperatureCompen_0003 "255";
BA_ "SystemSignalLongSymbol" SG_ 570 VCSEC_TPMSTemperatureCompen_0003 "VCSEC_TPMSTemperatureCompensatedBatVoltage3";
BA_ "Confidence" SG_ 570 VCSEC_TPMSFilteredBatVoltage0 0;
BA_ "GenSigSNA" SG_ 570 VCSEC_TPMSFilteredBatVoltage0 "255";
BA_ "Confidence" SG_ 570 VCSEC_TPMSFilteredBatVoltage2 0;
BA_ "GenSigSNA" SG_ 570 VCSEC_TPMSFilteredBatVoltage2 "255";
BA_ "Confidence" SG_ 570 VCSEC_TPMSFilteredBatVoltage1 0;
BA_ "GenSigSNA" SG_ 570 VCSEC_TPMSFilteredBatVoltage1 "255";
BA_ "Confidence" SG_ 570 VCSEC_TPMSFilteredBatVoltage3 0;
BA_ "GenSigSNA" SG_ 570 VCSEC_TPMSFilteredBatVoltage3 "255";
BA_ "Confidence" SG_ 1067 VCSEC_UWBEndpointIndex 1;
BA_ "Confidence" SG_ 1067 VCSEC_UWBExpectedEndpointsActive 0;
BA_ "SystemSignalLongSymbol" SG_ 1067 VCSEC_UWBExpectedEndpointsActive "VCSEC_UWBExpectedEndpointsActive0";
BA_ "Confidence" SG_ 1067 VCSEC_UWBExpectedEndpointsA_0001 0;
BA_ "SystemSignalLongSymbol" SG_ 1067 VCSEC_UWBExpectedEndpointsA_0001 "VCSEC_UWBExpectedEndpointsActive1";
BA_ "Confidence" SG_ 1067 VCSEC_UWBExpectedEndpointsA_0002 0;
BA_ "SystemSignalLongSymbol" SG_ 1067 VCSEC_UWBExpectedEndpointsA_0002 "VCSEC_UWBExpectedEndpointsActive2";
BA_ "Confidence" SG_ 1067 VCSEC_UWBExpectedEndpointsA_0003 0;
BA_ "SystemSignalLongSymbol" SG_ 1067 VCSEC_UWBExpectedEndpointsA_0003 "VCSEC_UWBExpectedEndpointsActive3";
BA_ "Confidence" SG_ 1067 VCSEC_UWBRearRightDistance0 0;
BA_ "GenSigSNA" SG_ 1067 VCSEC_UWBRearRightDistance0 "4095";
BA_ "Confidence" SG_ 1067 VCSEC_UWBRearRightDistance1 0;
BA_ "GenSigSNA" SG_ 1067 VCSEC_UWBRearRightDistance1 "4095";
BA_ "Confidence" SG_ 1067 VCSEC_UWBRearRightDistance2 0;
BA_ "GenSigSNA" SG_ 1067 VCSEC_UWBRearRightDistance2 "4095";
BA_ "Confidence" SG_ 1067 VCSEC_UWBLeftDistance3 0;
BA_ "GenSigSNA" SG_ 1067 VCSEC_UWBLeftDistance3 "4095";
BA_ "Confidence" SG_ 1067 VCSEC_UWBRightDistance3 0;
BA_ "GenSigSNA" SG_ 1067 VCSEC_UWBRightDistance3 "4095";
BA_ "Confidence" SG_ 1067 VCSEC_UWBRearRightDistance3 0;
BA_ "GenSigSNA" SG_ 1067 VCSEC_UWBRearRightDistance3 "4095";
BA_ "Confidence" SG_ 1067 VCSEC_UWBRearLeftDistance3 0;
BA_ "GenSigSNA" SG_ 1067 VCSEC_UWBRearLeftDistance3 "4095";
BA_ "Confidence" SG_ 1067 VCSEC_UWBCenterDistance3 0;
BA_ "GenSigSNA" SG_ 1067 VCSEC_UWBCenterDistance3 "4095";
BA_ "Confidence" SG_ 1067 VCSEC_UWBLeftDistance2 0;
BA_ "GenSigSNA" SG_ 1067 VCSEC_UWBLeftDistance2 "4095";
BA_ "Confidence" SG_ 1067 VCSEC_UWBRightDistance2 0;
BA_ "GenSigSNA" SG_ 1067 VCSEC_UWBRightDistance2 "4095";
BA_ "Confidence" SG_ 1067 VCSEC_UWBRearDistance2 0;
BA_ "GenSigSNA" SG_ 1067 VCSEC_UWBRearDistance2 "4095";
BA_ "Confidence" SG_ 1067 VCSEC_UWBRearLeftDistance2 0;
BA_ "GenSigSNA" SG_ 1067 VCSEC_UWBRearLeftDistance2 "4095";
BA_ "Confidence" SG_ 1067 VCSEC_UWBCenterDistance2 0;
BA_ "GenSigSNA" SG_ 1067 VCSEC_UWBCenterDistance2 "4095";
BA_ "Confidence" SG_ 1067 VCSEC_UWBLeftDistance1 0;
BA_ "GenSigSNA" SG_ 1067 VCSEC_UWBLeftDistance1 "4095";
BA_ "Confidence" SG_ 1067 VCSEC_UWBRightDistance1 0;
BA_ "GenSigSNA" SG_ 1067 VCSEC_UWBRightDistance1 "4095";
BA_ "Confidence" SG_ 1067 VCSEC_UWBRearDistance1 0;
BA_ "GenSigSNA" SG_ 1067 VCSEC_UWBRearDistance1 "4095";
BA_ "Confidence" SG_ 1067 VCSEC_UWBRearLeftDistance1 0;
BA_ "GenSigSNA" SG_ 1067 VCSEC_UWBRearLeftDistance1 "4095";
BA_ "Confidence" SG_ 1067 VCSEC_UWBCenterDistance1 0;
BA_ "GenSigSNA" SG_ 1067 VCSEC_UWBCenterDistance1 "4095";
BA_ "Confidence" SG_ 1067 VCSEC_UWBLeftDistance0 0;
BA_ "GenSigSNA" SG_ 1067 VCSEC_UWBLeftDistance0 "4095";
BA_ "Confidence" SG_ 1067 VCSEC_UWBRightDistance0 0;
BA_ "GenSigSNA" SG_ 1067 VCSEC_UWBRightDistance0 "4095";
BA_ "Confidence" SG_ 1067 VCSEC_UWBRearDistance0 0;
BA_ "GenSigSNA" SG_ 1067 VCSEC_UWBRearDistance0 "4095";
BA_ "Confidence" SG_ 1067 VCSEC_UWBRearLeftDistance0 0;
BA_ "GenSigSNA" SG_ 1067 VCSEC_UWBRearLeftDistance0 "4095";
BA_ "Confidence" SG_ 1067 VCSEC_UWBCenterDistance0 0;
BA_ "GenSigSNA" SG_ 1067 VCSEC_UWBCenterDistance0 "4095";
BA_ "Confidence" SG_ 761 VCSEC_activeKeyDebug 0;
BA_ "Confidence" SG_ 761 VCSEC_bleChannelDisconnected 0;
BA_ "Confidence" SG_ 761 VCSEC_bleDisconnectionReason 0;
BA_ "Confidence" SG_ 761 VCSEC_bleConnetionAttemptWLEntry 0;
BA_ "Confidence" SG_ 761 VCSEC_AdditionalAuthInfoIndex 1;
BA_ "Confidence" SG_ 761 VCSEC_activeKeyReason 0;
BA_ "Confidence" SG_ 761 VCSEC_activeKeySHA1 0;
BA_ "Confidence" SG_ 761 VCSEC_algoUsedForSummonRange0 0;
BA_ "Confidence" SG_ 761 VCSEC_keyWithinSummonRange0 0;
BA_ "Confidence" SG_ 761 VCSEC_algoUsedForSummonRange1 0;
BA_ "Confidence" SG_ 761 VCSEC_keyWithinSummonRange1 0;
BA_ "Confidence" SG_ 761 VCSEC_algoUsedForSummonRange2 0;
BA_ "Confidence" SG_ 761 VCSEC_keyWithinSummonRange2 0;
BA_ "Confidence" SG_ 761 VCSEC_BLEDeviceWithinSummonRange 0;
BA_ "Confidence" SG_ 761 VCSEC_algoUWBInteriorPresence 0;
BA_ "Confidence" SG_ 761 VCSEC_frunkOpenSuggestionRespons 0;
BA_ "SystemSignalLongSymbol" SG_ 761 VCSEC_frunkOpenSuggestionRespons "VCSEC_frunkOpenSuggestionResponse";
BA_ "Confidence" SG_ 761 VCSEC_NFCAuthFromBPillarFormFact 0;
BA_ "SystemSignalLongSymbol" SG_ 761 VCSEC_NFCAuthFromBPillarFormFact "VCSEC_NFCAuthFromBPillarFormFactor";
BA_ "Confidence" SG_ 761 VCSEC_NFCAuthFromCenterConsoleFo 0;
BA_ "SystemSignalLongSymbol" SG_ 761 VCSEC_NFCAuthFromCenterConsoleFo "VCSEC_NFCAuthFromCenterConsoleFormFactor";
BA_ "Confidence" SG_ 761 VCSEC_trunkOpenSuggestionRespons 0;
BA_ "SystemSignalLongSymbol" SG_ 761 VCSEC_trunkOpenSuggestionRespons "VCSEC_trunkOpenSuggestionResponse";
BA_ "Confidence" SG_ 761 VCSEC_algoTrunkSuggestionRaw 0;
BA_ "Confidence" SG_ 761 VCSEC_algoTrunkSuggestionProc 0;
BA_ "Confidence" SG_ 761 VCSEC_algoTrunkSuggestionRearmAl 0;
BA_ "SystemSignalLongSymbol" SG_ 761 VCSEC_algoTrunkSuggestionRearmAl "VCSEC_algoTrunkSuggestionRearmAllowed";
BA_ "Confidence" SG_ 761 VCSEC_algoFrunkSuggestionRaw 0;
BA_ "Confidence" SG_ 761 VCSEC_algoFrunkSuggestionProc 0;
BA_ "Confidence" SG_ 761 VCSEC_algoFrunkSuggestionRearmAl 0;
BA_ "SystemSignalLongSymbol" SG_ 761 VCSEC_algoFrunkSuggestionRearmAl "VCSEC_algoFrunkSuggestionRearmAllowed";
BA_ "Confidence" SG_ 1328 VCSEC_alertID 1;
BA_ "Confidence" SG_ 1328 VCSEC_alertState 1;
BA_ "Confidence" SG_ 1328 VCSEC_a059_voltageDrop 1;
BA_ "Confidence" SG_ 1328 VCSEC_a059_resistanceEstimate 1;
BA_ "Confidence" SG_ 1328 VCSEC_a059_current 1;
BA_ "Confidence" SG_ 1328 VCSEC_a063_ADCVoltage 1;
BA_ "SystemSignalLongSymbol" SG_ 1328 VCSEC_a101_LIPC_externalWatchdog "VCSEC_a101_LIPC_externalWatchdogHeartBeat";
BA_ "SystemSignalLongSymbol" SG_ 1328 VCSEC_a110_VEH_canLogAvailabilit "VCSEC_a110_VEH_canLogAvailability";
BA_ "SystemSignalLongSymbol" SG_ 1328 VCSEC_a115_UI_corianderVehicleCo "VCSEC_a115_UI_corianderVehicleControl";
BA_ "SystemSignalLongSymbol" SG_ 1328 VCSEC_a117_BDY_falconSwitchStatu "VCSEC_a117_BDY_falconSwitchStatus";
BA_ "SystemSignalLongSymbol" SG_ 1328 VCSEC_a117_VEH_intrusionSensorSt "VCSEC_a117_VEH_intrusionSensorStatus";
BA_ "SystemSignalLongSymbol" SG_ 1328 VCSEC_a117_PARTY_lightingSeconda "VCSEC_a117_PARTY_lightingSecondary";
BA_ "SystemSignalLongSymbol" SG_ 1328 VCSEC_a118_PARTY_outputPowerStat "VCSEC_a118_PARTY_outputPowerStatus";
BA_ "SystemSignalLongSymbol" SG_ 1328 VCSEC_a118_VEH_interNodeResistan "VCSEC_a118_VEH_interNodeResistance";
BA_ "SystemSignalLongSymbol" SG_ 1328 VCSEC_a118_PARTY_AP_vehicleState "VCSEC_a118_PARTY_AP_vehicleState1HzMuxed";
BA_ "SystemSignalLongSymbol" SG_ 1328 VCSEC_a118_BDY_AP_vehicleState1H "VCSEC_a118_BDY_AP_vehicleState1HzMuxed";
BA_ "SystemSignalLongSymbol" SG_ 1328 VCSEC_a118_PARTY_VCFRONT_cameraC "VCSEC_a118_PARTY_VCFRONT_cameraCleaningStatus";
BA_ "SystemSignalLongSymbol" SG_ 1328 VCSEC_a120_PARTY_vehicleEstimate "VCSEC_a120_PARTY_vehicleEstimates";
BA_ "SystemSignalLongSymbol" SG_ 1328 VCSEC_a120_VEH_aggregatedAxleSpe "VCSEC_a120_VEH_aggregatedAxleSpeed";
BA_ "SystemSignalLongSymbol" SG_ 1328 VCSEC_a120_PARTY_aggregatedAxleS "VCSEC_a120_PARTY_aggregatedAxleSpeed";
BA_ "SystemSignalLongSymbol" SG_ 1328 VCSEC_a120_PARTY_stalklessInterf "VCSEC_a120_PARTY_stalklessInterfaces";
BA_ "SystemSignalLongSymbol" SG_ 1328 VCSEC_a120_VEH_estimatedBrakeTem "VCSEC_a120_VEH_estimatedBrakeTemp";
BA_ "Confidence" SG_ 1328 VCSEC_a133_alarmTriggerReason 1;
BA_ "SystemSignalLongSymbol" SG_ 1328 VCSEC_a140_cardRmvdB4AuthComplet "VCSEC_a140_cardRmvdB4AuthComplete";
BA_ "SystemSignalLongSymbol" SG_ 1328 VCSEC_a140_cardRmvdB4SndingChaln "VCSEC_a140_cardRmvdB4SndingChalng";
BA_ "Confidence" SG_ 1328 VCSEC_a177_keyRole 1;
BA_ "Confidence" SG_ 1328 VCSEC_a178_removedKeyRole 1;
BA_ "Confidence" SG_ 1328 VCSEC_a211_handlePulled 1;
BA_ "Confidence" SG_ 1328 VCSEC_a211_MaximumRSSIAntenna 1;
BA_ "Confidence" SG_ 1328 VCSEC_a221_homologationRegion 1;
BA_ "Confidence" SG_ 1328 VCSEC_a256_whitelistOperation 1;
BA_ "Confidence" SG_ 1328 VCSEC_a256_failureReason 1;
BA_ "Confidence" SG_ 1328 VCSEC_a266_pressure 1;
BA_ "Confidence" SG_ 1328 VCSEC_a267_pressure 1;
BA_ "Confidence" SG_ 1328 VCSEC_a268_pressure 1;
BA_ "Confidence" SG_ 1328 VCSEC_a269_pressure 1;
BA_ "Confidence" SG_ 1328 VCSEC_a270_pressure 1;
BA_ "Confidence" SG_ 1328 VCSEC_a271_pressure 1;
BA_ "Confidence" SG_ 1328 VCSEC_a272_pressure 1;
BA_ "Confidence" SG_ 1328 VCSEC_a273_pressure 1;
BA_ "Confidence" SG_ 1328 VCSEC_a455_pressure 1;
BA_ "Confidence" SG_ 1328 VCSEC_a456_pressure 1;
BA_ "Confidence" SG_ 1328 VCSEC_a457_pressure 1;
BA_ "Confidence" SG_ 1328 VCSEC_a458_pressure 1;
BA_ "SystemSignalLongSymbol" SG_ 1328 VCSEC_a497_centerEndpointMismatc "VCSEC_a497_centerEndpointMismatch";
BA_ "SystemSignalLongSymbol" SG_ 1328 VCSEC_a497_cradleEndpointMismatc "VCSEC_a497_cradleEndpointMismatch";
BA_ "SystemSignalLongSymbol" SG_ 1328 VCSEC_a497_rearLeftEndpointMisma "VCSEC_a497_rearLeftEndpointMismatch";
BA_ "SystemSignalLongSymbol" SG_ 1328 VCSEC_a497_rearRightEndpointMism "VCSEC_a497_rearRightEndpointMismatch";
BA_ "Confidence" SG_ 1328 VCSEC_a497_endpointLocationToFix 1;
BA_ "SystemSignalLongSymbol" SG_ 1328 VCSEC_a497_endpointExpectedPcbaI "VCSEC_a497_endpointExpectedPcbaId";
BA_ "SystemSignalLongSymbol" SG_ 1328 VCSEC_a497_endpointExpectedAssem "VCSEC_a497_endpointExpectedAssemblyId";
BA_ "SystemSignalLongSymbol" SG_ 1328 VCSEC_a497_endpointExpectedUsage "VCSEC_a497_endpointExpectedUsageId";
BA_ "SystemSignalLongSymbol" SG_ 1328 VCSEC_a497_endpointActualAssembl "VCSEC_a497_endpointActualAssemblyId";
BA_ "Confidence" SG_ 1328 VCSEC_a517_pressure 1;
BA_ "Confidence" SG_ 1328 VCSEC_a518_pressure 1;
BA_ "Confidence" SG_ 1328 VCSEC_a519_pressure 1;
BA_ "Confidence" SG_ 1328 VCSEC_a520_pressure 1;
VAL_ 537 VCSEC_TPMSDataIndex 5 "AutonomyHealth" 4 "RCP" 3 "Sensor3" 2 "Sensor2" 1 "Sensor1" 0 "Sensor0" ;
VAL_ 537 VCSEC_TPMSPressure0 511 "SNA" 510 "OVER_RANGE" ;
VAL_ 537 VCSEC_TPMSTemperature0 255 "SNA" ;
VAL_ 537 VCSEC_TPMSBatVoltage0 255 "SNA" ;
VAL_ 537 VCSEC_TPMSLocation0 4 "LOCATION_UNKNOWN" 3 "LOCATION_RR" 2 "LOCATION_RL" 1 "LOCATION_FR" 0 "LOCATION_FL" ;
VAL_ 537 VCSEC_TPMSTemperatureCompensated 511 "SNA" 510 "OVER_RANGE" ;
VAL_ 537 VCSEC_TPMSPressure1 511 "SNA" 510 "OVER_RANGE" ;
VAL_ 537 VCSEC_TPMSTemperature1 255 "SNA" ;
VAL_ 537 VCSEC_TPMSBatVoltage1 255 "SNA" ;
VAL_ 537 VCSEC_TPMSLocation1 4 "LOCATION_UNKNOWN" 3 "LOCATION_RR" 2 "LOCATION_RL" 1 "LOCATION_FR" 0 "LOCATION_FL" ;
VAL_ 537 VCSEC_TPMSTemperatureCompen_0001 511 "SNA" 510 "OVER_RANGE" ;
VAL_ 537 VCSEC_TPMSPressure2 511 "SNA" 510 "OVER_RANGE" ;
VAL_ 537 VCSEC_TPMSTemperature2 255 "SNA" ;
VAL_ 537 VCSEC_TPMSBatVoltage2 255 "SNA" ;
VAL_ 537 VCSEC_TPMSLocation2 4 "LOCATION_UNKNOWN" 3 "LOCATION_RR" 2 "LOCATION_RL" 1 "LOCATION_FR" 0 "LOCATION_FL" ;
VAL_ 537 VCSEC_TPMSTemperatureCompen_0002 511 "SNA" 510 "OVER_RANGE" ;
VAL_ 537 VCSEC_TPMSPressure3 511 "SNA" 510 "OVER_RANGE" ;
VAL_ 537 VCSEC_TPMSTemperature3 255 "SNA" ;
VAL_ 537 VCSEC_TPMSBatVoltage3 255 "SNA" ;
VAL_ 537 VCSEC_TPMSLocation3 4 "LOCATION_UNKNOWN" 3 "LOCATION_RR" 2 "LOCATION_RL" 1 "LOCATION_FR" 0 "LOCATION_FL" ;
VAL_ 537 VCSEC_TPMSTemperatureCompen_0003 511 "SNA" 510 "OVER_RANGE" ;
VAL_ 537 VCSEC_TPMSRecommendedColdPressur 255 "SNA" 254 "OVER_RANGE" ;
VAL_ 537 VCSEC_TPMSRecommendedColdPr_0001 255 "SNA" 254 "OVER_RANGE" ;
VAL_ 537 VCSEC_TPMSFeature0 6 "FEATURE_0_BLOCKED" 5 "FEATURE_0_ACTIVE" 4 "FEATURE_0_READY" 3 "FEATURE_0_WAIT_FOR_STATIONARY" 2 "FEATURE_0_UNAVAILABLE_2" 1 "FEATURE_0_UNAVAILABLE_1" 0 "FEATURE_0_NOT_SUPPORTED" ;
VAL_ 537 VCSEC_TPMSFeature1 5 "FEATURE_1_CLOSE" 4 "FEATURE_1_MEDIUM" 3 "FEATURE_1_FAR_AWAY" 2 "FEATURE_1_INCORRECT" 1 "FEATURE_1_REACHED" 0 "FEATURE_1_NONE" ;
VAL_ 537 VCSEC_TPMSAutonomyStatus 2 "TPMS_AUTONOMY_STATUS_RESET" 1 "TPMS_AUTONOMY_STATUS_MIA" 0 "TPMS_AUTONOMY_STATUS_NORMAL" ;
VAL_ 537 VCSEC_TPMSLastKnownPressureFL 255 "SNA" 254 "OVER_RANGE" ;
VAL_ 537 VCSEC_TPMSLastKnownPressureFR 255 "SNA" 254 "OVER_RANGE" ;
VAL_ 537 VCSEC_TPMSLastKnownPressureRL 255 "SNA" 254 "OVER_RANGE" ;
VAL_ 537 VCSEC_TPMSLastKnownPressureRR 255 "SNA" 254 "OVER_RANGE" ;
VAL_ 602 VCSEC_TPMSDisplayPressureFL 255 "SNA" 254 "OVER_RANGE" ;
VAL_ 602 VCSEC_TPMSDisplayPressureFR 255 "SNA" 254 "OVER_RANGE" ;
VAL_ 602 VCSEC_TPMSDisplayPressureRL 255 "SNA" 254 "OVER_RANGE" ;
VAL_ 602 VCSEC_TPMSDisplayPressureRR 255 "SNA" 254 "OVER_RANGE" ;
VAL_ 602 VCSEC_TPMSTellTale 2 "TPMS_TELLTALE_FLASHING" 1 "TPMS_TELLTALE_SOLID" 0 "TPMS_TELLTALE_OFF" ;
VAL_ 602 VCSEC_TPMSDisplaySoftWarningIndi 1 "TPMS_PRESSUREWARNING_INDICATED" 0 "TPMS_PRESSUREWARNING_NOT_INDICATED" ;
VAL_ 602 VCSEC_TPMSDisplaySoftWarnin_0001 1 "TPMS_PRESSUREWARNING_INDICATED" 0 "TPMS_PRESSUREWARNING_NOT_INDICATED" ;
VAL_ 602 VCSEC_TPMSDisplaySoftWarnin_0002 1 "TPMS_PRESSUREWARNING_INDICATED" 0 "TPMS_PRESSUREWARNING_NOT_INDICATED" ;
VAL_ 602 VCSEC_TPMSDisplaySoftWarnin_0003 1 "TPMS_PRESSUREWARNING_INDICATED" 0 "TPMS_PRESSUREWARNING_NOT_INDICATED" ;
VAL_ 602 VCSEC_TPMSDisplayHardWarningIndi 1 "TPMS_PRESSUREWARNING_INDICATED" 0 "TPMS_PRESSUREWARNING_NOT_INDICATED" ;
VAL_ 602 VCSEC_TPMSDisplayHardWarnin_0001 1 "TPMS_PRESSUREWARNING_INDICATED" 0 "TPMS_PRESSUREWARNING_NOT_INDICATED" ;
VAL_ 602 VCSEC_TPMSDisplayHardWarnin_0002 1 "TPMS_PRESSUREWARNING_INDICATED" 0 "TPMS_PRESSUREWARNING_NOT_INDICATED" ;
VAL_ 602 VCSEC_TPMSDisplayHardWarnin_0003 1 "TPMS_PRESSUREWARNING_INDICATED" 0 "TPMS_PRESSUREWARNING_NOT_INDICATED" ;
VAL_ 570 VCSEC_TPMSStatusIndex 39 "TireMileageContinued" 38 "TireMileage" 37 "SensorFilteredVoltageInfo" 36 "SensorTemperatureCompensatedVoltageInfo" 35 "LastLocationInfo" 34 "SensorHashInfo2" 33 "SensorHashInfo1" 32 "SensorConfiguration" 31 "ResetCountsContinuedSensor3" 30 "ResetCountsSensor3" 29 "ResetCountsContinuedSensor2" 28 "ResetCountsSensor2" 27 "ResetCountsContinuedSensor1" 26 "ResetCountsSensor1" 25 "ResetCountsContinuedSensor0" 24 "ResetCountsSensor0" 23 "SleepStatsSensor3" 22 "SleepStatsSensor2" 21 "SleepStatsSensor1" 20 "SleepStatsSensor0" 19 "CPUTimeSensor3" 18 "CPUTimeSensor2" 17 "CPUTimeSensor1" 16 "CPUTimeSensor0" 15 "CRCSensor3" 14 "CRCSensor2" 13 "CRCSensor1" 12 "CRCSensor0" 11 "ConnMetricsContinuedSensor3" 10 "ConnMetricsSensor3" 9 "ConnMetricsContinuedSensor2" 8 "ConnMetricsSensor2" 7 "ConnMetricsContinuedSensor1" 6 "ConnMetricsSensor1" 5 "ConnMetricsContinuedSensor0" 4 "ConnMetricsSensor0" 3 "MACAddressSensor3" 2 "MACAddressSensor2" 1 "MACAddressSensor1" 0 "MACAddressSensor0" ;
VAL_ 570 VCSEC_TPMSSystemState 1 "TPMS_SYSTEM_STATE_ACTIVE" 0 "TPMS_SYSTEM_STATE_IDLE" ;
VAL_ 570 VCSEC_BLEUnsuccessfulConnEventRa 1023 "SNA" ;
VAL_ 570 VCSEC_BLEUnsuccessfulConnEv_0001 1023 "SNA" ;
VAL_ 570 VCSEC_BLEUnsuccessfulConnEv_0002 1023 "SNA" ;
VAL_ 570 VCSEC_BLEUnsuccessfulConnEv_0003 1023 "SNA" ;
VAL_ 570 VCSEC_TPMSSensorTIAppCRC0 0 "TPMS_CRC_SNA" ;
VAL_ 570 VCSEC_TPMSSensorMLXAppCRC0 0 "TPMS_CRC_SNA" ;
VAL_ 570 VCSEC_TPMSSensorTIAppCRC1 0 "TPMS_CRC_SNA" ;
VAL_ 570 VCSEC_TPMSSensorMLXAppCRC1 0 "TPMS_CRC_SNA" ;
VAL_ 570 VCSEC_TPMSSensorTIAppCRC2 0 "TPMS_CRC_SNA" ;
VAL_ 570 VCSEC_TPMSSensorMLXAppCRC2 0 "TPMS_CRC_SNA" ;
VAL_ 570 VCSEC_TPMSSensorTIAppCRC3 0 "TPMS_CRC_SNA" ;
VAL_ 570 VCSEC_TPMSSensorMLXAppCRC3 0 "TPMS_CRC_SNA" ;
VAL_ 570 VCSEC_TPMSGenealogySensorState0 7 "SENSOR_STATE_DONE" 6 "SENSOR_STATE_WAIT_FOR_CAPABILITIES_RESPONSE" 5 "SENSOR_STATE_SEND_CAPABILITIES_REQUEST" 4 "SENSOR_STATE_WAIT_FOR_GENEALOGY_RESPONSE" 3 "SENSOR_STATE_SEND_GENEALOGY_REQUEST" 2 "SENSOR_STATE_WAIT_FOR_CODE_DESCRIPTOR_RESPONSE" 1 "SENSOR_STATE_SEND_CODE_DESCRIPTOR_REQUEST" 0 "SENSOR_STATE_WAIT_FOR_CONNECTION" ;
VAL_ 570 VCSEC_TPMSSensorType0 6 "SENSOR_TYPE_V5" 5 "SENSOR_TYPE_V4" 4 "SENSOR_TYPE_V3" 3 "SENSOR_TYPE_V2" 2 "SENSOR_TYPE_V1" 1 "SENSOR_TYPE_UNKNOWN" 0 "SENSOR_TYPE_NOT_IDENTIFIED" ;
VAL_ 570 VCSEC_TPMSGenealogySensorState1 7 "SENSOR_STATE_DONE" 6 "SENSOR_STATE_WAIT_FOR_CAPABILITIES_RESPONSE" 5 "SENSOR_STATE_SEND_CAPABILITIES_REQUEST" 4 "SENSOR_STATE_WAIT_FOR_GENEALOGY_RESPONSE" 3 "SENSOR_STATE_SEND_GENEALOGY_REQUEST" 2 "SENSOR_STATE_WAIT_FOR_CODE_DESCRIPTOR_RESPONSE" 1 "SENSOR_STATE_SEND_CODE_DESCRIPTOR_REQUEST" 0 "SENSOR_STATE_WAIT_FOR_CONNECTION" ;
VAL_ 570 VCSEC_TPMSSensorType1 6 "SENSOR_TYPE_V5" 5 "SENSOR_TYPE_V4" 4 "SENSOR_TYPE_V3" 3 "SENSOR_TYPE_V2" 2 "SENSOR_TYPE_V1" 1 "SENSOR_TYPE_UNKNOWN" 0 "SENSOR_TYPE_NOT_IDENTIFIED" ;
VAL_ 570 VCSEC_TPMSGenealogySensorState2 7 "SENSOR_STATE_DONE" 6 "SENSOR_STATE_WAIT_FOR_CAPABILITIES_RESPONSE" 5 "SENSOR_STATE_SEND_CAPABILITIES_REQUEST" 4 "SENSOR_STATE_WAIT_FOR_GENEALOGY_RESPONSE" 3 "SENSOR_STATE_SEND_GENEALOGY_REQUEST" 2 "SENSOR_STATE_WAIT_FOR_CODE_DESCRIPTOR_RESPONSE" 1 "SENSOR_STATE_SEND_CODE_DESCRIPTOR_REQUEST" 0 "SENSOR_STATE_WAIT_FOR_CONNECTION" ;
VAL_ 570 VCSEC_TPMSSensorType2 6 "SENSOR_TYPE_V5" 5 "SENSOR_TYPE_V4" 4 "SENSOR_TYPE_V3" 3 "SENSOR_TYPE_V2" 2 "SENSOR_TYPE_V1" 1 "SENSOR_TYPE_UNKNOWN" 0 "SENSOR_TYPE_NOT_IDENTIFIED" ;
VAL_ 570 VCSEC_TPMSGenealogySensorState3 7 "SENSOR_STATE_DONE" 6 "SENSOR_STATE_WAIT_FOR_CAPABILITIES_RESPONSE" 5 "SENSOR_STATE_SEND_CAPABILITIES_REQUEST" 4 "SENSOR_STATE_WAIT_FOR_GENEALOGY_RESPONSE" 3 "SENSOR_STATE_SEND_GENEALOGY_REQUEST" 2 "SENSOR_STATE_WAIT_FOR_CODE_DESCRIPTOR_RESPONSE" 1 "SENSOR_STATE_SEND_CODE_DESCRIPTOR_REQUEST" 0 "SENSOR_STATE_WAIT_FOR_CONNECTION" ;
VAL_ 570 VCSEC_TPMSSensorType3 6 "SENSOR_TYPE_V5" 5 "SENSOR_TYPE_V4" 4 "SENSOR_TYPE_V3" 3 "SENSOR_TYPE_V2" 2 "SENSOR_TYPE_V1" 1 "SENSOR_TYPE_UNKNOWN" 0 "SENSOR_TYPE_NOT_IDENTIFIED" ;
VAL_ 570 VCSEC_TPMSLastLocationSensor0 4 "LOCATION_UNKNOWN" 3 "LOCATION_RR" 2 "LOCATION_RL" 1 "LOCATION_FR" 0 "LOCATION_FL" ;
VAL_ 570 VCSEC_TPMSLastLocationSensor1 4 "LOCATION_UNKNOWN" 3 "LOCATION_RR" 2 "LOCATION_RL" 1 "LOCATION_FR" 0 "LOCATION_FL" ;
VAL_ 570 VCSEC_TPMSLastLocationSensor2 4 "LOCATION_UNKNOWN" 3 "LOCATION_RR" 2 "LOCATION_RL" 1 "LOCATION_FR" 0 "LOCATION_FL" ;
VAL_ 570 VCSEC_TPMSLastLocationSensor3 4 "LOCATION_UNKNOWN" 3 "LOCATION_RR" 2 "LOCATION_RL" 1 "LOCATION_FR" 0 "LOCATION_FL" ;
VAL_ 570 VCSEC_TPMSTemperatureCompensated 255 "SNA" ;
VAL_ 570 VCSEC_TPMSTemperatureCompen_0001 255 "SNA" ;
VAL_ 570 VCSEC_TPMSTemperatureCompen_0002 255 "SNA" ;
VAL_ 570 VCSEC_TPMSTemperatureCompen_0003 255 "SNA" ;
VAL_ 570 VCSEC_TPMSFilteredBatVoltage0 255 "SNA" ;
VAL_ 570 VCSEC_TPMSFilteredBatVoltage2 255 "SNA" ;
VAL_ 570 VCSEC_TPMSFilteredBatVoltage1 255 "SNA" ;
VAL_ 570 VCSEC_TPMSFilteredBatVoltage3 255 "SNA" ;
VAL_ 1067 VCSEC_UWBEndpointIndex 4 "UWBDistance0" 3 "UWBDistance1" 2 "UWBDistance2" 1 "UWBDistanceRemote" 0 "UWBRearRightDistance" ;
VAL_ 1067 VCSEC_UWBRearRightDistance0 4095 "SNA" 4094 "NOT_ENABLED" 4093 "INITIATOR_TIMEOUT" 4092 "RESPONDER_TIMEOUT" 4091 "INVALID_DISTANCE" 4090 "HCI_TIMEOUT" 4089 "RESPONDER_ERROR" 4088 "KEYFOB_DIDNT_RESPOND" 4087 "TX_FAILED" 4086 "RX_TIMEOUT" 4085 "PHY_DEC_FAILED" 4084 "TOA_FAILED" 4083 "STS_FAILED" 4082 "MAC_DEC_FAILED" 4081 "IE_DEC_FAILED" 4080 "IE_MISSING" ;
VAL_ 1067 VCSEC_UWBRearRightDistance1 4095 "SNA" 4094 "NOT_ENABLED" 4093 "INITIATOR_TIMEOUT" 4092 "RESPONDER_TIMEOUT" 4091 "INVALID_DISTANCE" 4090 "HCI_TIMEOUT" 4089 "RESPONDER_ERROR" 4088 "KEYFOB_DIDNT_RESPOND" 4087 "TX_FAILED" 4086 "RX_TIMEOUT" 4085 "PHY_DEC_FAILED" 4084 "TOA_FAILED" 4083 "STS_FAILED" 4082 "MAC_DEC_FAILED" 4081 "IE_DEC_FAILED" 4080 "IE_MISSING" ;
VAL_ 1067 VCSEC_UWBRearRightDistance2 4095 "SNA" 4094 "NOT_ENABLED" 4093 "INITIATOR_TIMEOUT" 4092 "RESPONDER_TIMEOUT" 4091 "INVALID_DISTANCE" 4090 "HCI_TIMEOUT" 4089 "RESPONDER_ERROR" 4088 "KEYFOB_DIDNT_RESPOND" 4087 "TX_FAILED" 4086 "RX_TIMEOUT" 4085 "PHY_DEC_FAILED" 4084 "TOA_FAILED" 4083 "STS_FAILED" 4082 "MAC_DEC_FAILED" 4081 "IE_DEC_FAILED" 4080 "IE_MISSING" ;
VAL_ 1067 VCSEC_UWBLeftDistance3 4095 "SNA" 4094 "NOT_ENABLED" 4093 "INITIATOR_TIMEOUT" 4092 "RESPONDER_TIMEOUT" 4091 "INVALID_DISTANCE" 4090 "HCI_TIMEOUT" 4089 "RESPONDER_ERROR" 4088 "KEYFOB_DIDNT_RESPOND" 4087 "TX_FAILED" 4086 "RX_TIMEOUT" 4085 "PHY_DEC_FAILED" 4084 "TOA_FAILED" 4083 "STS_FAILED" 4082 "MAC_DEC_FAILED" 4081 "IE_DEC_FAILED" 4080 "IE_MISSING" ;
VAL_ 1067 VCSEC_UWBRightDistance3 4095 "SNA" 4094 "NOT_ENABLED" 4093 "INITIATOR_TIMEOUT" 4092 "RESPONDER_TIMEOUT" 4091 "INVALID_DISTANCE" 4090 "HCI_TIMEOUT" 4089 "RESPONDER_ERROR" 4088 "KEYFOB_DIDNT_RESPOND" 4087 "TX_FAILED" 4086 "RX_TIMEOUT" 4085 "PHY_DEC_FAILED" 4084 "TOA_FAILED" 4083 "STS_FAILED" 4082 "MAC_DEC_FAILED" 4081 "IE_DEC_FAILED" 4080 "IE_MISSING" ;
VAL_ 1067 VCSEC_UWBRearRightDistance3 4095 "SNA" 4094 "NOT_ENABLED" 4093 "INITIATOR_TIMEOUT" 4092 "RESPONDER_TIMEOUT" 4091 "INVALID_DISTANCE" 4090 "HCI_TIMEOUT" 4089 "RESPONDER_ERROR" 4088 "KEYFOB_DIDNT_RESPOND" 4087 "TX_FAILED" 4086 "RX_TIMEOUT" 4085 "PHY_DEC_FAILED" 4084 "TOA_FAILED" 4083 "STS_FAILED" 4082 "MAC_DEC_FAILED" 4081 "IE_DEC_FAILED" 4080 "IE_MISSING" ;
VAL_ 1067 VCSEC_UWBRearLeftDistance3 4095 "SNA" 4094 "NOT_ENABLED" 4093 "INITIATOR_TIMEOUT" 4092 "RESPONDER_TIMEOUT" 4091 "INVALID_DISTANCE" 4090 "HCI_TIMEOUT" 4089 "RESPONDER_ERROR" 4088 "KEYFOB_DIDNT_RESPOND" 4087 "TX_FAILED" 4086 "RX_TIMEOUT" 4085 "PHY_DEC_FAILED" 4084 "TOA_FAILED" 4083 "STS_FAILED" 4082 "MAC_DEC_FAILED" 4081 "IE_DEC_FAILED" 4080 "IE_MISSING" ;
VAL_ 1067 VCSEC_UWBCenterDistance3 4095 "SNA" 4094 "NOT_ENABLED" 4093 "INITIATOR_TIMEOUT" 4092 "RESPONDER_TIMEOUT" 4091 "INVALID_DISTANCE" 4090 "HCI_TIMEOUT" 4089 "RESPONDER_ERROR" 4088 "KEYFOB_DIDNT_RESPOND" 4087 "TX_FAILED" 4086 "RX_TIMEOUT" 4085 "PHY_DEC_FAILED" 4084 "TOA_FAILED" 4083 "STS_FAILED" 4082 "MAC_DEC_FAILED" 4081 "IE_DEC_FAILED" 4080 "IE_MISSING" ;
VAL_ 1067 VCSEC_UWBLeftDistance2 4095 "SNA" 4094 "NOT_ENABLED" 4093 "INITIATOR_TIMEOUT" 4092 "RESPONDER_TIMEOUT" 4091 "INVALID_DISTANCE" 4090 "HCI_TIMEOUT" 4089 "RESPONDER_ERROR" 4088 "KEYFOB_DIDNT_RESPOND" 4087 "TX_FAILED" 4086 "RX_TIMEOUT" 4085 "PHY_DEC_FAILED" 4084 "TOA_FAILED" 4083 "STS_FAILED" 4082 "MAC_DEC_FAILED" 4081 "IE_DEC_FAILED" 4080 "IE_MISSING" ;
VAL_ 1067 VCSEC_UWBRightDistance2 4095 "SNA" 4094 "NOT_ENABLED" 4093 "INITIATOR_TIMEOUT" 4092 "RESPONDER_TIMEOUT" 4091 "INVALID_DISTANCE" 4090 "HCI_TIMEOUT" 4089 "RESPONDER_ERROR" 4088 "KEYFOB_DIDNT_RESPOND" 4087 "TX_FAILED" 4086 "RX_TIMEOUT" 4085 "PHY_DEC_FAILED" 4084 "TOA_FAILED" 4083 "STS_FAILED" 4082 "MAC_DEC_FAILED" 4081 "IE_DEC_FAILED" 4080 "IE_MISSING" ;
VAL_ 1067 VCSEC_UWBRearDistance2 4095 "SNA" 4094 "NOT_ENABLED" 4093 "INITIATOR_TIMEOUT" 4092 "RESPONDER_TIMEOUT" 4091 "INVALID_DISTANCE" 4090 "HCI_TIMEOUT" 4089 "RESPONDER_ERROR" 4088 "KEYFOB_DIDNT_RESPOND" 4087 "TX_FAILED" 4086 "RX_TIMEOUT" 4085 "PHY_DEC_FAILED" 4084 "TOA_FAILED" 4083 "STS_FAILED" 4082 "MAC_DEC_FAILED" 4081 "IE_DEC_FAILED" 4080 "IE_MISSING" ;
VAL_ 1067 VCSEC_UWBRearLeftDistance2 4095 "SNA" 4094 "NOT_ENABLED" 4093 "INITIATOR_TIMEOUT" 4092 "RESPONDER_TIMEOUT" 4091 "INVALID_DISTANCE" 4090 "HCI_TIMEOUT" 4089 "RESPONDER_ERROR" 4088 "KEYFOB_DIDNT_RESPOND" 4087 "TX_FAILED" 4086 "RX_TIMEOUT" 4085 "PHY_DEC_FAILED" 4084 "TOA_FAILED" 4083 "STS_FAILED" 4082 "MAC_DEC_FAILED" 4081 "IE_DEC_FAILED" 4080 "IE_MISSING" ;
VAL_ 1067 VCSEC_UWBCenterDistance2 4095 "SNA" 4094 "NOT_ENABLED" 4093 "INITIATOR_TIMEOUT" 4092 "RESPONDER_TIMEOUT" 4091 "INVALID_DISTANCE" 4090 "HCI_TIMEOUT" 4089 "RESPONDER_ERROR" 4088 "KEYFOB_DIDNT_RESPOND" 4087 "TX_FAILED" 4086 "RX_TIMEOUT" 4085 "PHY_DEC_FAILED" 4084 "TOA_FAILED" 4083 "STS_FAILED" 4082 "MAC_DEC_FAILED" 4081 "IE_DEC_FAILED" 4080 "IE_MISSING" ;
VAL_ 1067 VCSEC_UWBLeftDistance1 4095 "SNA" 4094 "NOT_ENABLED" 4093 "INITIATOR_TIMEOUT" 4092 "RESPONDER_TIMEOUT" 4091 "INVALID_DISTANCE" 4090 "HCI_TIMEOUT" 4089 "RESPONDER_ERROR" 4088 "KEYFOB_DIDNT_RESPOND" 4087 "TX_FAILED" 4086 "RX_TIMEOUT" 4085 "PHY_DEC_FAILED" 4084 "TOA_FAILED" 4083 "STS_FAILED" 4082 "MAC_DEC_FAILED" 4081 "IE_DEC_FAILED" 4080 "IE_MISSING" ;
VAL_ 1067 VCSEC_UWBRightDistance1 4095 "SNA" 4094 "NOT_ENABLED" 4093 "INITIATOR_TIMEOUT" 4092 "RESPONDER_TIMEOUT" 4091 "INVALID_DISTANCE" 4090 "HCI_TIMEOUT" 4089 "RESPONDER_ERROR" 4088 "KEYFOB_DIDNT_RESPOND" 4087 "TX_FAILED" 4086 "RX_TIMEOUT" 4085 "PHY_DEC_FAILED" 4084 "TOA_FAILED" 4083 "STS_FAILED" 4082 "MAC_DEC_FAILED" 4081 "IE_DEC_FAILED" 4080 "IE_MISSING" ;
VAL_ 1067 VCSEC_UWBRearDistance1 4095 "SNA" 4094 "NOT_ENABLED" 4093 "INITIATOR_TIMEOUT" 4092 "RESPONDER_TIMEOUT" 4091 "INVALID_DISTANCE" 4090 "HCI_TIMEOUT" 4089 "RESPONDER_ERROR" 4088 "KEYFOB_DIDNT_RESPOND" 4087 "TX_FAILED" 4086 "RX_TIMEOUT" 4085 "PHY_DEC_FAILED" 4084 "TOA_FAILED" 4083 "STS_FAILED" 4082 "MAC_DEC_FAILED" 4081 "IE_DEC_FAILED" 4080 "IE_MISSING" ;
VAL_ 1067 VCSEC_UWBRearLeftDistance1 4095 "SNA" 4094 "NOT_ENABLED" 4093 "INITIATOR_TIMEOUT" 4092 "RESPONDER_TIMEOUT" 4091 "INVALID_DISTANCE" 4090 "HCI_TIMEOUT" 4089 "RESPONDER_ERROR" 4088 "KEYFOB_DIDNT_RESPOND" 4087 "TX_FAILED" 4086 "RX_TIMEOUT" 4085 "PHY_DEC_FAILED" 4084 "TOA_FAILED" 4083 "STS_FAILED" 4082 "MAC_DEC_FAILED" 4081 "IE_DEC_FAILED" 4080 "IE_MISSING" ;
VAL_ 1067 VCSEC_UWBCenterDistance1 4095 "SNA" 4094 "NOT_ENABLED" 4093 "INITIATOR_TIMEOUT" 4092 "RESPONDER_TIMEOUT" 4091 "INVALID_DISTANCE" 4090 "HCI_TIMEOUT" 4089 "RESPONDER_ERROR" 4088 "KEYFOB_DIDNT_RESPOND" 4087 "TX_FAILED" 4086 "RX_TIMEOUT" 4085 "PHY_DEC_FAILED" 4084 "TOA_FAILED" 4083 "STS_FAILED" 4082 "MAC_DEC_FAILED" 4081 "IE_DEC_FAILED" 4080 "IE_MISSING" ;
VAL_ 1067 VCSEC_UWBLeftDistance0 4095 "SNA" 4094 "NOT_ENABLED" 4093 "INITIATOR_TIMEOUT" 4092 "RESPONDER_TIMEOUT" 4091 "INVALID_DISTANCE" 4090 "HCI_TIMEOUT" 4089 "RESPONDER_ERROR" 4088 "KEYFOB_DIDNT_RESPOND" 4087 "TX_FAILED" 4086 "RX_TIMEOUT" 4085 "PHY_DEC_FAILED" 4084 "TOA_FAILED" 4083 "STS_FAILED" 4082 "MAC_DEC_FAILED" 4081 "IE_DEC_FAILED" 4080 "IE_MISSING" ;
VAL_ 1067 VCSEC_UWBRightDistance0 4095 "SNA" 4094 "NOT_ENABLED" 4093 "INITIATOR_TIMEOUT" 4092 "RESPONDER_TIMEOUT" 4091 "INVALID_DISTANCE" 4090 "HCI_TIMEOUT" 4089 "RESPONDER_ERROR" 4088 "KEYFOB_DIDNT_RESPOND" 4087 "TX_FAILED" 4086 "RX_TIMEOUT" 4085 "PHY_DEC_FAILED" 4084 "TOA_FAILED" 4083 "STS_FAILED" 4082 "MAC_DEC_FAILED" 4081 "IE_DEC_FAILED" 4080 "IE_MISSING" ;
VAL_ 1067 VCSEC_UWBRearDistance0 4095 "SNA" 4094 "NOT_ENABLED" 4093 "INITIATOR_TIMEOUT" 4092 "RESPONDER_TIMEOUT" 4091 "INVALID_DISTANCE" 4090 "HCI_TIMEOUT" 4089 "RESPONDER_ERROR" 4088 "KEYFOB_DIDNT_RESPOND" 4087 "TX_FAILED" 4086 "RX_TIMEOUT" 4085 "PHY_DEC_FAILED" 4084 "TOA_FAILED" 4083 "STS_FAILED" 4082 "MAC_DEC_FAILED" 4081 "IE_DEC_FAILED" 4080 "IE_MISSING" ;
VAL_ 1067 VCSEC_UWBRearLeftDistance0 4095 "SNA" 4094 "NOT_ENABLED" 4093 "INITIATOR_TIMEOUT" 4092 "RESPONDER_TIMEOUT" 4091 "INVALID_DISTANCE" 4090 "HCI_TIMEOUT" 4089 "RESPONDER_ERROR" 4088 "KEYFOB_DIDNT_RESPOND" 4087 "TX_FAILED" 4086 "RX_TIMEOUT" 4085 "PHY_DEC_FAILED" 4084 "TOA_FAILED" 4083 "STS_FAILED" 4082 "MAC_DEC_FAILED" 4081 "IE_DEC_FAILED" 4080 "IE_MISSING" ;
VAL_ 1067 VCSEC_UWBCenterDistance0 4095 "SNA" 4094 "NOT_ENABLED" 4093 "INITIATOR_TIMEOUT" 4092 "RESPONDER_TIMEOUT" 4091 "INVALID_DISTANCE" 4090 "HCI_TIMEOUT" 4089 "RESPONDER_ERROR" 4088 "KEYFOB_DIDNT_RESPOND" 4087 "TX_FAILED" 4086 "RX_TIMEOUT" 4085 "PHY_DEC_FAILED" 4084 "TOA_FAILED" 4083 "STS_FAILED" 4082 "MAC_DEC_FAILED" 4081 "IE_DEC_FAILED" 4080 "IE_MISSING" ;
VAL_ 761 VCSEC_bleDisconnectionReason 255 "UNKNOWN_REASON_FF" 62 "CONNECTION_FAILED_TO_ESTABLISH" 61 "MIC_FAILURE" 59 "UNACCEPTABLE_CONNECTION_INTERVAL" 41 "KEY_PAIRING_NOT_SUPPORTED" 40 "CONTROL_PACKET_INSTANT_PASSED" 34 "CONTROL_PACKET_TIMEOUT" 26 "UNSUPPORTED_REMOTE_FEATURE" 22 "HOST_REQUESTED_TERMINATION" 21 "REMOTE_DEVICE_POWER_OFF" 20 "REMOTE_DEVICE_LOW_RESOURCES" 19 "REMOTE_USER_TERMINATED" 8 "CONNECTION_SUPERVISION_TIMEOUT" 5 "AUTHENTICATION_FAILURE" 0 "UNKNOWN_REASON_0" ;
VAL_ 761 VCSEC_AdditionalAuthInfoIndex 5 "WALKUP_UNLOCK_BEHAVIOR" 4 "UNKNOWN_BLE_DEVICE_WITH_IN_SUMMON_RANGE" 3 "KEY_WITH_IN_SUMMON_RANGE_2" 2 "KEY_WITH_IN_SUMMON_RANGE_1" 1 "KEY_WITH_IN_SUMMON_RANGE_0" 0 "ACTIVE_KEY_SHA1" ;
VAL_ 761 VCSEC_activeKeyReason 7 "ACTIVE_KEY_SELECTION_REASON_UWB_DEVICE_CLOSEST_TO_DOOR" 6 "ACTIVE_KEY_SELECTION_REASON_AUTO_PRESENT_DOOR_COMMAND" 5 "ACTIVE_KEY_SELECTION_REASON_ONLY_AUTHED_DEVICE" 4 "ACTIVE_KEY_SELECTION_REASON_RKE_ACTION" 3 "ACTIVE_KEY_SELECTION_REASON_BLE_DEVICE_CLOSEST_TO_DOOR" 2 "ACTIVE_KEY_SELECTION_REASON_RKE_AUTH" 1 "ACTIVE_KEY_SELECTION_REASON_NFC_AUTH" 0 "ACTIVE_KEY_SELECTION_REASON_NONE" ;
VAL_ 761 VCSEC_algoUsedForSummonRange0 1 "SUMMON_RANGE_ALGO_USED_UWB" 0 "SUMMON_RANGE_ALGO_USED_BLE" ;
VAL_ 761 VCSEC_algoUsedForSummonRange1 1 "SUMMON_RANGE_ALGO_USED_UWB" 0 "SUMMON_RANGE_ALGO_USED_BLE" ;
VAL_ 761 VCSEC_algoUsedForSummonRange2 1 "SUMMON_RANGE_ALGO_USED_UWB" 0 "SUMMON_RANGE_ALGO_USED_BLE" ;
VAL_ 761 VCSEC_frunkOpenSuggestionRespons 6 "SUGGESTIONS_RESPONSE_CLOSURE_SUGGESTION_DISABLED" 5 "SUGGESTIONS_RESPONSE_FAIL_TO_SETUP" 4 "SUGGESTIONS_RESPONSE_TIMEOUT_CLEARED" 3 "SUGGESTIONS_RESPONSE_CLEARED_BY_USER" 2 "SUGGESTIONS_RESPONSE_REJECTED_BY_USER" 1 "SUGGESTIONS_RESPONSE_ACCEPTED_BY_USER" 0 "SUGGESTIONS_RESPONSE_UNKNOWN" ;
VAL_ 761 VCSEC_NFCAuthFromBPillarFormFact 4 "KEY_FORM_FACTOR_COARSE_UNKNOWN" 3 "KEY_FORM_FACTOR_COARSE_ANDROID" 2 "KEY_FORM_FACTOR_COARSE_KEYFOB" 1 "KEY_FORM_FACTOR_COARSE_NFC_CARD" 0 "KEY_FORM_FACTOR_COARSE_NONE" ;
VAL_ 761 VCSEC_NFCAuthFromCenterConsoleFo 4 "KEY_FORM_FACTOR_COARSE_UNKNOWN" 3 "KEY_FORM_FACTOR_COARSE_ANDROID" 2 "KEY_FORM_FACTOR_COARSE_KEYFOB" 1 "KEY_FORM_FACTOR_COARSE_NFC_CARD" 0 "KEY_FORM_FACTOR_COARSE_NONE" ;
VAL_ 761 VCSEC_trunkOpenSuggestionRespons 6 "SUGGESTIONS_RESPONSE_CLOSURE_SUGGESTION_DISABLED" 5 "SUGGESTIONS_RESPONSE_FAIL_TO_SETUP" 4 "SUGGESTIONS_RESPONSE_TIMEOUT_CLEARED" 3 "SUGGESTIONS_RESPONSE_CLEARED_BY_USER" 2 "SUGGESTIONS_RESPONSE_REJECTED_BY_USER" 1 "SUGGESTIONS_RESPONSE_ACCEPTED_BY_USER" 0 "SUGGESTIONS_RESPONSE_UNKNOWN" ;
VAL_ 1328 VCSEC_alertID 540 "a540_dummyAlertMax" 529 "a529_TPMSTireServiceDetected" 528 "a528_TPMSLocalizationMultipleSensorsForPositionRR" 527 "a527_TPMSLocalizationMultipleSensorsForPositionRL" 526 "a526_TPMSLocalizationMultipleSensorsForPositionFR" 525 "a525_TPMSLocalizationMultipleSensorsForPositionFL" 524 "a524_TPMSSensorLowConfidenceSensorLocalization3" 523 "a523_TPMSSensorLowConfidenceSensorLocalization2" 522 "a522_TPMSSensorLowConfidenceSensorLocalization1" 521 "a521_TPMSSensorLowConfidenceSensorLocalization0" 520 "a520_TPMSOutOfRangePressureReceived3" 519 "a519_TPMSOutOfRangePressureReceived2" 518 "a518_TPMSOutOfRangePressureReceived1" 517 "a517_TPMSOutOfRangePressureReceived0" 516 "a516_TPMSConnectionStatsNotReceived3" 515 "a515_TPMSConnectionStatsNotReceived2" 514 "a514_TPMSConnectionStatsNotReceived1" 513 "a513_TPMSConnectionStatsNotReceived0" 511 "a511_phoneKeyStationary" 510 "a510_watchKeyOffWrist" 505 "a505_CANMsgMACVerificationKeyMismatch" 504 "a504_CANMsgMACVerificationKeyNotProvisioned" 503 "a503_CANMsgMACVerificationFailure" 502 "a502_TPMSAssertFailure3" 501 "a501_TPMSAssertFailure2" 500 "a500_TPMSAssertFailure1" 499 "a499_TPMSAssertFailure0" 498 "a498_TPMSFeature0Reached" 497 "a497_incorrectEndpointInstallation" 496 "a496_handlePullWithoutAuth_Android" 495 "a495_handlePullWithoutAuth_iOS" 494 "a494_UWBRearUpdateTriggered" 490 "a490_UWBRearRightUpdateTriggered" 489 "a489_UWBRearLeftUpdateTriggered" 488 "a488_FiraRangingRejected" 487 "a487_unrecognizedProto" 486 "a486_UWBRightUpdateTriggered" 485 "a485_UWBCenterUpdateTriggered" 484 "a484_UWBLeftUpdateTriggered" 483 "a483_highThermalGradiantDetected" 482 "a482_VINChanged" 481 "a481_handlePullWithoutAuthNIStateDev2" 480 "a480_handlePullWithoutAuthNIStateDev1" 479 "a479_handlePullWithoutAuthNIStateDev0" 478 "a478_handlePullWithoutAuth7" 477 "a477_phoneStartedBonding" 476 "a476_handlePullWithoutAuth6" 475 "a475_handlePullWithoutAuth5" 474 "a474_handlePullWithoutAuth4" 473 "a473_handlePullWithoutAuth3" 472 "a472_peerRemovedInformation" 470 "a470_UWBRightKeyVerificationFailure" 469 "a469_UWBLeftKeyVerificationFailure" 468 "a468_UWBRearKeyVerificationFailure" 467 "a467_UWBCenterKeyVerificationFailure" 466 "a466_UWBRearRightKeyVerificationFailure" 465 "a465_UWBRearLeftKeyVerificationFailure" 462 "a462_TPMSCertCheckFailedSensor3" 461 "a461_TPMSCertCheckFailedSensor2" 460 "a460_TPMSCertCheckFailedSensor1" 459 "a459_TPMSCertCheckFailedSensor0" 458 "a458_TPMSOverPressureWarningRearRight" 457 "a457_TPMSOverPressureWarningRearLeft" 456 "a456_TPMSOverPressureWarningFrontRight" 455 "a455_TPMSOverPressureWarningFrontLeft" 454 "a454_TPMSOverPressureWarning" 453 "a453_passiveDisabled" 438 "a438_UWBRearUpdateInterrupted" 437 "a437_NearbyInteractionDebug" 436 "a436_uhfHWDoesNotMatchCountry" 435 "a435_NFCCardPresentWhileCharging" 434 "a434_UWBRadioConfigUpdated" 433 "a433_UWBRearRightUpdateInterrupted" 432 "a432_UWBRearLeftUpdateInterrupted" 430 "a430_UWBRightUpdateInterrupted" 429 "a429_UWBLeftUpdateInterrupted" 428 "a428_UWBCenterUpdateInterrupted" 427 "a427_BLERearRightAssertFailure" 426 "a426_BLERearLeftAssertFailure" 425 "a425_BLENFCCradleAssertFailure" 422 "a422_BLEUnexpectedResetRR" 421 "a421_BLEUnexpectedResetRL" 420 "a420_BLEUnexpectedResetNFCCradle" 418 "a418_BLERearRightSoftReset" 417 "a417_BLERearLeftSoftReset" 416 "a416_BLECradleNFCSoftReset" 413 "a413_NFCCradleEndpointBusy" 412 "a412_rightRearEndpointBusy" 411 "a411_leftRearEndpointBusy" 408 "a408_hciDebugNFCC" 407 "a407_hciDebugRR" 406 "a406_hciDebugRL" 404 "a404_NFCCradleEndpointLostComm" 402 "a402_rearRightEndpointLostComm" 401 "a401_rearLeftEndpointLostComm" 316 "a316_ltkRequestRejected" 315 "a315_bleBondingEvent" 312 "a312_unexpectedBLEDisconnect" 311 "a311_moreThanThreeKeysPresent" 310 "a310_chargePortFilterFalsePositive" 309 "a309_serviceKeyConditionsNotMet" 308 "a308_NonConnectableAdvReceived" 307 "a307_ATTTimeout" 306 "a306_KeyfobAdvReceivedWhileConnected" 305 "a305_ATTFlowControlViolatedC" 304 "a304_KeyfobUpdateComplete" 303 "a303_KeyfobUpdateInterrupted" 302 "a302_unfused" 301 "a301_imposterDetected" 300 "a300_scheduleItKeyAdded" 283 "a283_TPMSLowBattery3" 282 "a282_TPMSLowBattery2" 281 "a281_TPMSLowBattery1" 280 "a280_TPMSLowBattery0" 277 "a277_childSeatBatteryIsLow" 276 "a276_childSeatNotConnectedAtEndOfDrive" 275 "a275_childSeatNotConnectedAtStartOfDrive" 274 "a274_handlePullWithoutAuth2" 273 "a273_TPMSHardWarningRearRight" 272 "a272_TPMSHardWarningRearLeft" 271 "a271_TPMSHardWarningFrontRight" 270 "a270_TPMSHardWarningFrontLeft" 269 "a269_TPMSSoftWarningRearRight" 268 "a268_TPMSSoftWarningRearLeft" 267 "a267_TPMSSoftWarningFrontRight" 266 "a266_TPMSSoftWarningFrontLeft" 265 "a265_tooManyPopulatedMessage" 264 "a264_noOnePopulatedMessage" 263 "a263_dispatchCouldNotBeCompleted" 262 "a262_flowControlBackedUp" 261 "a261_TPMSFactoryLearnActive" 260 "a260_prsntPhoneKeyDisconnected" 258 "a258_keyIsExpiring" 257 "a257_connectedKeyIsExpiring" 256 "a256_whitelistOperationFail" 255 "a255_wlistUpdatedPermission" 254 "a254_whitelistUpdatedKey" 252 "a252_TPMSUpdateCompleteSensor3" 251 "a251_TPMSUpdateCompleteSensor2" 250 "a250_TPMSUpdateCompleteSensor1" 249 "a249_TPMSUpdateCompleteSensor0" 248 "a248_TPMSUpdateInterruptedSensor3" 247 "a247_TPMSUpdateInterruptedSensor2" 246 "a246_TPMSUpdateInterruptedSensor1" 245 "a245_TPMSUpdateInterruptedSensor0" 244 "a244_TPMSUpdateStartedSensor3" 243 "a243_TPMSUpdateStartedSensor2" 242 "a242_TPMSUpdateStartedSensor1" 241 "a241_TPMSUpdateStartedSensor0" 240 "a240_noKeysPaired" 239 "a239_TPMSIdleConnection" 238 "a238_TPMSLocationsUpdated" 237 "a237_keyNotReadyToReceiveIDRequests" 236 "a236_keyIdentificationMaxAttemptReached" 235 "a235_presentWithoutHandlePull" 228 "a228_TPMSHardWarning" 227 "a227_connectionWithoutLinkEvent" 226 "a226_TPMSSensorConnectionCycling3" 225 "a225_TPMSSensorConnectionCycling2" 224 "a224_TPMSSensorConnectionCycling1" 223 "a223_TPMSSensorConnectionCycling0" 222 "a222_TPMSSystemMalfunction" 221 "a221_TPMSSoftWarning" 220 "a220_TPMSSensorPairingNotCompleted" 219 "a219_TPMSSensorPairingRemoved" 218 "a218_TPMSUnexpectedDisconnectSensor3" 217 "a217_TPMSUnexpectedDisconnectSensor2" 216 "a216_TPMSUnexpectedDisconnectSensor1" 215 "a215_TPMSUnexpectedDisconnectSensor0" 214 "a214_gattServFalseWaitToBoot" 213 "a213_gattTimeoutWithExptdCount" 212 "a212_snifferRSSIMIA" 211 "a211_handlePullWithoutAuth" 210 "a210_keyDeviceBatteryLow" 209 "a209_BLECenterAssertFailure" 208 "a208_BLERearAssertFailure" 207 "a207_BLERightAssertFailure" 206 "a206_BLELeftAssertFailure" 205 "a205_MTUUpdateNotConfirmed" 204 "a204_SharedSecretsWritten" 203 "a203_rearEndpointLostComm" 202 "a202_rightEndpointLostComm" 201 "a201_leftEndpointLostComm" 200 "a200_centerEndpointLostComm" 199 "a199_CenterNFCReaderMIA" 198 "a198_BPillarNFCReaderMIA" 197 "a197_indicationFault" 196 "a196_protobufTXTimeout" 195 "a195_keyMissingInDrive" 194 "a194_macIDWlistingFailedRe" 193 "a193_macIDWlistingFailedRi" 192 "a192_macIDWlistingFailedL" 191 "a191_macIDWlistingFailedC" 190 "a190_protoTooManyBytes" 189 "a189_protoExpLengthTooLarge" 188 "a188_protobufDecodeError" 187 "a187_badConnectionDropped" 186 "a186_rearEndpointRFMia" 185 "a185_passengerEndpointRFMia" 184 "a184_driverEndpointRFMia" 183 "a183_centerEndpointRFMia" 182 "a182_cryptoHighStackUsage" 181 "a181_signedMessageFault" 180 "a180_wlistRemovedPermission" 179 "a179_InfotainmentNotPaired" 178 "a178_whitelistRemovedKey" 177 "a177_whitelistAddedKey" 175 "a175_BLEUnexpectedResetRe" 174 "a174_BLEUnexpectedResetRi" 173 "a173_BLEUnexpectedResetL" 172 "a172_BLEUnexpectedResetC" 170 "a170_BLERearSoftReset" 169 "a169_BLERightSoftReset" 168 "a168_BLELeftSoftReset" 167 "a167_BLECenterSoftReset" 166 "a166_BLECenterPowerCycled" 165 "a165_ephemeralKeyGenerated" 164 "a164_attrsWentMissingC" 162 "a162_hciDebugRe" 161 "a161_hciDebugR" 159 "a159_hciDebugL" 158 "a158_hciDebugC" 156 "a156_srvcCmdTimeoutRe" 155 "a155_srvcCmdTimeoutR" 154 "a154_srvcCmdTimeoutL" 153 "a153_srvcCmdTimeoutC" 151 "a151_attrsWentMissingRe" 150 "a150_attrsWentMissingR" 149 "a149_attrsWentMissingL" 148 "a148_keyWhitelistFull" 147 "a147_protobufRXTimeout" 145 "a145_bleGattAlertRe" 144 "a144_bleGattAlertR" 143 "a143_bleGattAlertL" 142 "a142_bleGattAlertC" 141 "a141_tooFewKeysOnWhitelist" 140 "a140_nfcAuthentication" 138 "a138_rearEndpointBusy" 137 "a137_rightEndpointBusy" 136 "a136_leftEndpointBusy" 135 "a135_centerEndpointBusy" 134 "a134_noVINLoaded" 133 "a133_alarmTriggered" 121 "a121_ICR_MIA" 120 "a120_DI_DRIVE_MIA" 119 "a119_SCCM_MIA" 118 "a118_VCFRONT_MIA" 117 "a117_VCLEFT_MIA" 116 "a116_VCRIGHT_MIA" 115 "a115_VCSEC_MIA" 114 "a114_ESP_MIA" 113 "a113_UI_MIA" 112 "a112_EPBL_MIA" 111 "a111_EPBR_MIA" 110 "a110_GTW_MIA" 109 "a109_RCM_MIA" 108 "a108_DIF_MIA" 107 "a107_BMS_MIA" 106 "a106_PCS_MIA" 105 "a105_TAS_MIA" 104 "a104_DAS_MIA" 103 "a103_CP_MIA" 102 "a102_PTC_MIA" 101 "a101_PM_MIA" 100 "a100_CANbus_MIA" 99 "a099_PARK_MIA" 98 "a098_DIR_MIA" 97 "a097_CMP_MIA" 96 "a096_OCS1P_MIA" 95 "a095_CHG_MIA" 94 "a094_EPAS3P_MIA" 93 "a093_VCSEATP_MIA" 92 "a092_VCSEATD_MIA" 91 "a091_CMPD_MIA" 90 "a090_APS_MIA" 89 "a089_IBST_MIA" 88 "a088_DIRER_MIA" 87 "a087_DIREL_MIA" 86 "a086_VCBATT_MIA" 85 "a085_CCCM_MIA" 84 "a084_TPMS_MIA" 83 "a083_VCLEFT_IPC_MIA" 82 "a082_VCRIGHT_IPC_MIA" 64 "a064_busSleepReqTimeout" 63 "a063_SwitchFault" 62 "a062_XCPWasConnected" 61 "a061_XCPConnected" 60 "a060_engineeringBuild" 59 "a059_inputResistanceHigh" 58 "a058_inputRHighSyncDebug" 57 "a057_HVP_MIA" 46 "a046_Task1000msError" 45 "a045_Task100msError" 44 "a044_Task10msError" 43 "a043_Task1msError" 42 "a042_HighStackUsage" 41 "a041_HighCPULoad" 31 "a031_UDSActive" 30 "a030_ECULogUploadRequest" 29 "a029_CoreDump" 22 "a022_TaskInitError" 21 "a021_TaskSchedulerError" 17 "a017_NVMMStatusDbg" 16 "a016_NVMMRecordError" 15 "a015_NVMMError" 13 "a013_AlertManagerFault" 12 "a012_CPUReset" 10 "a010_ExtSupplyVoltError" 6 "a006_CANTX_cyclicError" 5 "a005_CANTXError" 3 "a003_SWAssertion" 2 "a002_PowerLossReset" 1 "a001_WatchdogReset" 0 "ALERT_DO_NOT_USE_ZERO" ;
VAL_ 1328 VCSEC_alertState 1 "SET" 0 "CLEARED" ;
VAL_ 1328 VCSEC_a133_alarmTriggerReason 14 "TAILGATE" 13 "TRAILER_DISCONNECT" 12 "TONNEAU" 11 "RADAR" 10 "POWERED_UP_TRIGGERED" 9 "NOT_TRIGGERED" 8 "SENTRY_REQUEST" 7 "TILT_SENSOR" 6 "ULTRASONIC" 5 "REAR_TRUNK" 4 "FRONT_TRUNK" 3 "REAR_PASSENGER_DOOR" 2 "REAR_DRIVER_DOOR" 1 "FRONT_PASSENGER_DOOR" 0 "FRONT_DRIVER_DOOR" ;
VAL_ 1328 VCSEC_a177_keyRole 10 "PREDELIVERY_KEY" 9 "RIDER_KEY" 8 "GUEST_KEY" 7 "SERVICE_TECH_KEY" 6 "CHARGING_MANAGER_KEY" 5 "VEHICLE_MONITOR_KEY" 4 "FM_KEY" 3 "DRIVER_KEY" 2 "OWNER_KEY" 1 "SERVICE_KEY" 0 "NONE" ;
VAL_ 1328 VCSEC_a178_removedKeyRole 10 "PREDELIVERY_KEY" 9 "RIDER_KEY" 8 "GUEST_KEY" 7 "SERVICE_TECH_KEY" 6 "CHARGING_MANAGER_KEY" 5 "VEHICLE_MONITOR_KEY" 4 "FM_KEY" 3 "DRIVER_KEY" 2 "OWNER_KEY" 1 "SERVICE_KEY" 0 "NONE" ;
VAL_ 1328 VCSEC_a211_handlePulled 10 "UNKNOWN" 8 "AUTOPRESENT_PASSENGER" 7 "AUTOPRESENT_DRIVER" 6 "FRUNK" 5 "CHARGEPORT" 4 "TRUNK" 3 "REARPASSENGER" 2 "REARDRIVER" 1 "FRONTPASSENGER" 0 "FRONTDRIVER" ;
VAL_ 1328 VCSEC_a211_MaximumRSSIAntenna 11 "NONE" 10 "FRONTRIGHT" 9 "FRONTLEFT" 8 "REARRIGHT" 7 "REARLEFT" 6 "NFCCRADLE" 5 "SECONDARY" 4 "FRONT" 3 "CENTER" 2 "REAR" 1 "RIGHT" 0 "LEFT" ;
VAL_ 1328 VCSEC_a221_homologationRegion 3 "CHINA" 2 "EUROPE" 1 "NORTHAMERICA" 0 "UNKNOWN" ;
VAL_ 1328 VCSEC_a256_whitelistOperation 13 "SET_INFOTAINMENT_KEY" 12 "REPLACE_KEY" 11 "REMOVE_IMPERMANENT_KEYS" 10 "REPLACE_IMPERMANENT_KEYS" 9 "ADD_IMPERMANENT_KEY" 8 "AWAIT_LOCAL_ENTITY_AUTH_COMPLETE" 2 "REMOVE_PUBLIC_KEY" 1 "ADD_PUBLIC_KEY" 0 "IDLE" ;
VAL_ 1328 VCSEC_a256_failureReason 63 "UNKNOWN" 34 "SERVICE_KEY_ATTEMPTING_TO_ADD_PREDELIVERY_KEY_WHEN_ALREADY_DELIVERED" 33 "NON_SERVICE_KEY_ATTEMPTING_TO_ADD_RIDER_KEY" 32 "ATTEMPTING_TO_ADD_RIDER_KEY_OUTSIDE_FLEET_MODE" 31 "NON_SERVICE_KEY_ATTEMPTING_TO_ADD_PREDELIVERY_KEY" 30 "LOCAL_ENTITY_AUTH_FAILED_CANCELLED" 29 "LOCAL_ENTITY_AUTH_FAILED_VALET_MODE" 28 "LOCAL_ENTITY_AUTH_FAILED_TIMED_OUT_WAITING_FOR_UI_ACK" 27 "LOCAL_ENTITY_AUTH_FAILED_TIMED_OUT_WAITING_FOR_TAP" 26 "LOCAL_ENTITY_AUTH_FAILED_UI_DENIED" 25 "COULD_NOT_START_LOCAL_ENTITY_AUTH" 24 "NON_SERVICE_KEY_ATTEMPTING_TO_ADD_SERVICE_TECH" 23 "SERVICE_KEY_ATTEMPTING_TO_ADD_SERVICE_TECH_OUTSIDE_SERVICE_MODE" 22 "ATTEMPTING_TO_ADD_KEY_WITH_SERVICE_ROLE" 21 "ATTEMPTING_TO_ADD_KEY_WITHOUT_ROLE" 20 "KEYCHAIN_WHILE_FS_FULL" 19 "FM_MODIFYING_OUTSIDE_OF_F_MODE" 18 "FM_ATTEMPTING_TO_ADD_PERMANENT_KEY" 17 "FM_ATTEMPTING_TO_REMOVE_PERMANENT_KEY" 16 "ATTEMPTING_TO_ADD_KEY_THAT_IS_NOT_ON_READER" 15 "ATTEMPTING_TO_ADD_KEY_THAT_IS_ALREADY_ON_THE_WHITELIST" 14 "ATTEMPTING_TO_UPDATE_TIME_ON_OWN_PERMISSIONS" 13 "TIMER_NOT_RUNNING" 12 "COULD_NOT_START_TIMER" 11 "COMPONENT_SPECIFIC" 10 "KEYCHAN_FULL" 9 "KEY_NOT_ON_WHITELIST" 8 "ATTEMPTING_TO_DEMOTE_OTHER_TO_ONESELF" 7 "ATTEMPTING_TO_REMOVE_OWN_PERMISSIONS" 6 "ATTEMPTING_TO_ELEVATE_OTHER_ABOVE_ONSELF" 5 "NO_PERMISSION_TO_REMOVE_ONESELF" 4 "NO_PERMISSION_TO_CHANGE_PERMISSIONS" 3 "NO_PERMISSION_TO_REMOVE" 2 "NO_PERMISSION_TO_ADD" 1 "INVALID_KEY" 0 "NONE" ;
VAL_ 1328 VCSEC_a497_endpointLocationToFix 11 "NONE" 10 "FRONTRIGHT" 9 "FRONTLEFT" 8 "REARRIGHT" 7 "REARLEFT" 6 "NFCCRADLE" 5 "SECONDARY" 4 "FRONT" 3 "CENTER" 2 "REAR" 1 "RIGHT" 0 "LEFT" ;
